VERSION ""

NS_ :

BS_:

BU_: Skylark_EV

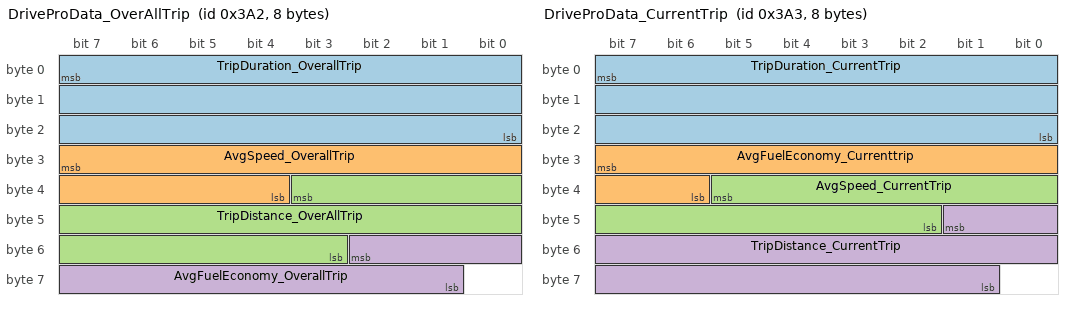
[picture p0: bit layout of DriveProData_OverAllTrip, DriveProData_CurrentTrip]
BO_ 930 DriveProData_OverAllTrip: 8 Vector__XXX
 SG_ TripDuration_OverallTrip : 7|24@0+ (1,0) [0|3600000] "sec"  Skylark_EV
 SG_ AvgSpeed_OverallTrip : 31|12@0+ (0.03125,0) [0|127.96875] "m/s"  Skylark_EV
 SG_ TripDistance_OverAllTrip : 35|17@0+ (0.1,0) [0|9999.9] "Km"  Skylark_EV
 SG_ AvgFuelEconomy_OverallTrip : 50|10@0+ (0.1,0) [0|99.9] "Km/L"  Skylark_EV

BO_ 931 DriveProData_CurrentTrip: 8 Vector__XXX
 SG_ TripDuration_CurrentTrip : 7|24@0+ (1,0) [0|3600000] "sec"  Skylark_EV
 SG_ AvgFuelEconomy_Currenttrip : 31|10@0+ (0.1,0) [0|99.9] "Km/L"  Skylark_EV
 SG_ AvgSpeed_CurrentTrip : 37|12@0+ (0.03125,0) [0|127.96875] "m/s"  Skylark_EV
 SG_ TripDistance_CurrentTrip : 41|17@0+ (0.1,0) [0|9999.9] "Km"  Skylark_EV

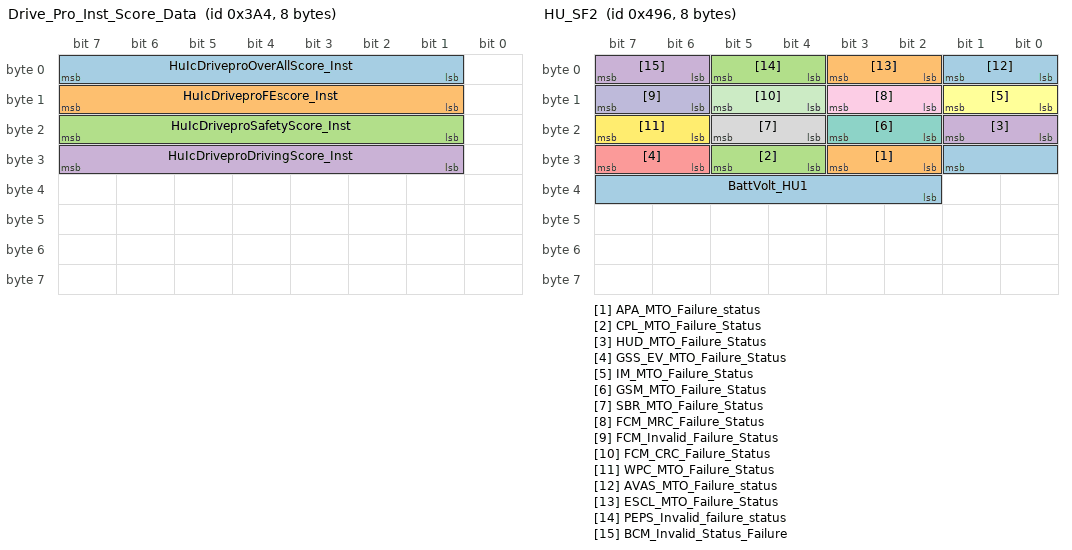
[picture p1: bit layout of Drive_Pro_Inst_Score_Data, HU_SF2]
BO_ 932 Drive_Pro_Inst_Score_Data: 8 Skylark_EV
 SG_ HuIcDriveproOverAllScore_Inst : 7|7@0+ (0.1,0) [0|10] "" Vector__XXX
 SG_ HuIcDriveproFEscore_Inst : 15|7@0+ (0.1,0) [0|10] "" Vector__XXX
 SG_ HuIcDriveproSafetyScore_Inst : 23|7@0+ (0.1,0) [0|10] "" Vector__XXX
 SG_ HuIcDriveproDrivingScore_Inst : 31|7@0+ (0.1,0) [0|10] "" Vector__XXX

BO_ 938 PEPS2_RC: 8 Vector__XXX
 SG_ LowBatUIdMsg : 2|1@0+ (1,0) [0|1] ""  Skylark_EV

BO_ 946 BCM_IC_RC4: 8 Vector__XXX
 SG_ HighBeamTelltaleStatus : 35|2@0+ (1,0) [0|3] ""  Skylark_EV
 SG_ HighBeamTelltale : 33|1@0+ (1,0) [0|1] ""  Skylark_EV
 SG_ DoorStateRearLHStatus : 1|2@0+ (1,0) [0|3] ""  Skylark_EV
 SG_ DoorStatePassStatus : 3|2@0+ (1,0) [0|3] ""  Skylark_EV
 SG_ DoorStatePass : 4|1@0+ (1,0) [0|1] ""  Skylark_EV
 SG_ DoorStateDrvrStatus : 6|2@0+ (1,0) [0|3] ""  Skylark_EV
 SG_ DoorStateDrvr : 7|1@0+ (1,0) [0|1] ""  Skylark_EV
 SG_ DoorStateRearRH : 8|1@0+ (1,0) [0|1] ""  Skylark_EV
 SG_ DoorStateRearRHStatus : 10|2@0+ (1,0) [0|3] ""  Skylark_EV
 SG_ DoorStateRearLH : 11|1@0+ (1,0) [0|1] ""  Skylark_EV
 SG_ WiperState : 14|3@0+ (1,0) [0|7] ""  Skylark_EV
 SG_ TailgateState : 15|1@0+ (1,0) [0|1] ""  Skylark_EV
 SG_ WiperStateStatus : 17|2@0+ (1,0) [0|3] ""  Skylark_EV
 SG_ TailgateStateStatus : 19|2@0+ (1,0) [0|3] ""  Skylark_EV
 SG_ PositionLmpMalFn : 20|1@0+ (1,0) [0|1] ""  Skylark_EV
 SG_ PositionLmpMalFnStatus : 23|2@0+ (1,0) [0|3] ""  Skylark_EV
 SG_ BrakeLmpMalFn : 24|1@0+ (1,0) [0|1] ""  Skylark_EV
 SG_ BrakeLmpMalFnStatus : 26|2@0+ (1,0) [0|3] ""  Skylark_EV
 SG_ RevLampMalFn : 27|1@0+ (1,0) [0|1] ""  Skylark_EV
 SG_ RevLampMalFnStatus : 29|2@0+ (1,0) [0|3] ""  Skylark_EV
 SG_ LowBeamMalFn : 32|1@0+ (1,0) [0|1] ""  Skylark_EV
 SG_ DRLTelltale : 36|1@0+ (1,0) [0|1] ""  Skylark_EV
 SG_ FrontFogTelltale : 37|1@0+ (1,0) [0|1] ""  Skylark_EV
 SG_ RearFogTelltaleStatus : 39|2@0+ (1,0) [0|3] ""  Skylark_EV
 SG_ FrontFogTelltaleStatus : 41|2@0+ (1,0) [0|3] ""  Skylark_EV
 SG_ DRLTelltaleStatus : 43|2@0+ (1,0) [0|3] ""  Skylark_EV
 SG_ LowBeamMalFnStatus : 52|2@0+ (1,0) [0|3] ""  Skylark_EV
 SG_ BonnetState : 54|1@0+ (1,0) [0|1] ""  Skylark_EV
 SG_ RearFogTelltale : 55|1@0+ (1,0) [0|1] ""  Skylark_EV
 SG_ BonnetStateStatus : 57|2@0+ (1,0) [0|3] ""  Skylark_EV

BO_ 948 IPC12: 8 Vector__XXX
 SG_ OdoICFullSigPeriodic : 7|32@0+ (1,0) [0|999999000] "m"  Skylark_EV
 SG_ OdoICFullSigPeriodicStatus : 33|2@0+ (1,0) [0|3] ""  Skylark_EV

BO_ 1068 IPC7: 8 Vector__XXX
 SG_ ICDrvModeFunVariant : 47|16@0+ (1,0) [0|65535] ""  Skylark_EV

BO_ 1069 IPC9: 8 Vector__XXX
 SG_ IcHuVcInfonew : 7|64@0+ (1,0) [0|1.8446744074E+019] ""  Skylark_EV

BO_ 1120 HU6: 8 Skylark_EV
 SG_ HuIcTpSig : 7|64@0+ (1,0) [0|1.844674407371E+019] "" Vector__XXX

BO_ 1121 IPC13: 8 Vector__XXX
 SG_ IcHuTpSig : 7|64@0+ (1,0) [0|1.844674407371E+019] ""  Skylark_EV

BO_ 1173 HU_SF: 8 Skylark_EV
 SG_ SRR_MTO_Failure_Status : 63|2@0+ (1,0) [0|3] "" Vector__XXX
 SG_ FCmMToFailureStatus : 35|2@0+ (1,0) [0|3] "" Vector__XXX
 SG_ Telematics_Invalid_FailureStatus : 29|2@0+ (1,0) [0|3] "" Vector__XXX
 SG_ VCUMToFailureStatus : 19|2@0+ (1,0) [0|3] "" Vector__XXX
 SG_ VCUInvalidFailureStatus : 23|2@0+ (1,0) [0|3] "" Vector__XXX
 SG_ Telematics_MTO_Failure_status : 13|2@0+ (1,0) [0|3] "" Vector__XXX
 SG_ HU_SW_Version : 7|8@0+ (1,0) [0|255] "" Vector__XXX
 SG_ EMsInvalidFailureStatus : 9|2@0+ (1,0) [0|3] "" Vector__XXX
 SG_ AMT_AT_DCT_MTO_Failure_Status : 11|2@0+ (1,0) [0|3] "" Vector__XXX
 SG_ AMT_AT_DCT_Invalid_Failure_Statu : 15|2@0+ (1,0) [0|3] "" Vector__XXX
 SG_ ESpMToFailureStatus : 17|2@0+ (1,0) [0|3] "" Vector__XXX
 SG_ ESpInvalidFailureStatus : 21|2@0+ (1,0) [0|3] "" Vector__XXX
 SG_ CCM_Invalid_Failure_Status : 25|2@0+ (1,0) [0|3] "" Vector__XXX
 SG_ SRS_MTO_Failure_Status : 27|2@0+ (1,0) [0|3] "" Vector__XXX
 SG_ EMsMToFailureStatus : 31|2@0+ (1,0) [0|3] "" Vector__XXX
 SG_ PDC_MTO_Failure_Status : 33|2@0+ (1,0) [0|3] "" Vector__XXX
 SG_ IPcMToFailureStatus : 37|2@0+ (1,0) [0|3] "" Vector__XXX
 SG_ IPcInvalidFailureStatus : 39|2@0+ (1,0) [0|3] "" Vector__XXX
 SG_ PDC_Invalid_Failure_Status : 41|2@0+ (1,0) [0|3] "" Vector__XXX
 SG_ SAS_Invalid_Failure_Status : 43|2@0+ (1,0) [0|3] "" Vector__XXX
 SG_ SAS_MTO_Failure_Status : 45|2@0+ (1,0) [0|3] "" Vector__XXX
 SG_ EPAS_MTO_Failure_Status : 47|2@0+ (1,0) [0|3] "" Vector__XXX
 SG_ EPAS_Invalid_Failure_Status : 49|2@0+ (1,0) [0|3] "" Vector__XXX
 SG_ TPMS_MTO_Failure_status : 51|2@0+ (1,0) [0|3] "" Vector__XXX
 SG_ CCM_MTO_Failure_Status : 53|2@0+ (1,0) [0|3] "" Vector__XXX
 SG_ HU_EP_Failure_Status : 55|2@0+ (1,0) [0|3] "" Vector__XXX
 SG_ PEPS_MTO_Failure_Status : 57|2@0+ (1,0) [0|3] "" Vector__XXX
 SG_ BCmMToFailureStatus : 59|2@0+ (1,0) [0|3] "" Vector__XXX
 SG_ HU_BO_Failure_Status : 61|2@0+ (1,0) [0|3] "" Vector__XXX

BO_ 1174 HU_SF2: 8 Skylark_EV
 SG_ BattVolt_HU1 : 25|8@0+ (0.1,0) [0|25] "Volts" Vector__XXX
 SG_ APA_MTO_Failure_status : 27|2@0+ (1,0) [0|3] "" Vector__XXX
 SG_ CPL_MTO_Failure_Status : 29|2@0+ (1,0) [0|3] "" Vector__XXX
 SG_ HUD_MTO_Failure_Status : 17|2@0+ (1,0) [0|3] "" Vector__XXX
 SG_ GSS_EV_MTO_Failure_Status : 31|2@0+ (1,0) [0|3] "" Vector__XXX
 SG_ IM_MTO_Failure_Status : 9|2@0+ (1,0) [0|3] "" Vector__XXX
 SG_ GSM_MTO_Failure_Status : 19|2@0+ (1,0) [0|3] "" Vector__XXX
 SG_ SBR_MTO_Failure_Status : 21|2@0+ (1,0) [0|3] "" Vector__XXX
 SG_ FCM_MRC_Failure_Status : 11|2@0+ (1,0) [0|3] "" Vector__XXX
 SG_ FCM_Invalid_Failure_Status : 15|2@0+ (1,0) [0|3] "" Vector__XXX
 SG_ FCM_CRC_Failure_Status : 13|2@0+ (1,0) [0|3] "" Vector__XXX
 SG_ WPC_MTO_Failure_Status : 23|2@0+ (1,0) [0|3] "" Vector__XXX
 SG_ AVAS_MTO_Failure_status : 1|2@0+ (1,0) [0|3] "" Vector__XXX
 SG_ ESCL_MTO_Failure_Status : 3|2@0+ (1,0) [0|3] "" Vector__XXX
 SG_ PEPS_Invalid_failure_status : 5|2@0+ (1,0) [0|3] "" Vector__XXX
 SG_ BCM_Invalid_Status_Failure : 7|2@0+ (1,0) [0|3] "" Vector__XXX

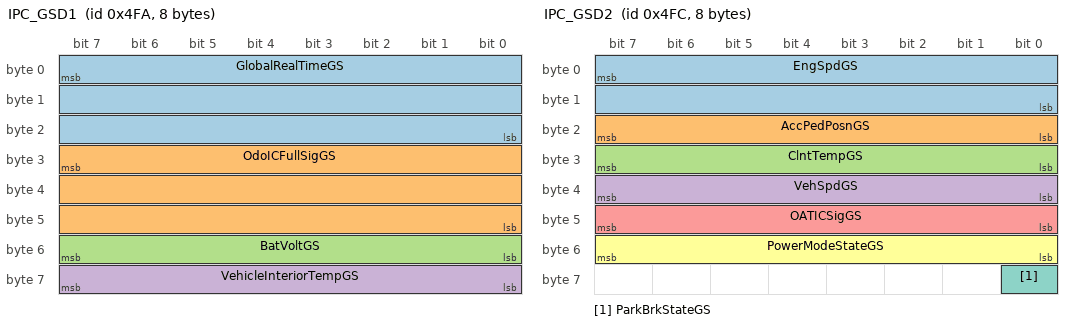
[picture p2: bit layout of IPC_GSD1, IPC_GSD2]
BO_ 1274 IPC_GSD1: 8 Vector__XXX
 SG_ GlobalRealTimeGS : 7|24@0+ (1,0) [0|16777214] "min"  Skylark_EV
 SG_ OdoICFullSigGS : 31|24@0+ (1,0) [0|16777214] "km"  Skylark_EV
 SG_ BatVoltGS : 55|8@0+ (0.1,0) [0|25.4] "V"  Skylark_EV
 SG_ VehicleInteriorTempGS : 63|8@0+ (1,-40) [-40|214] "Deg"  Skylark_EV

BO_ 1276 IPC_GSD2: 8 Vector__XXX
 SG_ EngSpdGS : 7|16@0+ (1,0) [0|65534] "rpm"  Skylark_EV
 SG_ AccPedPosnGS : 23|8@0+ (0.5,0) [0|127] "%"  Skylark_EV
 SG_ ClntTempGS : 31|8@0+ (1,-40) [-40|214] "Deg"  Skylark_EV
 SG_ VehSpdGS : 39|8@0+ (1,0) [0|254] "km/h"  Skylark_EV
 SG_ OATICSigGS : 47|8@0+ (1,-40) [-40|214] "Deg"  Skylark_EV
 SG_ PowerModeStateGS : 55|8@0+ (1,0) [0|255] ""  Skylark_EV
 SG_ ParkBrkStateGS : 56|1@0+ (1,0) [0|1] ""  Skylark_EV

BO_ 1278 IPC_GSD3: 8 Vector__XXX
 SG_ VehIdetNumGS : 7|40@0+ (1,0) [0|0] ""  Skylark_EV

BO_ 1280 BCM_NMPDU: 8 Vector__XXX
 SG_ BCM_NMPDU_SRC_ECU_ID : 7|8@0+ (1,0) [0|255] ""  Skylark_EV
 SG_ RepeatMessageReq_BCM : 8|1@0+ (1,0) [0|1] ""  Skylark_EV
 SG_ Reserved0 : 9|1@0+ (1,0) [0|1] ""  Skylark_EV
 SG_ Reserved1 : 10|1@0+ (1,0) [0|1] ""  Skylark_EV
 SG_ NMCoOrdSlpReady_BCM : 11|1@0+ (1,0) [0|1] ""  Skylark_EV
 SG_ ActiveWakeUp_BCM : 12|1@0+ (1,0) [0|1] ""  Skylark_EV
 SG_ Reserved2 : 13|1@0+ (1,0) [0|1] ""  Skylark_EV
 SG_ PartialNetworkInformation_BCM : 14|1@0+ (1,0) [0|1] ""  Skylark_EV
 SG_ Reserved3 : 15|1@0+ (1,0) [0|1] ""  Skylark_EV
 SG_ CurrentState_BCM : 16|1@0+ (1,0) [0|1] ""  Skylark_EV
 SG_ PreviousState_BCM : 19|3@0+ (1,0) [0|7] ""  Skylark_EV
 SG_ Reserved4 : 20|1@0+ (1,0) [0|1] ""  Skylark_EV
 SG_ Reserved5 : 21|1@0+ (1,0) [0|1] ""  Skylark_EV
 SG_ Reserved6 : 22|1@0+ (1,0) [0|1] ""  Skylark_EV
 SG_ Reserved7 : 23|1@0+ (1,0) [0|1] ""  Skylark_EV
 SG_ BCM_NMPDU_USER_DATA_D1 : 31|8@0+ (1,0) [0|255] ""  Skylark_EV
 SG_ BCM_NMPDU_USER_DATA_D2 : 39|8@0+ (1,0) [0|255] ""  Skylark_EV
 SG_ BCM_NMPDU_USER_DATA_D3 : 47|8@0+ (1,0) [0|255] ""  Skylark_EV
 SG_ BCM_NMPDU_USER_DATA_D4 : 55|8@0+ (1,0) [0|255] ""  Skylark_EV
 SG_ BCM_NMPDU_USER_DATA_D5 : 63|8@0+ (1,0) [0|255] ""  Skylark_EV

BO_ 1282 HU_NMPDU: 8 Skylark_EV
 SG_ HU_NMPDU_SRC_ECU_ID : 7|8@0+ (1,0) [0|255] "" Vector__XXX
 SG_ RepeatMessageReq_HU : 8|1@0+ (1,0) [0|1] "" Vector__XXX
 SG_ Reserved8 : 9|1@0+ (1,0) [0|1] "" Vector__XXX
 SG_ Reserved9 : 10|1@0+ (1,0) [0|1] "" Vector__XXX
 SG_ NMCoOrdSlpReady_HU : 11|1@0+ (1,0) [0|1] "" Vector__XXX
 SG_ ActiveWakeUp_HU : 12|1@0+ (1,0) [0|1] "" Vector__XXX
 SG_ Reserved10 : 13|1@0+ (1,0) [0|1] "" Vector__XXX
 SG_ PartialNetworkInformation_HU : 14|1@0+ (1,0) [0|1] "" Vector__XXX
 SG_ Reserved11 : 15|1@0+ (1,0) [0|1] "" Vector__XXX
 SG_ CurrentState_HU : 16|1@0+ (1,0) [0|1] "" Vector__XXX
 SG_ PreviousState_HU : 19|3@0+ (1,0) [0|7] "" Vector__XXX
 SG_ Reserved12 : 20|1@0+ (1,0) [0|1] "" Vector__XXX
 SG_ Reserved13 : 21|1@0+ (1,0) [0|1] "" Vector__XXX
 SG_ Reserved14 : 22|1@0+ (1,0) [0|1] "" Vector__XXX
 SG_ Reserved15 : 23|1@0+ (1,0) [0|1] "" Vector__XXX
 SG_ HU_NMPDU_USER_DATA_1 : 31|8@0+ (1,0) [0|255] "" Vector__XXX
 SG_ HU_NMPDU_USER_DATA_2 : 39|8@0+ (1,0) [0|255] "" Vector__XXX
 SG_ HU_NMPDU_USER_DATA_3 : 47|8@0+ (1,0) [0|255] "" Vector__XXX
 SG_ HU_NMPDU_USER_DATA_4 : 55|8@0+ (1,0) [0|255] "" Vector__XXX
 SG_ HU_NMPDU_USER_DATA_5 : 63|8@0+ (1,0) [0|255] "" Vector__XXX

BO_ 1547 HU_DiagResponse_UUDT: 8 Skylark_EV
 SG_ HU_DiagResponse_UUDT : 7|64@0+ (1,0) [0|0] "" Vector__XXX

BO_ 1795 HU_DiagRequest: 8 Vector__XXX
 SG_ DiagMsg : 7|64@0+ (1,0) [0|0] ""  Skylark_EV

BO_ 1803 HU_DiagResponse_USDT: 8 Skylark_EV
 SG_ HU_DiagResponse_USDT : 7|64@0+ (1,0) [0|0] "" Vector__XXX

BO_ 2000 DiagState1: 8 Vector__XXX
 SG_ DiagMsg : 7|64@0+ (1,0) [0|0] ""  Skylark_EV

BO_ 2001 DiagState2: 8 Vector__XXX
 SG_ DiagMsg : 7|64@0+ (1,0) [0|0] ""  Skylark_EV

BO_ 2015 DiagState3: 8 Vector__XXX
 SG_ DiagMsg : 7|64@0+ (1,0) [0|0] ""  Skylark_EV

CM_ SG_ 930 TripDuration_OverallTrip "IC shall send overall Trip Duration to HU";
CM_ SG_ 930 AvgSpeed_OverallTrip "IC shall send Overall Trip  Average speed to HU";
CM_ SG_ 930 TripDistance_OverAllTrip "IC shall send Over allTrip  Distance to HU";
CM_ SG_ 930 AvgFuelEconomy_OverallTrip "IC shall send Over all trip Average  Fuel Economy to HU";
CM_ SG_ 931 TripDuration_CurrentTrip "IC shall send Current Trip Duration to HU";
CM_ SG_ 931 AvgFuelEconomy_Currenttrip "IC shall send Current Trip Fuel Economy to HU";
CM_ SG_ 931 AvgSpeed_CurrentTrip "IC shall send Current Trip Average speed to HU";
CM_ SG_ 931 TripDistance_CurrentTrip "IC shall send Current Trip Distance to HU";
CM_ SG_ 932 HuIcDriveproOverAllScore_Inst "HU shall send Overall trip Reset to IC";
CM_ SG_ 932 HuIcDriveproFEscore_Inst "Drive Pro Instantaneous Trip Data fron HU to IC";
CM_ SG_ 932 HuIcDriveproSafetyScore_Inst "Drive Pro Instantaneous Trip Data fron HU to IC";
CM_ SG_ 932 HuIcDriveproDrivingScore_Inst "Drive Pro Instantaneous score from HU to IC";
CM_ SG_ 938 LowBatUIdMsg "Display message request from PEPS to IC & HU - UID battery is low";
CM_ SG_ 946 HighBeamTelltaleStatus "Status of the High Beam Telltale";
CM_ SG_ 946 HighBeamTelltale "IC to display the high beam tell-tale when the high beam lamp is active";
CM_ SG_ 946 DoorStateRearLHStatus "Rear left side door valid Status





";
CM_ SG_ 946 DoorStatePassStatus "Driver Door Passenger valid Status";
CM_ SG_ 946 DoorStatePass "Co-Driver door switch state from BCM ";
CM_ SG_ 946 DoorStateDrvrStatus "DoorStateDrvr valid Status";
CM_ SG_ 946 DoorStateDrvr "Driver door switch state from BCM ";
CM_ SG_ 946 DoorStateRearRH "Rear right side door switch state from BCM to FATC and IC";
CM_ SG_ 946 DoorStateRearRHStatus "Rear right side door valid status



";
CM_ SG_ 946 DoorStateRearLH "Rear left side door switch state from BCM";
CM_ SG_ 946 WiperState "Status of the Wiper to various ECUs";
CM_ SG_ 946 TailgateState "Tailgate switch state (open or close) from BCM to various ECUs";
CM_ SG_ 946 WiperStateStatus "Status of the Wiper whether Valid or not";
CM_ SG_ 946 TailgateStateStatus "Tailgate switch state vaild status";
CM_ SG_ 946 PositionLmpMalFn "IC to display the message when failure in Position lamp";
CM_ SG_ 946 PositionLmpMalFnStatus "Status of the Malfunction Position Lamp";
CM_ SG_ 946 BrakeLmpMalFn "IC to display the message when failure in brake lamp";
CM_ SG_ 946 BrakeLmpMalFnStatus "Status of the Malfunction Break Lamp





";
CM_ SG_ 946 RevLampMalFn "IC to display the message when failure in reverse lamp";
CM_ SG_ 946 RevLampMalFnStatus "Status of the Malfunction Reverse Lamp";
CM_ SG_ 946 LowBeamMalFn "IC to display the message when failure in low beam lamp";
CM_ SG_ 946 DRLTelltale "IC to display the Daytime Running Light (DRL) telltale";
CM_ SG_ 946 FrontFogTelltale "IC to display the front fog tell-tale when the front fog lamp is active";
CM_ SG_ 946 RearFogTelltaleStatus "Status of the Rear Fog Telltale";
CM_ SG_ 946 FrontFogTelltaleStatus "Status of the Front Fog Telltale";
CM_ SG_ 946 DRLTelltaleStatus "Status of the Daytime Running Light (DRL) telltale";
CM_ SG_ 946 LowBeamMalFnStatus "Status of the Low Beam Malfunction";
CM_ SG_ 946 BonnetState "Bonnet switch state (open or close) from BCM";
CM_ SG_ 946 RearFogTelltale "IC to display the rear fog tell-tale when the rear fog lamp is active";
CM_ SG_ 946 BonnetStateStatus "BonnetState vaild status";
CM_ SG_ 948 OdoICFullSigPeriodic "Signal represents Odometer information in full range.";
CM_ SG_ 948 OdoICFullSigPeriodicStatus "Status of Signal representing Odometer information in full range.";
CM_ SG_ 1068 ICDrvModeFunVariant "Indicates the type of drive mode available in vehicle.";
CM_ SG_ 1069 IcHuVcInfonew "VC number of vehicle.";
CM_ BO_ 1120 "CAN TP Message";
CM_ BO_ 1121 "CAN TP Message";
CM_ BO_ 1173 "Supervision frame transmitted by HU";
CM_ SG_ 1173 SRR_MTO_Failure_Status "Status of the SRR  Message timeout  failure detected as per Tata-IVN_Specification_Network_Management.";
CM_ SG_ 1173 FCmMToFailureStatus "Status of the FCM Message timeout  failure detected as per Tata-IVN_Specification_Network_Management.";
CM_ SG_ 1173 Telematics_Invalid_FailureStatus "Status of the Telematics Invalid failure detected as per Tata-IVN_Specification_Network_Management.";
CM_ SG_ 1173 VCUMToFailureStatus "VCUMTO failure status";
CM_ SG_ 1173 VCUInvalidFailureStatus "VCU invalid failure status";
CM_ SG_ 1173 Telematics_MTO_Failure_status "Status of the Telematics Message timeout failure detected as per Tata-IVN_Specification_Network_Management.";
CM_ SG_ 1173 HU_SW_Version "SW Version of the HU ECU";
CM_ SG_ 1173 EMsInvalidFailureStatus "status of the EMS Invalid  signal  failure detected as per Tata-IVN_Specification_Network_Management.";
CM_ SG_ 1173 AMT_AT_DCT_MTO_Failure_Status "Status of the TCM Message Timeout  failure detected as per Tata-IVN_Specification_Network_Management.";
CM_ SG_ 1173 AMT_AT_DCT_Invalid_Failure_Statu "Status of the TCM invalid failure detected as per Tata-IVN_Specification_Network_Management.";
CM_ SG_ 1173 ESpMToFailureStatus "Status of the ESP  Message timeout failure detected as per Tata-IVN_Specification_Network_Management.";
CM_ SG_ 1173 ESpInvalidFailureStatus "Status of the ESP signal implausible  failure detected  by EPAS  as per  communication layer spec";
CM_ SG_ 1173 CCM_Invalid_Failure_Status "Status of the  FATC Invalid  signal  failure detected as per Tata-IVN_Specification_Network_Management.";
CM_ SG_ 1173 SRS_MTO_Failure_Status "Status of the SRS  Message timeout  failure detected as per Tata-IVN_Specification_Network_Management.";
CM_ SG_ 1173 EMsMToFailureStatus "Status of the EMS message timeout failure detected as per Tata-IVN_Specification_Network_Management.";
CM_ SG_ 1173 PDC_MTO_Failure_Status "Status of the PDC Message timeout failure detected as per Tata-IVN_Specification_Network_Management.";
CM_ SG_ 1173 IPcMToFailureStatus "Status of the IPC Message Timeout  failure detected as per Tata-IVN_Specification_Network_Management.";
CM_ SG_ 1173 IPcInvalidFailureStatus "Status of the IC Invalid  signal  failure detected as per Tata-IVN_Specification_Network_Management.";
CM_ SG_ 1173 PDC_Invalid_Failure_Status "status of the PDC Invalid  signal  failure detected as per communication layer specification.";
CM_ SG_ 1173 SAS_Invalid_Failure_Status "status of the SAS Invalid  signal  failure detected as per Tata-IVN_Specification_Network_Management.";
CM_ SG_ 1173 SAS_MTO_Failure_Status "Status of the SAS  Message timeout  failure detected as per Tata-IVN_Specification_Network_Management.";
CM_ SG_ 1173 EPAS_MTO_Failure_Status "Status of the EPAS  Message timeout failure detected as per Tata-IVN_Specification_Network_Management.";
CM_ SG_ 1173 EPAS_Invalid_Failure_Status "Status of the EPAS signal implausible  failure detected    as per  communication layer spec";
CM_ SG_ 1173 TPMS_MTO_Failure_status "Message timeout failure flag against TPMS ECU";
CM_ SG_ 1173 CCM_MTO_Failure_Status "Status of the FATC Message timeout failure detected as per Tata-IVN_Specification_Network_Management.";
CM_ SG_ 1173 HU_EP_Failure_Status "Status of the error passive detected by HU ECU as per Tata-IVN_Specification_Network_Management.";
CM_ SG_ 1173 PEPS_MTO_Failure_Status "Status of the PEPS  Message timeout  failure detected as per Tata-IVN_Specification_Network_Management.";
CM_ SG_ 1173 BCmMToFailureStatus "Status of the BCM Message timeout  failure detected as per Tata-IVN_Specification_Network_Management.";
CM_ SG_ 1173 HU_BO_Failure_Status "Status of the bus-off failure detected by HU ECU as per Tata-IVN_Specification_Network_Management";
CM_ SG_ 1174 BattVolt_HU1 "Battery voltage evaluated by HU";
CM_ SG_ 1174 APA_MTO_Failure_status "Message timeout failure flag against APA ECU";
CM_ SG_ 1174 CPL_MTO_Failure_Status "Status of the CPL Message timeout  failure detected as per Tata-IVN_Specification_Network_Management.";
CM_ SG_ 1174 HUD_MTO_Failure_Status "Status of the HUD Message timeout  failure detected as per Tata-IVN_Specification_Network_Management.";
CM_ SG_ 1174 GSS_EV_MTO_Failure_Status "Status of the GSS Message timeout  failure detected as per Tata-IVN_Specification_Network_Management.";
CM_ SG_ 1174 IM_MTO_Failure_Status "Status of the IM Message timeout  failure detected as per Tata-IVN_Specification_Network_Management.";
CM_ SG_ 1174 GSM_MTO_Failure_Status "Status of the GSM Message timeout  failure detected as per Tata-IVN_Specification_Network_Management.";
CM_ SG_ 1174 SBR_MTO_Failure_Status "Status of the SBR Message timeout  failure detected as per Tata-IVN_Specification_Network_Management.";
CM_ SG_ 1174 FCM_Invalid_Failure_Status "Status of the FCM signal implausible  failure detected  by CDC as per  communication layer spec";
CM_ SG_ 1174 WPC_MTO_Failure_Status "Status of the WPC Message timeout  failure detected as per Tata-IVN_Specification_Network_Management.";
CM_ SG_ 1174 AVAS_MTO_Failure_status "Message timeout failure flag against AVAS ECU";
CM_ SG_ 1174 PEPS_Invalid_failure_status "Status of the PEPS invalid failure detected as per Tata-IVN_Specification_Network_Management.";
CM_ SG_ 1174 BCM_Invalid_Status_Failure "Invalid data reception from BCM ECU failure flag";
CM_ SG_ 1274 GlobalRealTimeGS "Global Real Time
";
CM_ SG_ 1274 OdoICFullSigGS "Total Distance Travelled";
CM_ SG_ 1274 BatVoltGS "Supply Voltage of Instrument Cluster";
CM_ SG_ 1274 VehicleInteriorTempGS "Vehicle Interior Temperature
";
CM_ SG_ 1276 EngSpdGS "Engine RPM signal will be transmitted by EMS
";
CM_ SG_ 1276 AccPedPosnGS "Throttle Position";
CM_ SG_ 1276 ClntTempGS "Engine Coolant Temperature";
CM_ SG_ 1276 VehSpdGS "Vehicle Speed";
CM_ SG_ 1276 OATICSigGS "Ambient Air Temperature";
CM_ SG_ 1276 PowerModeStateGS "Vehicle power mode signal shall be used by all ECUs of the vehicle for their respective functional implementation";
CM_ SG_ 1276 ParkBrkStateGS "Signal represents Status of ParkBrake";
CM_ SG_ 1278 VehIdetNumGS "Vehicle Identification Number - Last 5 digits of VIN";
BA_DEF_ SG_  "Remarks" STRING ;
BA_DEF_ SG_  "NWM_WakeupAllowed" ENUM  "No","Yes";
BA_DEF_ SG_  "GenSigTimeoutTime_HU_Mid_X451" INT 0 65535;
BA_DEF_ SG_  "GenSigTimeoutTime_HU_High_X451" INT 0 65535;
BA_DEF_ SG_  "GenSigTimeoutTime_HU_B" INT 0 65535;
BA_DEF_ SG_  "GenSigTimeoutTime_HU_A" INT 0 65535;
BA_DEF_ SG_  "GenSigTimeoutTime_BCM_Mid" INT 0 65535;
BA_DEF_ SG_  "GenSigTimeoutMsg_HU_Mid_X451" INT 0 65535;
BA_DEF_ SG_  "GenSigTimeoutMsg_HU_High_X451" INT 0 65535;
BA_DEF_ SG_  "GenSigTimeoutMsg_HU_B" INT 0 65535;
BA_DEF_ SG_  "GenSigTimeoutMsg_HU_A" INT 0 65535;
BA_DEF_ SG_  "GenSigStartValue" INT 0 0;
BA_DEF_ SG_  "GenSigSendType" ENUM  "Cyclic","OnWrite","OnWriteWithRepetition","OnChange","OnChangeWithRepetition","IfActive","IfActiveWithRepetition","NoSigSendType","NotUsed","NotUsed","NotUsed","NotUsed","NotUsed";
BA_DEF_ SG_  "GenSigInactiveValue" INT 0 0;
BA_DEF_ SG_  "GenSigEnvVarType" ENUM  "int","float","undef";
BA_DEF_ SG_  "GenSigCycleTimeActive" INT 0 0;
BA_DEF_ SG_  "GenSigCycleTime" INT 0 0;
BA_DEF_ SG_  "GenSigTimeoutMsg_HU_High_X445" INT 0 65535;
BA_DEF_ SG_  "GenSigTimeoutMsg_HU_Mid_X445" INT 0 65535;
BA_DEF_ SG_  "GenSigTimeoutTime_HU_High_X445" INT 0 65535;
BA_DEF_ SG_  "GenSigTimeoutTime_HU_Mid_X445" INT 0 65535;
BA_DEF_ SG_  "GenSigTimeoutMsg_IVI" INT 0 65535;
BA_DEF_ SG_  "GenSigTimeoutTime_IVI" INT 0 65535;
BA_DEF_ BO_  "NmMessage" ENUM  "no","yes";
BA_DEF_ BO_  "NmAsrMessage" ENUM  "<n.a.>","No","Yes";
BA_DEF_ BO_  "MessageTimeout" INT 0 65535;
BA_DEF_ BO_  "GenMsgStartDelayTime" INT 0 0;
BA_DEF_ BO_  "GenMsgSendType" ENUM  "Cyclic","NotUsed","NotUsed","NotUsed","NotUsed","NotUsed","NotUsed","IfActive","NoMsgSendType","NotUsed";
BA_DEF_ BO_  "GenMsgNrOfRepetition" INT 0 0;
BA_DEF_ BO_  "GenMsgILSupport" ENUM  "No","Yes";
BA_DEF_ BO_  "GenMsgDelayTime" INT 0 0;
BA_DEF_ BO_  "GenMsgCycleTimeFast" INT 0 0;
BA_DEF_ BO_  "GenMsgCycleTime" INT 0 0;
BA_DEF_ BO_  "DiagUudtResponse" ENUM  "false","true";
BA_DEF_ BO_  "DiagUsdtResponse" ENUM  "false","true";
BA_DEF_ BO_  "DiagState" ENUM  "No","Yes";
BA_DEF_ BO_  "DiagResponse" ENUM  "No","Yes";
BA_DEF_ BO_  "DiagRequest" ENUM  "No","Yes";
BA_DEF_ BO_  "MsgType" ENUM  "Application","NM","NMH";
BA_DEF_ SG_  "SystemSignalLongSymbol" STRING ;
BA_DEF_DEF_  "Remarks" "null";
BA_DEF_DEF_  "NWM_WakeupAllowed" "No";
BA_DEF_DEF_  "GenSigTimeoutTime_HU_Mid_X451" 500;
BA_DEF_DEF_  "GenSigTimeoutTime_HU_High_X451" 500;
BA_DEF_DEF_  "GenSigTimeoutTime_HU_B" 500;
BA_DEF_DEF_  "GenSigTimeoutTime_HU_A" 500;
BA_DEF_DEF_  "GenSigTimeoutTime_BCM_Mid" 0;
BA_DEF_DEF_  "GenSigTimeoutMsg_HU_Mid_X451" 500;
BA_DEF_DEF_  "GenSigTimeoutMsg_HU_High_X451" 500;
BA_DEF_DEF_  "GenSigTimeoutMsg_HU_B" 500;
BA_DEF_DEF_  "GenSigTimeoutMsg_HU_A" 500;
BA_DEF_DEF_  "GenSigStartValue" 0;
BA_DEF_DEF_  "GenSigSendType" "Cyclic";
BA_DEF_DEF_  "GenSigInactiveValue" 0;
BA_DEF_DEF_  "GenSigEnvVarType" "undef";
BA_DEF_DEF_  "GenSigCycleTimeActive" 0;
BA_DEF_DEF_  "GenSigCycleTime" 0;
BA_DEF_DEF_  "GenSigTimeoutMsg_HU_High_X445" 500;
BA_DEF_DEF_  "GenSigTimeoutMsg_HU_Mid_X445" 500;
BA_DEF_DEF_  "GenSigTimeoutTime_HU_High_X445" 500;
BA_DEF_DEF_  "GenSigTimeoutTime_HU_Mid_X445" 500;
BA_DEF_DEF_  "GenSigTimeoutMsg_IVI" 500;
BA_DEF_DEF_  "GenSigTimeoutTime_IVI" 500;
BA_DEF_DEF_  "NmMessage" "no";
BA_DEF_DEF_  "NmAsrMessage" "<n.a.>";
BA_DEF_DEF_  "MessageTimeout" 500;
BA_DEF_DEF_  "GenMsgStartDelayTime" 0;
BA_DEF_DEF_  "GenMsgSendType" "Cyclic";
BA_DEF_DEF_  "GenMsgNrOfRepetition" 0;
BA_DEF_DEF_  "GenMsgILSupport" "Yes";
BA_DEF_DEF_  "GenMsgDelayTime" 0;
BA_DEF_DEF_  "GenMsgCycleTimeFast" 0;
BA_DEF_DEF_  "GenMsgCycleTime" 0;
BA_DEF_DEF_  "DiagUudtResponse" "false";
BA_DEF_DEF_  "DiagUsdtResponse" "false";
BA_DEF_DEF_  "DiagState" "No";
BA_DEF_DEF_  "DiagResponse" "No";
BA_DEF_DEF_  "DiagRequest" "No";
BA_DEF_DEF_  "MsgType" "Application";
BA_DEF_DEF_  "SystemSignalLongSymbol" "";
BA_ "MessageTimeout" BO_ 930 2500;
BA_ "GenMsgCycleTime" BO_ 930 500;
BA_ "MessageTimeout" BO_ 931 2500;
BA_ "GenMsgCycleTime" BO_ 931 500;
BA_ "MessageTimeout" BO_ 932 2500;
BA_ "GenMsgCycleTime" BO_ 932 500;
BA_ "MessageTimeout" BO_ 938 2500;
BA_ "GenMsgStartDelayTime" BO_ 938 5;
BA_ "GenMsgCycleTime" BO_ 938 500;
BA_ "MessageTimeout" BO_ 946 2500;
BA_ "GenMsgCycleTime" BO_ 946 500;
BA_ "MessageTimeout" BO_ 948 2500;
BA_ "GenMsgCycleTime" BO_ 948 500;
BA_ "MessageTimeout" BO_ 1068 5000;
BA_ "GenMsgCycleTime" BO_ 1068 1000;
BA_ "MessageTimeout" BO_ 1069 5000;
BA_ "GenMsgCycleTime" BO_ 1069 1000;
BA_ "MessageTimeout" BO_ 1120 0;
BA_ "GenMsgSendType" BO_ 1120 8;
BA_ "GenMsgILSupport" BO_ 1120 0;
BA_ "DiagRequest" BO_ 1120 1;
BA_ "MessageTimeout" BO_ 1121 0;
BA_ "GenMsgSendType" BO_ 1121 8;
BA_ "GenMsgILSupport" BO_ 1121 0;
BA_ "DiagResponse" BO_ 1121 1;
BA_ "MessageTimeout" BO_ 1173 0;
BA_ "GenMsgCycleTime" BO_ 1173 100;
BA_ "MessageTimeout" BO_ 1174 0;
BA_ "GenMsgCycleTime" BO_ 1174 100;
BA_ "MessageTimeout" BO_ 1274 5000;
BA_ "GenMsgCycleTime" BO_ 1274 1000;
BA_ "MessageTimeout" BO_ 1276 5000;
BA_ "GenMsgStartDelayTime" BO_ 1276 45;
BA_ "GenMsgCycleTime" BO_ 1276 1000;
BA_ "MessageTimeout" BO_ 1278 5000;
BA_ "GenMsgCycleTime" BO_ 1278 1000;
BA_ "NmMessage" BO_ 1280 1;
BA_ "NmAsrMessage" BO_ 1280 2;
BA_ "MessageTimeout" BO_ 1280 1000;
BA_ "GenMsgCycleTime" BO_ 1280 200;
BA_ "NmMessage" BO_ 1282 1;
BA_ "NmAsrMessage" BO_ 1282 2;
BA_ "MessageTimeout" BO_ 1282 1000;
BA_ "GenMsgCycleTime" BO_ 1282 200;
BA_ "MessageTimeout" BO_ 1547 0;
BA_ "GenMsgSendType" BO_ 1547 8;
BA_ "GenMsgILSupport" BO_ 1547 0;
BA_ "DiagUudtResponse" BO_ 1547 1;
BA_ "DiagResponse" BO_ 1547 1;
BA_ "MessageTimeout" BO_ 1795 0;
BA_ "GenMsgSendType" BO_ 1795 8;
BA_ "GenMsgILSupport" BO_ 1795 0;
BA_ "DiagRequest" BO_ 1795 1;
BA_ "MessageTimeout" BO_ 1803 0;
BA_ "GenMsgSendType" BO_ 1803 8;
BA_ "GenMsgILSupport" BO_ 1803 0;
BA_ "DiagResponse" BO_ 1803 1;
BA_ "MessageTimeout" BO_ 2000 0;
BA_ "GenMsgSendType" BO_ 2000 8;
BA_ "GenMsgILSupport" BO_ 2000 0;
BA_ "DiagState" BO_ 2000 1;
BA_ "MessageTimeout" BO_ 2001 0;
BA_ "GenMsgSendType" BO_ 2001 8;
BA_ "GenMsgILSupport" BO_ 2001 0;
BA_ "DiagState" BO_ 2001 1;
BA_ "MessageTimeout" BO_ 2015 0;
BA_ "GenMsgSendType" BO_ 2015 8;
BA_ "GenMsgILSupport" BO_ 2015 0;
BA_ "DiagState" BO_ 2015 1;
BA_ "GenSigTimeoutTime_HU_Mid_X451" SG_ 930 TripDuration_OverallTrip 2500;
BA_ "GenSigTimeoutTime_HU_High_X451" SG_ 930 TripDuration_OverallTrip 2500;
BA_ "GenSigTimeoutTime_HU_B" SG_ 930 TripDuration_OverallTrip 2500;
BA_ "GenSigTimeoutTime_HU_A" SG_ 930 TripDuration_OverallTrip 2500;
BA_ "GenSigTimeoutMsg_HU_Mid_X451" SG_ 930 TripDuration_OverallTrip 2500;
BA_ "GenSigTimeoutMsg_HU_High_X451" SG_ 930 TripDuration_OverallTrip 2500;
BA_ "GenSigTimeoutMsg_HU_B" SG_ 930 TripDuration_OverallTrip 2500;
BA_ "GenSigTimeoutMsg_HU_A" SG_ 930 TripDuration_OverallTrip 2500;
BA_ "GenSigSendType" SG_ 930 TripDuration_OverallTrip 7;
BA_ "GenSigCycleTimeActive" SG_ 930 TripDuration_OverallTrip 500;
BA_ "GenSigCycleTime" SG_ 930 TripDuration_OverallTrip 500;
BA_ "GenSigTimeoutMsg_HU_High_X445" SG_ 930 TripDuration_OverallTrip 2500;
BA_ "GenSigTimeoutMsg_HU_Mid_X445" SG_ 930 TripDuration_OverallTrip 2500;
BA_ "GenSigTimeoutTime_HU_High_X445" SG_ 930 TripDuration_OverallTrip 2500;
BA_ "GenSigTimeoutTime_HU_Mid_X445" SG_ 930 TripDuration_OverallTrip 2500;
BA_ "GenSigTimeoutMsg_IVI" SG_ 930 TripDuration_OverallTrip 2500;
BA_ "GenSigTimeoutTime_IVI" SG_ 930 TripDuration_OverallTrip 2500;
BA_ "GenSigTimeoutTime_HU_Mid_X451" SG_ 930 AvgSpeed_OverallTrip 2500;
BA_ "GenSigTimeoutTime_HU_High_X451" SG_ 930 AvgSpeed_OverallTrip 2500;
BA_ "GenSigTimeoutTime_HU_B" SG_ 930 AvgSpeed_OverallTrip 2500;
BA_ "GenSigTimeoutTime_HU_A" SG_ 930 AvgSpeed_OverallTrip 2500;
BA_ "GenSigTimeoutMsg_HU_Mid_X451" SG_ 930 AvgSpeed_OverallTrip 2500;
BA_ "GenSigTimeoutMsg_HU_High_X451" SG_ 930 AvgSpeed_OverallTrip 2500;
BA_ "GenSigTimeoutMsg_HU_B" SG_ 930 AvgSpeed_OverallTrip 2500;
BA_ "GenSigTimeoutMsg_HU_A" SG_ 930 AvgSpeed_OverallTrip 2500;
BA_ "GenSigSendType" SG_ 930 AvgSpeed_OverallTrip 7;
BA_ "GenSigCycleTimeActive" SG_ 930 AvgSpeed_OverallTrip 500;
BA_ "GenSigCycleTime" SG_ 930 AvgSpeed_OverallTrip 500;
BA_ "GenSigTimeoutMsg_HU_High_X445" SG_ 930 AvgSpeed_OverallTrip 2500;
BA_ "GenSigTimeoutMsg_HU_Mid_X445" SG_ 930 AvgSpeed_OverallTrip 2500;
BA_ "GenSigTimeoutTime_HU_High_X445" SG_ 930 AvgSpeed_OverallTrip 2500;
BA_ "GenSigTimeoutTime_HU_Mid_X445" SG_ 930 AvgSpeed_OverallTrip 2500;
BA_ "GenSigTimeoutMsg_IVI" SG_ 930 AvgSpeed_OverallTrip 2500;
BA_ "GenSigTimeoutTime_IVI" SG_ 930 AvgSpeed_OverallTrip 2500;
BA_ "GenSigTimeoutTime_HU_Mid_X451" SG_ 930 TripDistance_OverAllTrip 2500;
BA_ "GenSigTimeoutTime_HU_High_X451" SG_ 930 TripDistance_OverAllTrip 2500;
BA_ "GenSigTimeoutTime_HU_B" SG_ 930 TripDistance_OverAllTrip 2500;
BA_ "GenSigTimeoutTime_HU_A" SG_ 930 TripDistance_OverAllTrip 2500;
BA_ "GenSigTimeoutMsg_HU_Mid_X451" SG_ 930 TripDistance_OverAllTrip 2500;
BA_ "GenSigTimeoutMsg_HU_High_X451" SG_ 930 TripDistance_OverAllTrip 2500;
BA_ "GenSigTimeoutMsg_HU_B" SG_ 930 TripDistance_OverAllTrip 2500;
BA_ "GenSigTimeoutMsg_HU_A" SG_ 930 TripDistance_OverAllTrip 2500;
BA_ "GenSigSendType" SG_ 930 TripDistance_OverAllTrip 7;
BA_ "GenSigCycleTimeActive" SG_ 930 TripDistance_OverAllTrip 500;
BA_ "GenSigCycleTime" SG_ 930 TripDistance_OverAllTrip 500;
BA_ "GenSigTimeoutMsg_HU_High_X445" SG_ 930 TripDistance_OverAllTrip 2500;
BA_ "GenSigTimeoutMsg_HU_Mid_X445" SG_ 930 TripDistance_OverAllTrip 2500;
BA_ "GenSigTimeoutTime_HU_High_X445" SG_ 930 TripDistance_OverAllTrip 2500;
BA_ "GenSigTimeoutTime_HU_Mid_X445" SG_ 930 TripDistance_OverAllTrip 2500;
BA_ "GenSigTimeoutMsg_IVI" SG_ 930 TripDistance_OverAllTrip 2500;
BA_ "GenSigTimeoutTime_IVI" SG_ 930 TripDistance_OverAllTrip 2500;
BA_ "GenSigTimeoutTime_HU_Mid_X451" SG_ 930 AvgFuelEconomy_OverallTrip 2500;
BA_ "GenSigTimeoutTime_HU_High_X451" SG_ 930 AvgFuelEconomy_OverallTrip 2500;
BA_ "GenSigTimeoutTime_HU_B" SG_ 930 AvgFuelEconomy_OverallTrip 2500;
BA_ "GenSigTimeoutTime_HU_A" SG_ 930 AvgFuelEconomy_OverallTrip 2500;
BA_ "GenSigTimeoutMsg_HU_Mid_X451" SG_ 930 AvgFuelEconomy_OverallTrip 2500;
BA_ "GenSigTimeoutMsg_HU_High_X451" SG_ 930 AvgFuelEconomy_OverallTrip 2500;
BA_ "GenSigTimeoutMsg_HU_B" SG_ 930 AvgFuelEconomy_OverallTrip 2500;
BA_ "GenSigTimeoutMsg_HU_A" SG_ 930 AvgFuelEconomy_OverallTrip 2500;
BA_ "GenSigSendType" SG_ 930 AvgFuelEconomy_OverallTrip 7;
BA_ "GenSigCycleTimeActive" SG_ 930 AvgFuelEconomy_OverallTrip 500;
BA_ "GenSigCycleTime" SG_ 930 AvgFuelEconomy_OverallTrip 500;
BA_ "GenSigTimeoutMsg_HU_High_X445" SG_ 930 AvgFuelEconomy_OverallTrip 2500;
BA_ "GenSigTimeoutMsg_HU_Mid_X445" SG_ 930 AvgFuelEconomy_OverallTrip 2500;
BA_ "GenSigTimeoutTime_HU_High_X445" SG_ 930 AvgFuelEconomy_OverallTrip 2500;
BA_ "GenSigTimeoutTime_HU_Mid_X445" SG_ 930 AvgFuelEconomy_OverallTrip 2500;
BA_ "GenSigTimeoutMsg_IVI" SG_ 930 AvgFuelEconomy_OverallTrip 2500;
BA_ "GenSigTimeoutTime_IVI" SG_ 930 AvgFuelEconomy_OverallTrip 2500;
BA_ "GenSigTimeoutTime_HU_Mid_X451" SG_ 931 TripDuration_CurrentTrip 2500;
BA_ "GenSigTimeoutTime_HU_High_X451" SG_ 931 TripDuration_CurrentTrip 2500;
BA_ "GenSigTimeoutTime_HU_B" SG_ 931 TripDuration_CurrentTrip 2500;
BA_ "GenSigTimeoutTime_HU_A" SG_ 931 TripDuration_CurrentTrip 2500;
BA_ "GenSigTimeoutMsg_HU_Mid_X451" SG_ 931 TripDuration_CurrentTrip 2500;
BA_ "GenSigTimeoutMsg_HU_High_X451" SG_ 931 TripDuration_CurrentTrip 2500;
BA_ "GenSigTimeoutMsg_HU_B" SG_ 931 TripDuration_CurrentTrip 2500;
BA_ "GenSigTimeoutMsg_HU_A" SG_ 931 TripDuration_CurrentTrip 2500;
BA_ "GenSigSendType" SG_ 931 TripDuration_CurrentTrip 7;
BA_ "GenSigCycleTimeActive" SG_ 931 TripDuration_CurrentTrip 500;
BA_ "GenSigCycleTime" SG_ 931 TripDuration_CurrentTrip 500;
BA_ "GenSigTimeoutMsg_HU_High_X445" SG_ 931 TripDuration_CurrentTrip 2500;
BA_ "GenSigTimeoutMsg_HU_Mid_X445" SG_ 931 TripDuration_CurrentTrip 2500;
BA_ "GenSigTimeoutTime_HU_High_X445" SG_ 931 TripDuration_CurrentTrip 2500;
BA_ "GenSigTimeoutTime_HU_Mid_X445" SG_ 931 TripDuration_CurrentTrip 2500;
BA_ "GenSigTimeoutMsg_IVI" SG_ 931 TripDuration_CurrentTrip 2500;
BA_ "GenSigTimeoutTime_IVI" SG_ 931 TripDuration_CurrentTrip 2500;
BA_ "GenSigTimeoutTime_HU_Mid_X451" SG_ 931 AvgFuelEconomy_Currenttrip 2500;
BA_ "GenSigTimeoutTime_HU_High_X451" SG_ 931 AvgFuelEconomy_Currenttrip 2500;
BA_ "GenSigTimeoutTime_HU_B" SG_ 931 AvgFuelEconomy_Currenttrip 2500;
BA_ "GenSigTimeoutTime_HU_A" SG_ 931 AvgFuelEconomy_Currenttrip 2500;
BA_ "GenSigTimeoutMsg_HU_Mid_X451" SG_ 931 AvgFuelEconomy_Currenttrip 2500;
BA_ "GenSigTimeoutMsg_HU_High_X451" SG_ 931 AvgFuelEconomy_Currenttrip 2500;
BA_ "GenSigTimeoutMsg_HU_B" SG_ 931 AvgFuelEconomy_Currenttrip 2500;
BA_ "GenSigTimeoutMsg_HU_A" SG_ 931 AvgFuelEconomy_Currenttrip 2500;
BA_ "GenSigSendType" SG_ 931 AvgFuelEconomy_Currenttrip 7;
BA_ "GenSigCycleTimeActive" SG_ 931 AvgFuelEconomy_Currenttrip 500;
BA_ "GenSigCycleTime" SG_ 931 AvgFuelEconomy_Currenttrip 500;
BA_ "GenSigTimeoutMsg_HU_High_X445" SG_ 931 AvgFuelEconomy_Currenttrip 2500;
BA_ "GenSigTimeoutMsg_HU_Mid_X445" SG_ 931 AvgFuelEconomy_Currenttrip 2500;
BA_ "GenSigTimeoutTime_HU_High_X445" SG_ 931 AvgFuelEconomy_Currenttrip 2500;
BA_ "GenSigTimeoutTime_HU_Mid_X445" SG_ 931 AvgFuelEconomy_Currenttrip 2500;
BA_ "GenSigTimeoutMsg_IVI" SG_ 931 AvgFuelEconomy_Currenttrip 2500;
BA_ "GenSigTimeoutTime_IVI" SG_ 931 AvgFuelEconomy_Currenttrip 2500;
BA_ "GenSigTimeoutTime_HU_Mid_X451" SG_ 931 AvgSpeed_CurrentTrip 2500;
BA_ "GenSigTimeoutTime_HU_High_X451" SG_ 931 AvgSpeed_CurrentTrip 2500;
BA_ "GenSigTimeoutTime_HU_B" SG_ 931 AvgSpeed_CurrentTrip 2500;
BA_ "GenSigTimeoutTime_HU_A" SG_ 931 AvgSpeed_CurrentTrip 2500;
BA_ "GenSigTimeoutMsg_HU_Mid_X451" SG_ 931 AvgSpeed_CurrentTrip 2500;
BA_ "GenSigTimeoutMsg_HU_High_X451" SG_ 931 AvgSpeed_CurrentTrip 2500;
BA_ "GenSigTimeoutMsg_HU_B" SG_ 931 AvgSpeed_CurrentTrip 2500;
BA_ "GenSigTimeoutMsg_HU_A" SG_ 931 AvgSpeed_CurrentTrip 2500;
BA_ "GenSigSendType" SG_ 931 AvgSpeed_CurrentTrip 7;
BA_ "GenSigCycleTimeActive" SG_ 931 AvgSpeed_CurrentTrip 500;
BA_ "GenSigCycleTime" SG_ 931 AvgSpeed_CurrentTrip 500;
BA_ "GenSigTimeoutMsg_HU_High_X445" SG_ 931 AvgSpeed_CurrentTrip 2500;
BA_ "GenSigTimeoutMsg_HU_Mid_X445" SG_ 931 AvgSpeed_CurrentTrip 2500;
BA_ "GenSigTimeoutTime_HU_High_X445" SG_ 931 AvgSpeed_CurrentTrip 2500;
BA_ "GenSigTimeoutTime_HU_Mid_X445" SG_ 931 AvgSpeed_CurrentTrip 2500;
BA_ "GenSigTimeoutMsg_IVI" SG_ 931 AvgSpeed_CurrentTrip 2500;
BA_ "GenSigTimeoutTime_IVI" SG_ 931 AvgSpeed_CurrentTrip 2500;
BA_ "GenSigTimeoutTime_HU_Mid_X451" SG_ 931 TripDistance_CurrentTrip 2500;
BA_ "GenSigTimeoutTime_HU_High_X451" SG_ 931 TripDistance_CurrentTrip 2500;
BA_ "GenSigTimeoutTime_HU_B" SG_ 931 TripDistance_CurrentTrip 2500;
BA_ "GenSigTimeoutTime_HU_A" SG_ 931 TripDistance_CurrentTrip 2500;
BA_ "GenSigTimeoutMsg_HU_Mid_X451" SG_ 931 TripDistance_CurrentTrip 2500;
BA_ "GenSigTimeoutMsg_HU_High_X451" SG_ 931 TripDistance_CurrentTrip 2500;
BA_ "GenSigTimeoutMsg_HU_B" SG_ 931 TripDistance_CurrentTrip 2500;
BA_ "GenSigTimeoutMsg_HU_A" SG_ 931 TripDistance_CurrentTrip 2500;
BA_ "GenSigSendType" SG_ 931 TripDistance_CurrentTrip 7;
BA_ "GenSigCycleTimeActive" SG_ 931 TripDistance_CurrentTrip 500;
BA_ "GenSigCycleTime" SG_ 931 TripDistance_CurrentTrip 500;
BA_ "GenSigTimeoutMsg_HU_High_X445" SG_ 931 TripDistance_CurrentTrip 2500;
BA_ "GenSigTimeoutMsg_HU_Mid_X445" SG_ 931 TripDistance_CurrentTrip 2500;
BA_ "GenSigTimeoutTime_HU_High_X445" SG_ 931 TripDistance_CurrentTrip 2500;
BA_ "GenSigTimeoutTime_HU_Mid_X445" SG_ 931 TripDistance_CurrentTrip 2500;
BA_ "GenSigTimeoutMsg_IVI" SG_ 931 TripDistance_CurrentTrip 2500;
BA_ "GenSigTimeoutTime_IVI" SG_ 931 TripDistance_CurrentTrip 2500;
BA_ "GenSigTimeoutTime_HU_Mid_X451" SG_ 932 HuIcDriveproOverAllScore_Inst 2500;
BA_ "GenSigTimeoutTime_HU_High_X451" SG_ 932 HuIcDriveproOverAllScore_Inst 2500;
BA_ "GenSigTimeoutTime_HU_B" SG_ 932 HuIcDriveproOverAllScore_Inst 2500;
BA_ "GenSigTimeoutTime_HU_A" SG_ 932 HuIcDriveproOverAllScore_Inst 2500;
BA_ "GenSigTimeoutMsg_HU_Mid_X451" SG_ 932 HuIcDriveproOverAllScore_Inst 2500;
BA_ "GenSigTimeoutMsg_HU_High_X451" SG_ 932 HuIcDriveproOverAllScore_Inst 2500;
BA_ "GenSigTimeoutMsg_HU_B" SG_ 932 HuIcDriveproOverAllScore_Inst 2500;
BA_ "GenSigTimeoutMsg_HU_A" SG_ 932 HuIcDriveproOverAllScore_Inst 2500;
BA_ "GenSigSendType" SG_ 932 HuIcDriveproOverAllScore_Inst 7;
BA_ "GenSigCycleTimeActive" SG_ 932 HuIcDriveproOverAllScore_Inst 500;
BA_ "GenSigCycleTime" SG_ 932 HuIcDriveproOverAllScore_Inst 500;
BA_ "GenSigTimeoutMsg_HU_High_X445" SG_ 932 HuIcDriveproOverAllScore_Inst 2500;
BA_ "GenSigTimeoutMsg_HU_Mid_X445" SG_ 932 HuIcDriveproOverAllScore_Inst 2500;
BA_ "GenSigTimeoutTime_HU_High_X445" SG_ 932 HuIcDriveproOverAllScore_Inst 2500;
BA_ "GenSigTimeoutTime_HU_Mid_X445" SG_ 932 HuIcDriveproOverAllScore_Inst 2500;
BA_ "GenSigTimeoutMsg_IVI" SG_ 932 HuIcDriveproOverAllScore_Inst 2500;
BA_ "GenSigTimeoutTime_IVI" SG_ 932 HuIcDriveproOverAllScore_Inst 2500;
BA_ "GenSigTimeoutTime_HU_Mid_X451" SG_ 932 HuIcDriveproFEscore_Inst 2500;
BA_ "GenSigTimeoutTime_HU_High_X451" SG_ 932 HuIcDriveproFEscore_Inst 2500;
BA_ "GenSigTimeoutTime_HU_B" SG_ 932 HuIcDriveproFEscore_Inst 2500;
BA_ "GenSigTimeoutTime_HU_A" SG_ 932 HuIcDriveproFEscore_Inst 2500;
BA_ "GenSigTimeoutMsg_HU_Mid_X451" SG_ 932 HuIcDriveproFEscore_Inst 2500;
BA_ "GenSigTimeoutMsg_HU_High_X451" SG_ 932 HuIcDriveproFEscore_Inst 2500;
BA_ "GenSigTimeoutMsg_HU_B" SG_ 932 HuIcDriveproFEscore_Inst 2500;
BA_ "GenSigTimeoutMsg_HU_A" SG_ 932 HuIcDriveproFEscore_Inst 2500;
BA_ "GenSigSendType" SG_ 932 HuIcDriveproFEscore_Inst 7;
BA_ "GenSigCycleTimeActive" SG_ 932 HuIcDriveproFEscore_Inst 500;
BA_ "GenSigCycleTime" SG_ 932 HuIcDriveproFEscore_Inst 500;
BA_ "GenSigTimeoutMsg_HU_High_X445" SG_ 932 HuIcDriveproFEscore_Inst 2500;
BA_ "GenSigTimeoutMsg_HU_Mid_X445" SG_ 932 HuIcDriveproFEscore_Inst 2500;
BA_ "GenSigTimeoutTime_HU_High_X445" SG_ 932 HuIcDriveproFEscore_Inst 2500;
BA_ "GenSigTimeoutTime_HU_Mid_X445" SG_ 932 HuIcDriveproFEscore_Inst 2500;
BA_ "GenSigTimeoutMsg_IVI" SG_ 932 HuIcDriveproFEscore_Inst 2500;
BA_ "GenSigTimeoutTime_IVI" SG_ 932 HuIcDriveproFEscore_Inst 2500;
BA_ "GenSigTimeoutTime_HU_Mid_X451" SG_ 932 HuIcDriveproSafetyScore_Inst 2500;
BA_ "GenSigTimeoutTime_HU_High_X451" SG_ 932 HuIcDriveproSafetyScore_Inst 2500;
BA_ "GenSigTimeoutTime_HU_B" SG_ 932 HuIcDriveproSafetyScore_Inst 2500;
BA_ "GenSigTimeoutTime_HU_A" SG_ 932 HuIcDriveproSafetyScore_Inst 2500;
BA_ "GenSigTimeoutMsg_HU_Mid_X451" SG_ 932 HuIcDriveproSafetyScore_Inst 2500;
BA_ "GenSigTimeoutMsg_HU_High_X451" SG_ 932 HuIcDriveproSafetyScore_Inst 2500;
BA_ "GenSigTimeoutMsg_HU_B" SG_ 932 HuIcDriveproSafetyScore_Inst 2500;
BA_ "GenSigTimeoutMsg_HU_A" SG_ 932 HuIcDriveproSafetyScore_Inst 2500;
BA_ "GenSigSendType" SG_ 932 HuIcDriveproSafetyScore_Inst 7;
BA_ "GenSigCycleTimeActive" SG_ 932 HuIcDriveproSafetyScore_Inst 500;
BA_ "GenSigCycleTime" SG_ 932 HuIcDriveproSafetyScore_Inst 500;
BA_ "GenSigTimeoutMsg_HU_High_X445" SG_ 932 HuIcDriveproSafetyScore_Inst 2500;
BA_ "GenSigTimeoutMsg_HU_Mid_X445" SG_ 932 HuIcDriveproSafetyScore_Inst 2500;
BA_ "GenSigTimeoutTime_HU_High_X445" SG_ 932 HuIcDriveproSafetyScore_Inst 2500;
BA_ "GenSigTimeoutTime_HU_Mid_X445" SG_ 932 HuIcDriveproSafetyScore_Inst 2500;
BA_ "GenSigTimeoutMsg_IVI" SG_ 932 HuIcDriveproSafetyScore_Inst 2500;
BA_ "GenSigTimeoutTime_IVI" SG_ 932 HuIcDriveproSafetyScore_Inst 2500;
BA_ "GenSigTimeoutTime_HU_Mid_X451" SG_ 932 HuIcDriveproDrivingScore_Inst 2500;
BA_ "GenSigTimeoutTime_HU_High_X451" SG_ 932 HuIcDriveproDrivingScore_Inst 2500;
BA_ "GenSigTimeoutTime_HU_B" SG_ 932 HuIcDriveproDrivingScore_Inst 2500;
BA_ "GenSigTimeoutTime_HU_A" SG_ 932 HuIcDriveproDrivingScore_Inst 2500;
BA_ "GenSigTimeoutMsg_HU_Mid_X451" SG_ 932 HuIcDriveproDrivingScore_Inst 2500;
BA_ "GenSigTimeoutMsg_HU_High_X451" SG_ 932 HuIcDriveproDrivingScore_Inst 2500;
BA_ "GenSigTimeoutMsg_HU_B" SG_ 932 HuIcDriveproDrivingScore_Inst 2500;
BA_ "GenSigTimeoutMsg_HU_A" SG_ 932 HuIcDriveproDrivingScore_Inst 2500;
BA_ "GenSigSendType" SG_ 932 HuIcDriveproDrivingScore_Inst 7;
BA_ "GenSigCycleTimeActive" SG_ 932 HuIcDriveproDrivingScore_Inst 500;
BA_ "GenSigCycleTime" SG_ 932 HuIcDriveproDrivingScore_Inst 500;
BA_ "GenSigTimeoutMsg_HU_High_X445" SG_ 932 HuIcDriveproDrivingScore_Inst 2500;
BA_ "GenSigTimeoutMsg_HU_Mid_X445" SG_ 932 HuIcDriveproDrivingScore_Inst 2500;
BA_ "GenSigTimeoutTime_HU_High_X445" SG_ 932 HuIcDriveproDrivingScore_Inst 2500;
BA_ "GenSigTimeoutTime_HU_Mid_X445" SG_ 932 HuIcDriveproDrivingScore_Inst 2500;
BA_ "GenSigTimeoutMsg_IVI" SG_ 932 HuIcDriveproDrivingScore_Inst 2500;
BA_ "GenSigTimeoutTime_IVI" SG_ 932 HuIcDriveproDrivingScore_Inst 2500;
BA_ "GenSigTimeoutTime_HU_Mid_X451" SG_ 938 LowBatUIdMsg 2500;
BA_ "GenSigTimeoutTime_HU_High_X451" SG_ 938 LowBatUIdMsg 2500;
BA_ "GenSigTimeoutTime_HU_B" SG_ 938 LowBatUIdMsg 2500;
BA_ "GenSigTimeoutTime_HU_A" SG_ 938 LowBatUIdMsg 2500;
BA_ "GenSigTimeoutMsg_HU_Mid_X451" SG_ 938 LowBatUIdMsg 2500;
BA_ "GenSigTimeoutMsg_HU_High_X451" SG_ 938 LowBatUIdMsg 2500;
BA_ "GenSigTimeoutMsg_HU_B" SG_ 938 LowBatUIdMsg 2500;
BA_ "GenSigTimeoutMsg_HU_A" SG_ 938 LowBatUIdMsg 2500;
BA_ "GenSigSendType" SG_ 938 LowBatUIdMsg 7;
BA_ "GenSigCycleTimeActive" SG_ 938 LowBatUIdMsg 500;
BA_ "GenSigCycleTime" SG_ 938 LowBatUIdMsg 500;
BA_ "GenSigTimeoutMsg_HU_High_X445" SG_ 938 LowBatUIdMsg 2500;
BA_ "GenSigTimeoutMsg_HU_Mid_X445" SG_ 938 LowBatUIdMsg 2500;
BA_ "GenSigTimeoutTime_HU_High_X445" SG_ 938 LowBatUIdMsg 2500;
BA_ "GenSigTimeoutTime_HU_Mid_X445" SG_ 938 LowBatUIdMsg 2500;
BA_ "GenSigTimeoutMsg_IVI" SG_ 938 LowBatUIdMsg 2500;
BA_ "GenSigTimeoutTime_IVI" SG_ 938 LowBatUIdMsg 2500;
BA_ "GenSigTimeoutTime_HU_Mid_X451" SG_ 946 HighBeamTelltaleStatus 2500;
BA_ "GenSigTimeoutTime_HU_High_X451" SG_ 946 HighBeamTelltaleStatus 2500;
BA_ "GenSigTimeoutTime_HU_B" SG_ 946 HighBeamTelltaleStatus 2500;
BA_ "GenSigTimeoutTime_HU_A" SG_ 946 HighBeamTelltaleStatus 2500;
BA_ "GenSigTimeoutMsg_HU_Mid_X451" SG_ 946 HighBeamTelltaleStatus 2500;
BA_ "GenSigTimeoutMsg_HU_High_X451" SG_ 946 HighBeamTelltaleStatus 2500;
BA_ "GenSigTimeoutMsg_HU_B" SG_ 946 HighBeamTelltaleStatus 2500;
BA_ "GenSigTimeoutMsg_HU_A" SG_ 946 HighBeamTelltaleStatus 2500;
BA_ "GenSigSendType" SG_ 946 HighBeamTelltaleStatus 7;
BA_ "GenSigCycleTimeActive" SG_ 946 HighBeamTelltaleStatus 500;
BA_ "GenSigCycleTime" SG_ 946 HighBeamTelltaleStatus 500;
BA_ "GenSigTimeoutMsg_HU_High_X445" SG_ 946 HighBeamTelltaleStatus 2500;
BA_ "GenSigTimeoutMsg_HU_Mid_X445" SG_ 946 HighBeamTelltaleStatus 2500;
BA_ "GenSigTimeoutTime_HU_High_X445" SG_ 946 HighBeamTelltaleStatus 2500;
BA_ "GenSigTimeoutTime_HU_Mid_X445" SG_ 946 HighBeamTelltaleStatus 2500;
BA_ "GenSigTimeoutMsg_IVI" SG_ 946 HighBeamTelltaleStatus 2500;
BA_ "GenSigTimeoutTime_IVI" SG_ 946 HighBeamTelltaleStatus 2500;
BA_ "GenSigTimeoutTime_HU_Mid_X451" SG_ 946 HighBeamTelltale 2500;
BA_ "GenSigTimeoutTime_HU_High_X451" SG_ 946 HighBeamTelltale 2500;
BA_ "GenSigTimeoutTime_HU_B" SG_ 946 HighBeamTelltale 2500;
BA_ "GenSigTimeoutTime_HU_A" SG_ 946 HighBeamTelltale 2500;
BA_ "GenSigTimeoutMsg_HU_Mid_X451" SG_ 946 HighBeamTelltale 2500;
BA_ "GenSigTimeoutMsg_HU_High_X451" SG_ 946 HighBeamTelltale 2500;
BA_ "GenSigTimeoutMsg_HU_B" SG_ 946 HighBeamTelltale 2500;
BA_ "GenSigTimeoutMsg_HU_A" SG_ 946 HighBeamTelltale 2500;
BA_ "GenSigSendType" SG_ 946 HighBeamTelltale 7;
BA_ "GenSigCycleTimeActive" SG_ 946 HighBeamTelltale 500;
BA_ "GenSigCycleTime" SG_ 946 HighBeamTelltale 500;
BA_ "GenSigTimeoutMsg_HU_High_X445" SG_ 946 HighBeamTelltale 2500;
BA_ "GenSigTimeoutMsg_HU_Mid_X445" SG_ 946 HighBeamTelltale 2500;
BA_ "GenSigTimeoutTime_HU_High_X445" SG_ 946 HighBeamTelltale 2500;
BA_ "GenSigTimeoutTime_HU_Mid_X445" SG_ 946 HighBeamTelltale 2500;
BA_ "GenSigTimeoutMsg_IVI" SG_ 946 HighBeamTelltale 2500;
BA_ "GenSigTimeoutTime_IVI" SG_ 946 HighBeamTelltale 2500;
BA_ "GenSigTimeoutTime_HU_Mid_X451" SG_ 946 DoorStateRearLHStatus 2500;
BA_ "GenSigTimeoutTime_HU_High_X451" SG_ 946 DoorStateRearLHStatus 2500;
BA_ "GenSigTimeoutTime_HU_B" SG_ 946 DoorStateRearLHStatus 2500;
BA_ "GenSigTimeoutTime_HU_A" SG_ 946 DoorStateRearLHStatus 2500;
BA_ "GenSigTimeoutMsg_HU_Mid_X451" SG_ 946 DoorStateRearLHStatus 2500;
BA_ "GenSigTimeoutMsg_HU_High_X451" SG_ 946 DoorStateRearLHStatus 2500;
BA_ "GenSigTimeoutMsg_HU_B" SG_ 946 DoorStateRearLHStatus 2500;
BA_ "GenSigTimeoutMsg_HU_A" SG_ 946 DoorStateRearLHStatus 2500;
BA_ "GenSigSendType" SG_ 946 DoorStateRearLHStatus 7;
BA_ "GenSigCycleTimeActive" SG_ 946 DoorStateRearLHStatus 500;
BA_ "GenSigCycleTime" SG_ 946 DoorStateRearLHStatus 500;
BA_ "GenSigTimeoutMsg_HU_High_X445" SG_ 946 DoorStateRearLHStatus 2500;
BA_ "GenSigTimeoutMsg_HU_Mid_X445" SG_ 946 DoorStateRearLHStatus 2500;
BA_ "GenSigTimeoutTime_HU_High_X445" SG_ 946 DoorStateRearLHStatus 2500;
BA_ "GenSigTimeoutTime_HU_Mid_X445" SG_ 946 DoorStateRearLHStatus 2500;
BA_ "GenSigTimeoutMsg_IVI" SG_ 946 DoorStateRearLHStatus 2500;
BA_ "GenSigTimeoutTime_IVI" SG_ 946 DoorStateRearLHStatus 2500;
BA_ "GenSigTimeoutTime_HU_Mid_X451" SG_ 946 DoorStatePassStatus 2500;
BA_ "GenSigTimeoutTime_HU_High_X451" SG_ 946 DoorStatePassStatus 2500;
BA_ "GenSigTimeoutTime_HU_B" SG_ 946 DoorStatePassStatus 2500;
BA_ "GenSigTimeoutTime_HU_A" SG_ 946 DoorStatePassStatus 2500;
BA_ "GenSigTimeoutMsg_HU_Mid_X451" SG_ 946 DoorStatePassStatus 2500;
BA_ "GenSigTimeoutMsg_HU_High_X451" SG_ 946 DoorStatePassStatus 2500;
BA_ "GenSigTimeoutMsg_HU_B" SG_ 946 DoorStatePassStatus 2500;
BA_ "GenSigTimeoutMsg_HU_A" SG_ 946 DoorStatePassStatus 2500;
BA_ "GenSigSendType" SG_ 946 DoorStatePassStatus 7;
BA_ "GenSigCycleTimeActive" SG_ 946 DoorStatePassStatus 500;
BA_ "GenSigCycleTime" SG_ 946 DoorStatePassStatus 500;
BA_ "GenSigTimeoutMsg_HU_High_X445" SG_ 946 DoorStatePassStatus 2500;
BA_ "GenSigTimeoutMsg_HU_Mid_X445" SG_ 946 DoorStatePassStatus 2500;
BA_ "GenSigTimeoutTime_HU_High_X445" SG_ 946 DoorStatePassStatus 2500;
BA_ "GenSigTimeoutTime_HU_Mid_X445" SG_ 946 DoorStatePassStatus 2500;
BA_ "GenSigTimeoutMsg_IVI" SG_ 946 DoorStatePassStatus 2500;
BA_ "GenSigTimeoutTime_IVI" SG_ 946 DoorStatePassStatus 2500;
BA_ "GenSigTimeoutTime_HU_Mid_X451" SG_ 946 DoorStatePass 2500;
BA_ "GenSigTimeoutTime_HU_High_X451" SG_ 946 DoorStatePass 2500;
BA_ "GenSigTimeoutTime_HU_B" SG_ 946 DoorStatePass 2500;
BA_ "GenSigTimeoutTime_HU_A" SG_ 946 DoorStatePass 2500;
BA_ "GenSigTimeoutMsg_HU_Mid_X451" SG_ 946 DoorStatePass 2500;
BA_ "GenSigTimeoutMsg_HU_High_X451" SG_ 946 DoorStatePass 2500;
BA_ "GenSigTimeoutMsg_HU_B" SG_ 946 DoorStatePass 2500;
BA_ "GenSigTimeoutMsg_HU_A" SG_ 946 DoorStatePass 2500;
BA_ "GenSigSendType" SG_ 946 DoorStatePass 7;
BA_ "GenSigCycleTimeActive" SG_ 946 DoorStatePass 500;
BA_ "GenSigCycleTime" SG_ 946 DoorStatePass 500;
BA_ "GenSigTimeoutMsg_HU_High_X445" SG_ 946 DoorStatePass 2500;
BA_ "GenSigTimeoutMsg_HU_Mid_X445" SG_ 946 DoorStatePass 2500;
BA_ "GenSigTimeoutTime_HU_High_X445" SG_ 946 DoorStatePass 2500;
BA_ "GenSigTimeoutTime_HU_Mid_X445" SG_ 946 DoorStatePass 2500;
BA_ "GenSigTimeoutMsg_IVI" SG_ 946 DoorStatePass 2500;
BA_ "GenSigTimeoutTime_IVI" SG_ 946 DoorStatePass 2500;
BA_ "GenSigTimeoutTime_HU_Mid_X451" SG_ 946 DoorStateDrvrStatus 2500;
BA_ "GenSigTimeoutTime_HU_High_X451" SG_ 946 DoorStateDrvrStatus 2500;
BA_ "GenSigTimeoutTime_HU_B" SG_ 946 DoorStateDrvrStatus 2500;
BA_ "GenSigTimeoutTime_HU_A" SG_ 946 DoorStateDrvrStatus 2500;
BA_ "GenSigTimeoutMsg_HU_Mid_X451" SG_ 946 DoorStateDrvrStatus 2500;
BA_ "GenSigTimeoutMsg_HU_High_X451" SG_ 946 DoorStateDrvrStatus 2500;
BA_ "GenSigTimeoutMsg_HU_B" SG_ 946 DoorStateDrvrStatus 2500;
BA_ "GenSigTimeoutMsg_HU_A" SG_ 946 DoorStateDrvrStatus 2500;
BA_ "GenSigSendType" SG_ 946 DoorStateDrvrStatus 7;
BA_ "GenSigCycleTimeActive" SG_ 946 DoorStateDrvrStatus 500;
BA_ "GenSigCycleTime" SG_ 946 DoorStateDrvrStatus 500;
BA_ "GenSigTimeoutMsg_HU_High_X445" SG_ 946 DoorStateDrvrStatus 2500;
BA_ "GenSigTimeoutMsg_HU_Mid_X445" SG_ 946 DoorStateDrvrStatus 2500;
BA_ "GenSigTimeoutTime_HU_High_X445" SG_ 946 DoorStateDrvrStatus 2500;
BA_ "GenSigTimeoutTime_HU_Mid_X445" SG_ 946 DoorStateDrvrStatus 2500;
BA_ "GenSigTimeoutMsg_IVI" SG_ 946 DoorStateDrvrStatus 2500;
BA_ "GenSigTimeoutTime_IVI" SG_ 946 DoorStateDrvrStatus 2500;
BA_ "GenSigTimeoutTime_HU_Mid_X451" SG_ 946 DoorStateDrvr 2500;
BA_ "GenSigTimeoutTime_HU_High_X451" SG_ 946 DoorStateDrvr 2500;
BA_ "GenSigTimeoutTime_HU_B" SG_ 946 DoorStateDrvr 2500;
BA_ "GenSigTimeoutTime_HU_A" SG_ 946 DoorStateDrvr 2500;
BA_ "GenSigTimeoutMsg_HU_Mid_X451" SG_ 946 DoorStateDrvr 2500;
BA_ "GenSigTimeoutMsg_HU_High_X451" SG_ 946 DoorStateDrvr 2500;
BA_ "GenSigTimeoutMsg_HU_B" SG_ 946 DoorStateDrvr 2500;
BA_ "GenSigTimeoutMsg_HU_A" SG_ 946 DoorStateDrvr 2500;
BA_ "GenSigSendType" SG_ 946 DoorStateDrvr 7;
BA_ "GenSigCycleTimeActive" SG_ 946 DoorStateDrvr 500;
BA_ "GenSigCycleTime" SG_ 946 DoorStateDrvr 500;
BA_ "GenSigTimeoutMsg_HU_High_X445" SG_ 946 DoorStateDrvr 2500;
BA_ "GenSigTimeoutMsg_HU_Mid_X445" SG_ 946 DoorStateDrvr 2500;
BA_ "GenSigTimeoutTime_HU_High_X445" SG_ 946 DoorStateDrvr 2500;
BA_ "GenSigTimeoutTime_HU_Mid_X445" SG_ 946 DoorStateDrvr 2500;
BA_ "GenSigTimeoutMsg_IVI" SG_ 946 DoorStateDrvr 2500;
BA_ "GenSigTimeoutTime_IVI" SG_ 946 DoorStateDrvr 2500;
BA_ "GenSigTimeoutTime_HU_Mid_X451" SG_ 946 DoorStateRearRH 2500;
BA_ "GenSigTimeoutTime_HU_High_X451" SG_ 946 DoorStateRearRH 2500;
BA_ "GenSigTimeoutTime_HU_B" SG_ 946 DoorStateRearRH 2500;
BA_ "GenSigTimeoutTime_HU_A" SG_ 946 DoorStateRearRH 2500;
BA_ "GenSigTimeoutMsg_HU_Mid_X451" SG_ 946 DoorStateRearRH 2500;
BA_ "GenSigTimeoutMsg_HU_High_X451" SG_ 946 DoorStateRearRH 2500;
BA_ "GenSigTimeoutMsg_HU_B" SG_ 946 DoorStateRearRH 2500;
BA_ "GenSigTimeoutMsg_HU_A" SG_ 946 DoorStateRearRH 2500;
BA_ "GenSigSendType" SG_ 946 DoorStateRearRH 7;
BA_ "GenSigCycleTimeActive" SG_ 946 DoorStateRearRH 500;
BA_ "GenSigCycleTime" SG_ 946 DoorStateRearRH 500;
BA_ "GenSigTimeoutMsg_HU_High_X445" SG_ 946 DoorStateRearRH 2500;
BA_ "GenSigTimeoutMsg_HU_Mid_X445" SG_ 946 DoorStateRearRH 2500;
BA_ "GenSigTimeoutTime_HU_High_X445" SG_ 946 DoorStateRearRH 2500;
BA_ "GenSigTimeoutTime_HU_Mid_X445" SG_ 946 DoorStateRearRH 2500;
BA_ "GenSigTimeoutMsg_IVI" SG_ 946 DoorStateRearRH 2500;
BA_ "GenSigTimeoutTime_IVI" SG_ 946 DoorStateRearRH 2500;
BA_ "GenSigTimeoutTime_HU_Mid_X451" SG_ 946 DoorStateRearRHStatus 2500;
BA_ "GenSigTimeoutTime_HU_High_X451" SG_ 946 DoorStateRearRHStatus 2500;
BA_ "GenSigTimeoutTime_HU_B" SG_ 946 DoorStateRearRHStatus 2500;
BA_ "GenSigTimeoutTime_HU_A" SG_ 946 DoorStateRearRHStatus 2500;
BA_ "GenSigTimeoutMsg_HU_Mid_X451" SG_ 946 DoorStateRearRHStatus 2500;
BA_ "GenSigTimeoutMsg_HU_High_X451" SG_ 946 DoorStateRearRHStatus 2500;
BA_ "GenSigTimeoutMsg_HU_B" SG_ 946 DoorStateRearRHStatus 2500;
BA_ "GenSigTimeoutMsg_HU_A" SG_ 946 DoorStateRearRHStatus 2500;
BA_ "GenSigSendType" SG_ 946 DoorStateRearRHStatus 7;
BA_ "GenSigCycleTimeActive" SG_ 946 DoorStateRearRHStatus 500;
BA_ "GenSigCycleTime" SG_ 946 DoorStateRearRHStatus 500;
BA_ "GenSigTimeoutMsg_HU_High_X445" SG_ 946 DoorStateRearRHStatus 2500;
BA_ "GenSigTimeoutMsg_HU_Mid_X445" SG_ 946 DoorStateRearRHStatus 2500;
BA_ "GenSigTimeoutTime_HU_High_X445" SG_ 946 DoorStateRearRHStatus 2500;
BA_ "GenSigTimeoutTime_HU_Mid_X445" SG_ 946 DoorStateRearRHStatus 2500;
BA_ "GenSigTimeoutMsg_IVI" SG_ 946 DoorStateRearRHStatus 2500;
BA_ "GenSigTimeoutTime_IVI" SG_ 946 DoorStateRearRHStatus 2500;
BA_ "GenSigTimeoutTime_HU_Mid_X451" SG_ 946 DoorStateRearLH 2500;
BA_ "GenSigTimeoutTime_HU_High_X451" SG_ 946 DoorStateRearLH 2500;
BA_ "GenSigTimeoutTime_HU_B" SG_ 946 DoorStateRearLH 2500;
BA_ "GenSigTimeoutTime_HU_A" SG_ 946 DoorStateRearLH 2500;
BA_ "GenSigTimeoutMsg_HU_Mid_X451" SG_ 946 DoorStateRearLH 2500;
BA_ "GenSigTimeoutMsg_HU_High_X451" SG_ 946 DoorStateRearLH 2500;
BA_ "GenSigTimeoutMsg_HU_B" SG_ 946 DoorStateRearLH 2500;
BA_ "GenSigTimeoutMsg_HU_A" SG_ 946 DoorStateRearLH 2500;
BA_ "GenSigSendType" SG_ 946 DoorStateRearLH 7;
BA_ "GenSigCycleTimeActive" SG_ 946 DoorStateRearLH 500;
BA_ "GenSigCycleTime" SG_ 946 DoorStateRearLH 500;
BA_ "GenSigTimeoutMsg_HU_High_X445" SG_ 946 DoorStateRearLH 2500;
BA_ "GenSigTimeoutMsg_HU_Mid_X445" SG_ 946 DoorStateRearLH 2500;
BA_ "GenSigTimeoutTime_HU_High_X445" SG_ 946 DoorStateRearLH 2500;
BA_ "GenSigTimeoutTime_HU_Mid_X445" SG_ 946 DoorStateRearLH 2500;
BA_ "GenSigTimeoutMsg_IVI" SG_ 946 DoorStateRearLH 2500;
BA_ "GenSigTimeoutTime_IVI" SG_ 946 DoorStateRearLH 2500;
BA_ "GenSigTimeoutTime_HU_Mid_X451" SG_ 946 WiperState 2500;
BA_ "GenSigTimeoutTime_HU_High_X451" SG_ 946 WiperState 2500;
BA_ "GenSigTimeoutTime_HU_B" SG_ 946 WiperState 2500;
BA_ "GenSigTimeoutTime_HU_A" SG_ 946 WiperState 2500;
BA_ "GenSigTimeoutMsg_HU_Mid_X451" SG_ 946 WiperState 2500;
BA_ "GenSigTimeoutMsg_HU_High_X451" SG_ 946 WiperState 2500;
BA_ "GenSigTimeoutMsg_HU_B" SG_ 946 WiperState 2500;
BA_ "GenSigTimeoutMsg_HU_A" SG_ 946 WiperState 2500;
BA_ "GenSigSendType" SG_ 946 WiperState 7;
BA_ "GenSigCycleTimeActive" SG_ 946 WiperState 500;
BA_ "GenSigCycleTime" SG_ 946 WiperState 500;
BA_ "GenSigTimeoutMsg_HU_High_X445" SG_ 946 WiperState 2500;
BA_ "GenSigTimeoutMsg_HU_Mid_X445" SG_ 946 WiperState 2500;
BA_ "GenSigTimeoutTime_HU_High_X445" SG_ 946 WiperState 2500;
BA_ "GenSigTimeoutTime_HU_Mid_X445" SG_ 946 WiperState 2500;
BA_ "GenSigTimeoutMsg_IVI" SG_ 946 WiperState 2500;
BA_ "GenSigTimeoutTime_IVI" SG_ 946 WiperState 2500;
BA_ "GenSigTimeoutTime_HU_Mid_X451" SG_ 946 TailgateState 2500;
BA_ "GenSigTimeoutTime_HU_High_X451" SG_ 946 TailgateState 2500;
BA_ "GenSigTimeoutTime_HU_B" SG_ 946 TailgateState 2500;
BA_ "GenSigTimeoutTime_HU_A" SG_ 946 TailgateState 2500;
BA_ "GenSigTimeoutMsg_HU_Mid_X451" SG_ 946 TailgateState 2500;
BA_ "GenSigTimeoutMsg_HU_High_X451" SG_ 946 TailgateState 2500;
BA_ "GenSigTimeoutMsg_HU_B" SG_ 946 TailgateState 2500;
BA_ "GenSigTimeoutMsg_HU_A" SG_ 946 TailgateState 2500;
BA_ "GenSigSendType" SG_ 946 TailgateState 7;
BA_ "GenSigCycleTimeActive" SG_ 946 TailgateState 500;
BA_ "GenSigCycleTime" SG_ 946 TailgateState 500;
BA_ "GenSigTimeoutMsg_HU_High_X445" SG_ 946 TailgateState 2500;
BA_ "GenSigTimeoutMsg_HU_Mid_X445" SG_ 946 TailgateState 2500;
BA_ "GenSigTimeoutTime_HU_High_X445" SG_ 946 TailgateState 2500;
BA_ "GenSigTimeoutTime_HU_Mid_X445" SG_ 946 TailgateState 2500;
BA_ "GenSigTimeoutMsg_IVI" SG_ 946 TailgateState 2500;
BA_ "GenSigTimeoutTime_IVI" SG_ 946 TailgateState 2500;
BA_ "GenSigTimeoutTime_HU_Mid_X451" SG_ 946 WiperStateStatus 2500;
BA_ "GenSigTimeoutTime_HU_High_X451" SG_ 946 WiperStateStatus 2500;
BA_ "GenSigTimeoutTime_HU_B" SG_ 946 WiperStateStatus 2500;
BA_ "GenSigTimeoutTime_HU_A" SG_ 946 WiperStateStatus 2500;
BA_ "GenSigTimeoutMsg_HU_Mid_X451" SG_ 946 WiperStateStatus 2500;
BA_ "GenSigTimeoutMsg_HU_High_X451" SG_ 946 WiperStateStatus 2500;
BA_ "GenSigTimeoutMsg_HU_B" SG_ 946 WiperStateStatus 2500;
BA_ "GenSigTimeoutMsg_HU_A" SG_ 946 WiperStateStatus 2500;
BA_ "GenSigSendType" SG_ 946 WiperStateStatus 7;
BA_ "GenSigCycleTimeActive" SG_ 946 WiperStateStatus 500;
BA_ "GenSigCycleTime" SG_ 946 WiperStateStatus 500;
BA_ "GenSigTimeoutMsg_HU_High_X445" SG_ 946 WiperStateStatus 2500;
BA_ "GenSigTimeoutMsg_HU_Mid_X445" SG_ 946 WiperStateStatus 2500;
BA_ "GenSigTimeoutTime_HU_High_X445" SG_ 946 WiperStateStatus 2500;
BA_ "GenSigTimeoutTime_HU_Mid_X445" SG_ 946 WiperStateStatus 2500;
BA_ "GenSigTimeoutMsg_IVI" SG_ 946 WiperStateStatus 2500;
BA_ "GenSigTimeoutTime_IVI" SG_ 946 WiperStateStatus 2500;
BA_ "GenSigTimeoutTime_HU_Mid_X451" SG_ 946 TailgateStateStatus 2500;
BA_ "GenSigTimeoutTime_HU_High_X451" SG_ 946 TailgateStateStatus 2500;
BA_ "GenSigTimeoutTime_HU_B" SG_ 946 TailgateStateStatus 2500;
BA_ "GenSigTimeoutTime_HU_A" SG_ 946 TailgateStateStatus 2500;
BA_ "GenSigTimeoutMsg_HU_Mid_X451" SG_ 946 TailgateStateStatus 2500;
BA_ "GenSigTimeoutMsg_HU_High_X451" SG_ 946 TailgateStateStatus 2500;
BA_ "GenSigTimeoutMsg_HU_B" SG_ 946 TailgateStateStatus 2500;
BA_ "GenSigTimeoutMsg_HU_A" SG_ 946 TailgateStateStatus 2500;
BA_ "GenSigSendType" SG_ 946 TailgateStateStatus 7;
BA_ "GenSigCycleTimeActive" SG_ 946 TailgateStateStatus 500;
BA_ "GenSigCycleTime" SG_ 946 TailgateStateStatus 500;
BA_ "GenSigTimeoutMsg_HU_High_X445" SG_ 946 TailgateStateStatus 2500;
BA_ "GenSigTimeoutMsg_HU_Mid_X445" SG_ 946 TailgateStateStatus 2500;
BA_ "GenSigTimeoutTime_HU_High_X445" SG_ 946 TailgateStateStatus 2500;
BA_ "GenSigTimeoutTime_HU_Mid_X445" SG_ 946 TailgateStateStatus 2500;
BA_ "GenSigTimeoutMsg_IVI" SG_ 946 TailgateStateStatus 2500;
BA_ "GenSigTimeoutTime_IVI" SG_ 946 TailgateStateStatus 2500;
BA_ "GenSigTimeoutTime_HU_Mid_X451" SG_ 946 PositionLmpMalFn 2500;
BA_ "GenSigTimeoutTime_HU_High_X451" SG_ 946 PositionLmpMalFn 2500;
BA_ "GenSigTimeoutTime_HU_B" SG_ 946 PositionLmpMalFn 2500;
BA_ "GenSigTimeoutTime_HU_A" SG_ 946 PositionLmpMalFn 2500;
BA_ "GenSigTimeoutMsg_HU_Mid_X451" SG_ 946 PositionLmpMalFn 2500;
BA_ "GenSigTimeoutMsg_HU_High_X451" SG_ 946 PositionLmpMalFn 2500;
BA_ "GenSigTimeoutMsg_HU_B" SG_ 946 PositionLmpMalFn 2500;
BA_ "GenSigTimeoutMsg_HU_A" SG_ 946 PositionLmpMalFn 2500;
BA_ "GenSigSendType" SG_ 946 PositionLmpMalFn 7;
BA_ "GenSigCycleTimeActive" SG_ 946 PositionLmpMalFn 500;
BA_ "GenSigCycleTime" SG_ 946 PositionLmpMalFn 500;
BA_ "GenSigTimeoutMsg_HU_High_X445" SG_ 946 PositionLmpMalFn 2500;
BA_ "GenSigTimeoutMsg_HU_Mid_X445" SG_ 946 PositionLmpMalFn 2500;
BA_ "GenSigTimeoutTime_HU_High_X445" SG_ 946 PositionLmpMalFn 2500;
BA_ "GenSigTimeoutTime_HU_Mid_X445" SG_ 946 PositionLmpMalFn 2500;
BA_ "GenSigTimeoutMsg_IVI" SG_ 946 PositionLmpMalFn 2500;
BA_ "GenSigTimeoutTime_IVI" SG_ 946 PositionLmpMalFn 2500;
BA_ "GenSigTimeoutTime_HU_Mid_X451" SG_ 946 PositionLmpMalFnStatus 2500;
BA_ "GenSigTimeoutTime_HU_High_X451" SG_ 946 PositionLmpMalFnStatus 2500;
BA_ "GenSigTimeoutTime_HU_B" SG_ 946 PositionLmpMalFnStatus 2500;
BA_ "GenSigTimeoutTime_HU_A" SG_ 946 PositionLmpMalFnStatus 2500;
BA_ "GenSigTimeoutMsg_HU_Mid_X451" SG_ 946 PositionLmpMalFnStatus 2500;
BA_ "GenSigTimeoutMsg_HU_High_X451" SG_ 946 PositionLmpMalFnStatus 2500;
BA_ "GenSigTimeoutMsg_HU_B" SG_ 946 PositionLmpMalFnStatus 2500;
BA_ "GenSigTimeoutMsg_HU_A" SG_ 946 PositionLmpMalFnStatus 2500;
BA_ "GenSigSendType" SG_ 946 PositionLmpMalFnStatus 7;
BA_ "GenSigCycleTimeActive" SG_ 946 PositionLmpMalFnStatus 500;
BA_ "GenSigCycleTime" SG_ 946 PositionLmpMalFnStatus 500;
BA_ "GenSigTimeoutMsg_HU_High_X445" SG_ 946 PositionLmpMalFnStatus 2500;
BA_ "GenSigTimeoutMsg_HU_Mid_X445" SG_ 946 PositionLmpMalFnStatus 2500;
BA_ "GenSigTimeoutTime_HU_High_X445" SG_ 946 PositionLmpMalFnStatus 2500;
BA_ "GenSigTimeoutTime_HU_Mid_X445" SG_ 946 PositionLmpMalFnStatus 2500;
BA_ "GenSigTimeoutMsg_IVI" SG_ 946 PositionLmpMalFnStatus 2500;
BA_ "GenSigTimeoutTime_IVI" SG_ 946 PositionLmpMalFnStatus 2500;
BA_ "GenSigTimeoutTime_HU_Mid_X451" SG_ 946 BrakeLmpMalFn 2500;
BA_ "GenSigTimeoutTime_HU_High_X451" SG_ 946 BrakeLmpMalFn 2500;
BA_ "GenSigTimeoutTime_HU_B" SG_ 946 BrakeLmpMalFn 2500;
BA_ "GenSigTimeoutTime_HU_A" SG_ 946 BrakeLmpMalFn 2500;
BA_ "GenSigTimeoutMsg_HU_Mid_X451" SG_ 946 BrakeLmpMalFn 2500;
BA_ "GenSigTimeoutMsg_HU_High_X451" SG_ 946 BrakeLmpMalFn 2500;
BA_ "GenSigTimeoutMsg_HU_B" SG_ 946 BrakeLmpMalFn 2500;
BA_ "GenSigTimeoutMsg_HU_A" SG_ 946 BrakeLmpMalFn 2500;
BA_ "GenSigSendType" SG_ 946 BrakeLmpMalFn 7;
BA_ "GenSigCycleTimeActive" SG_ 946 BrakeLmpMalFn 500;
BA_ "GenSigCycleTime" SG_ 946 BrakeLmpMalFn 500;
BA_ "GenSigTimeoutMsg_HU_High_X445" SG_ 946 BrakeLmpMalFn 2500;
BA_ "GenSigTimeoutMsg_HU_Mid_X445" SG_ 946 BrakeLmpMalFn 2500;
BA_ "GenSigTimeoutTime_HU_High_X445" SG_ 946 BrakeLmpMalFn 2500;
BA_ "GenSigTimeoutTime_HU_Mid_X445" SG_ 946 BrakeLmpMalFn 2500;
BA_ "GenSigTimeoutMsg_IVI" SG_ 946 BrakeLmpMalFn 2500;
BA_ "GenSigTimeoutTime_IVI" SG_ 946 BrakeLmpMalFn 2500;
BA_ "GenSigTimeoutTime_HU_Mid_X451" SG_ 946 BrakeLmpMalFnStatus 2500;
BA_ "GenSigTimeoutTime_HU_High_X451" SG_ 946 BrakeLmpMalFnStatus 2500;
BA_ "GenSigTimeoutTime_HU_B" SG_ 946 BrakeLmpMalFnStatus 2500;
BA_ "GenSigTimeoutTime_HU_A" SG_ 946 BrakeLmpMalFnStatus 2500;
BA_ "GenSigTimeoutMsg_HU_Mid_X451" SG_ 946 BrakeLmpMalFnStatus 2500;
BA_ "GenSigTimeoutMsg_HU_High_X451" SG_ 946 BrakeLmpMalFnStatus 2500;
BA_ "GenSigTimeoutMsg_HU_B" SG_ 946 BrakeLmpMalFnStatus 2500;
BA_ "GenSigTimeoutMsg_HU_A" SG_ 946 BrakeLmpMalFnStatus 2500;
BA_ "GenSigSendType" SG_ 946 BrakeLmpMalFnStatus 7;
BA_ "GenSigCycleTimeActive" SG_ 946 BrakeLmpMalFnStatus 500;
BA_ "GenSigCycleTime" SG_ 946 BrakeLmpMalFnStatus 500;
BA_ "GenSigTimeoutMsg_HU_High_X445" SG_ 946 BrakeLmpMalFnStatus 2500;
BA_ "GenSigTimeoutMsg_HU_Mid_X445" SG_ 946 BrakeLmpMalFnStatus 2500;
BA_ "GenSigTimeoutTime_HU_High_X445" SG_ 946 BrakeLmpMalFnStatus 2500;
BA_ "GenSigTimeoutTime_HU_Mid_X445" SG_ 946 BrakeLmpMalFnStatus 2500;
BA_ "GenSigTimeoutMsg_IVI" SG_ 946 BrakeLmpMalFnStatus 2500;
BA_ "GenSigTimeoutTime_IVI" SG_ 946 BrakeLmpMalFnStatus 2500;
BA_ "GenSigTimeoutTime_HU_Mid_X451" SG_ 946 RevLampMalFn 2500;
BA_ "GenSigTimeoutTime_HU_High_X451" SG_ 946 RevLampMalFn 2500;
BA_ "GenSigTimeoutTime_HU_B" SG_ 946 RevLampMalFn 2500;
BA_ "GenSigTimeoutTime_HU_A" SG_ 946 RevLampMalFn 2500;
BA_ "GenSigTimeoutMsg_HU_Mid_X451" SG_ 946 RevLampMalFn 2500;
BA_ "GenSigTimeoutMsg_HU_High_X451" SG_ 946 RevLampMalFn 2500;
BA_ "GenSigTimeoutMsg_HU_B" SG_ 946 RevLampMalFn 2500;
BA_ "GenSigTimeoutMsg_HU_A" SG_ 946 RevLampMalFn 2500;
BA_ "GenSigSendType" SG_ 946 RevLampMalFn 7;
BA_ "GenSigCycleTimeActive" SG_ 946 RevLampMalFn 500;
BA_ "GenSigCycleTime" SG_ 946 RevLampMalFn 500;
BA_ "GenSigTimeoutMsg_HU_High_X445" SG_ 946 RevLampMalFn 2500;
BA_ "GenSigTimeoutMsg_HU_Mid_X445" SG_ 946 RevLampMalFn 2500;
BA_ "GenSigTimeoutTime_HU_High_X445" SG_ 946 RevLampMalFn 2500;
BA_ "GenSigTimeoutTime_HU_Mid_X445" SG_ 946 RevLampMalFn 2500;
BA_ "GenSigTimeoutMsg_IVI" SG_ 946 RevLampMalFn 2500;
BA_ "GenSigTimeoutTime_IVI" SG_ 946 RevLampMalFn 2500;
BA_ "GenSigTimeoutTime_HU_Mid_X451" SG_ 946 RevLampMalFnStatus 2500;
BA_ "GenSigTimeoutTime_HU_High_X451" SG_ 946 RevLampMalFnStatus 2500;
BA_ "GenSigTimeoutTime_HU_B" SG_ 946 RevLampMalFnStatus 2500;
BA_ "GenSigTimeoutTime_HU_A" SG_ 946 RevLampMalFnStatus 2500;
BA_ "GenSigTimeoutMsg_HU_Mid_X451" SG_ 946 RevLampMalFnStatus 2500;
BA_ "GenSigTimeoutMsg_HU_High_X451" SG_ 946 RevLampMalFnStatus 2500;
BA_ "GenSigTimeoutMsg_HU_B" SG_ 946 RevLampMalFnStatus 2500;
BA_ "GenSigTimeoutMsg_HU_A" SG_ 946 RevLampMalFnStatus 2500;
BA_ "GenSigSendType" SG_ 946 RevLampMalFnStatus 7;
BA_ "GenSigCycleTimeActive" SG_ 946 RevLampMalFnStatus 500;
BA_ "GenSigCycleTime" SG_ 946 RevLampMalFnStatus 500;
BA_ "GenSigTimeoutMsg_HU_High_X445" SG_ 946 RevLampMalFnStatus 2500;
BA_ "GenSigTimeoutMsg_HU_Mid_X445" SG_ 946 RevLampMalFnStatus 2500;
BA_ "GenSigTimeoutTime_HU_High_X445" SG_ 946 RevLampMalFnStatus 2500;
BA_ "GenSigTimeoutTime_HU_Mid_X445" SG_ 946 RevLampMalFnStatus 2500;
BA_ "GenSigTimeoutMsg_IVI" SG_ 946 RevLampMalFnStatus 2500;
BA_ "GenSigTimeoutTime_IVI" SG_ 946 RevLampMalFnStatus 2500;
BA_ "GenSigTimeoutTime_HU_Mid_X451" SG_ 946 LowBeamMalFn 2500;
BA_ "GenSigTimeoutTime_HU_High_X451" SG_ 946 LowBeamMalFn 2500;
BA_ "GenSigTimeoutTime_HU_B" SG_ 946 LowBeamMalFn 2500;
BA_ "GenSigTimeoutTime_HU_A" SG_ 946 LowBeamMalFn 2500;
BA_ "GenSigTimeoutMsg_HU_Mid_X451" SG_ 946 LowBeamMalFn 2500;
BA_ "GenSigTimeoutMsg_HU_High_X451" SG_ 946 LowBeamMalFn 2500;
BA_ "GenSigTimeoutMsg_HU_B" SG_ 946 LowBeamMalFn 2500;
BA_ "GenSigTimeoutMsg_HU_A" SG_ 946 LowBeamMalFn 2500;
BA_ "GenSigSendType" SG_ 946 LowBeamMalFn 7;
BA_ "GenSigCycleTimeActive" SG_ 946 LowBeamMalFn 500;
BA_ "GenSigCycleTime" SG_ 946 LowBeamMalFn 500;
BA_ "GenSigTimeoutMsg_HU_High_X445" SG_ 946 LowBeamMalFn 2500;
BA_ "GenSigTimeoutMsg_HU_Mid_X445" SG_ 946 LowBeamMalFn 2500;
BA_ "GenSigTimeoutTime_HU_High_X445" SG_ 946 LowBeamMalFn 2500;
BA_ "GenSigTimeoutTime_HU_Mid_X445" SG_ 946 LowBeamMalFn 2500;
BA_ "GenSigTimeoutMsg_IVI" SG_ 946 LowBeamMalFn 2500;
BA_ "GenSigTimeoutTime_IVI" SG_ 946 LowBeamMalFn 2500;
BA_ "GenSigTimeoutTime_HU_Mid_X451" SG_ 946 DRLTelltale 2500;
BA_ "GenSigTimeoutTime_HU_High_X451" SG_ 946 DRLTelltale 2500;
BA_ "GenSigTimeoutTime_HU_B" SG_ 946 DRLTelltale 2500;
BA_ "GenSigTimeoutTime_HU_A" SG_ 946 DRLTelltale 2500;
BA_ "GenSigTimeoutMsg_HU_Mid_X451" SG_ 946 DRLTelltale 2500;
BA_ "GenSigTimeoutMsg_HU_High_X451" SG_ 946 DRLTelltale 2500;
BA_ "GenSigTimeoutMsg_HU_B" SG_ 946 DRLTelltale 2500;
BA_ "GenSigTimeoutMsg_HU_A" SG_ 946 DRLTelltale 2500;
BA_ "GenSigSendType" SG_ 946 DRLTelltale 7;
BA_ "GenSigCycleTimeActive" SG_ 946 DRLTelltale 500;
BA_ "GenSigCycleTime" SG_ 946 DRLTelltale 500;
BA_ "GenSigTimeoutMsg_HU_High_X445" SG_ 946 DRLTelltale 2500;
BA_ "GenSigTimeoutMsg_HU_Mid_X445" SG_ 946 DRLTelltale 2500;
BA_ "GenSigTimeoutTime_HU_High_X445" SG_ 946 DRLTelltale 2500;
BA_ "GenSigTimeoutTime_HU_Mid_X445" SG_ 946 DRLTelltale 2500;
BA_ "GenSigTimeoutMsg_IVI" SG_ 946 DRLTelltale 2500;
BA_ "GenSigTimeoutTime_IVI" SG_ 946 DRLTelltale 2500;
BA_ "GenSigTimeoutTime_HU_Mid_X451" SG_ 946 FrontFogTelltale 2500;
BA_ "GenSigTimeoutTime_HU_High_X451" SG_ 946 FrontFogTelltale 2500;
BA_ "GenSigTimeoutTime_HU_B" SG_ 946 FrontFogTelltale 2500;
BA_ "GenSigTimeoutTime_HU_A" SG_ 946 FrontFogTelltale 2500;
BA_ "GenSigTimeoutMsg_HU_Mid_X451" SG_ 946 FrontFogTelltale 2500;
BA_ "GenSigTimeoutMsg_HU_High_X451" SG_ 946 FrontFogTelltale 2500;
BA_ "GenSigTimeoutMsg_HU_B" SG_ 946 FrontFogTelltale 2500;
BA_ "GenSigTimeoutMsg_HU_A" SG_ 946 FrontFogTelltale 2500;
BA_ "GenSigSendType" SG_ 946 FrontFogTelltale 7;
BA_ "GenSigCycleTimeActive" SG_ 946 FrontFogTelltale 500;
BA_ "GenSigCycleTime" SG_ 946 FrontFogTelltale 500;
BA_ "GenSigTimeoutMsg_HU_High_X445" SG_ 946 FrontFogTelltale 2500;
BA_ "GenSigTimeoutMsg_HU_Mid_X445" SG_ 946 FrontFogTelltale 2500;
BA_ "GenSigTimeoutTime_HU_High_X445" SG_ 946 FrontFogTelltale 2500;
BA_ "GenSigTimeoutTime_HU_Mid_X445" SG_ 946 FrontFogTelltale 2500;
BA_ "GenSigTimeoutMsg_IVI" SG_ 946 FrontFogTelltale 2500;
BA_ "GenSigTimeoutTime_IVI" SG_ 946 FrontFogTelltale 2500;
BA_ "GenSigTimeoutTime_HU_Mid_X451" SG_ 946 RearFogTelltaleStatus 2500;
BA_ "GenSigTimeoutTime_HU_High_X451" SG_ 946 RearFogTelltaleStatus 2500;
BA_ "GenSigTimeoutTime_HU_B" SG_ 946 RearFogTelltaleStatus 2500;
BA_ "GenSigTimeoutTime_HU_A" SG_ 946 RearFogTelltaleStatus 2500;
BA_ "GenSigTimeoutMsg_HU_Mid_X451" SG_ 946 RearFogTelltaleStatus 2500;
BA_ "GenSigTimeoutMsg_HU_High_X451" SG_ 946 RearFogTelltaleStatus 2500;
BA_ "GenSigTimeoutMsg_HU_B" SG_ 946 RearFogTelltaleStatus 2500;
BA_ "GenSigTimeoutMsg_HU_A" SG_ 946 RearFogTelltaleStatus 2500;
BA_ "GenSigSendType" SG_ 946 RearFogTelltaleStatus 7;
BA_ "GenSigCycleTimeActive" SG_ 946 RearFogTelltaleStatus 500;
BA_ "GenSigCycleTime" SG_ 946 RearFogTelltaleStatus 500;
BA_ "GenSigTimeoutMsg_HU_High_X445" SG_ 946 RearFogTelltaleStatus 2500;
BA_ "GenSigTimeoutMsg_HU_Mid_X445" SG_ 946 RearFogTelltaleStatus 2500;
BA_ "GenSigTimeoutTime_HU_High_X445" SG_ 946 RearFogTelltaleStatus 2500;
BA_ "GenSigTimeoutTime_HU_Mid_X445" SG_ 946 RearFogTelltaleStatus 2500;
BA_ "GenSigTimeoutMsg_IVI" SG_ 946 RearFogTelltaleStatus 2500;
BA_ "GenSigTimeoutTime_IVI" SG_ 946 RearFogTelltaleStatus 2500;
BA_ "GenSigTimeoutTime_HU_Mid_X451" SG_ 946 FrontFogTelltaleStatus 2500;
BA_ "GenSigTimeoutTime_HU_High_X451" SG_ 946 FrontFogTelltaleStatus 2500;
BA_ "GenSigTimeoutTime_HU_B" SG_ 946 FrontFogTelltaleStatus 2500;
BA_ "GenSigTimeoutTime_HU_A" SG_ 946 FrontFogTelltaleStatus 2500;
BA_ "GenSigTimeoutMsg_HU_Mid_X451" SG_ 946 FrontFogTelltaleStatus 2500;
BA_ "GenSigTimeoutMsg_HU_High_X451" SG_ 946 FrontFogTelltaleStatus 2500;
BA_ "GenSigTimeoutMsg_HU_B" SG_ 946 FrontFogTelltaleStatus 2500;
BA_ "GenSigTimeoutMsg_HU_A" SG_ 946 FrontFogTelltaleStatus 2500;
BA_ "GenSigSendType" SG_ 946 FrontFogTelltaleStatus 7;
BA_ "GenSigCycleTimeActive" SG_ 946 FrontFogTelltaleStatus 500;
BA_ "GenSigCycleTime" SG_ 946 FrontFogTelltaleStatus 500;
BA_ "GenSigTimeoutMsg_HU_High_X445" SG_ 946 FrontFogTelltaleStatus 2500;
BA_ "GenSigTimeoutMsg_HU_Mid_X445" SG_ 946 FrontFogTelltaleStatus 2500;
BA_ "GenSigTimeoutTime_HU_High_X445" SG_ 946 FrontFogTelltaleStatus 2500;
BA_ "GenSigTimeoutTime_HU_Mid_X445" SG_ 946 FrontFogTelltaleStatus 2500;
BA_ "GenSigTimeoutMsg_IVI" SG_ 946 FrontFogTelltaleStatus 2500;
BA_ "GenSigTimeoutTime_IVI" SG_ 946 FrontFogTelltaleStatus 2500;
BA_ "GenSigTimeoutTime_HU_Mid_X451" SG_ 946 DRLTelltaleStatus 2500;
BA_ "GenSigTimeoutTime_HU_High_X451" SG_ 946 DRLTelltaleStatus 2500;
BA_ "GenSigTimeoutTime_HU_B" SG_ 946 DRLTelltaleStatus 2500;
BA_ "GenSigTimeoutTime_HU_A" SG_ 946 DRLTelltaleStatus 2500;
BA_ "GenSigTimeoutMsg_HU_Mid_X451" SG_ 946 DRLTelltaleStatus 2500;
BA_ "GenSigTimeoutMsg_HU_High_X451" SG_ 946 DRLTelltaleStatus 2500;
BA_ "GenSigTimeoutMsg_HU_B" SG_ 946 DRLTelltaleStatus 2500;
BA_ "GenSigTimeoutMsg_HU_A" SG_ 946 DRLTelltaleStatus 2500;
BA_ "GenSigSendType" SG_ 946 DRLTelltaleStatus 7;
BA_ "GenSigCycleTimeActive" SG_ 946 DRLTelltaleStatus 500;
BA_ "GenSigCycleTime" SG_ 946 DRLTelltaleStatus 500;
BA_ "GenSigTimeoutMsg_HU_High_X445" SG_ 946 DRLTelltaleStatus 2500;
BA_ "GenSigTimeoutMsg_HU_Mid_X445" SG_ 946 DRLTelltaleStatus 2500;
BA_ "GenSigTimeoutTime_HU_High_X445" SG_ 946 DRLTelltaleStatus 2500;
BA_ "GenSigTimeoutTime_HU_Mid_X445" SG_ 946 DRLTelltaleStatus 2500;
BA_ "GenSigTimeoutMsg_IVI" SG_ 946 DRLTelltaleStatus 2500;
BA_ "GenSigTimeoutTime_IVI" SG_ 946 DRLTelltaleStatus 2500;
BA_ "GenSigTimeoutTime_HU_Mid_X451" SG_ 946 LowBeamMalFnStatus 2500;
BA_ "GenSigTimeoutTime_HU_High_X451" SG_ 946 LowBeamMalFnStatus 2500;
BA_ "GenSigTimeoutTime_HU_B" SG_ 946 LowBeamMalFnStatus 2500;
BA_ "GenSigTimeoutTime_HU_A" SG_ 946 LowBeamMalFnStatus 2500;
BA_ "GenSigTimeoutMsg_HU_Mid_X451" SG_ 946 LowBeamMalFnStatus 2500;
BA_ "GenSigTimeoutMsg_HU_High_X451" SG_ 946 LowBeamMalFnStatus 2500;
BA_ "GenSigTimeoutMsg_HU_B" SG_ 946 LowBeamMalFnStatus 2500;
BA_ "GenSigTimeoutMsg_HU_A" SG_ 946 LowBeamMalFnStatus 2500;
BA_ "GenSigSendType" SG_ 946 LowBeamMalFnStatus 7;
BA_ "GenSigCycleTimeActive" SG_ 946 LowBeamMalFnStatus 500;
BA_ "GenSigCycleTime" SG_ 946 LowBeamMalFnStatus 500;
BA_ "GenSigTimeoutMsg_HU_High_X445" SG_ 946 LowBeamMalFnStatus 2500;
BA_ "GenSigTimeoutMsg_HU_Mid_X445" SG_ 946 LowBeamMalFnStatus 2500;
BA_ "GenSigTimeoutTime_HU_High_X445" SG_ 946 LowBeamMalFnStatus 2500;
BA_ "GenSigTimeoutTime_HU_Mid_X445" SG_ 946 LowBeamMalFnStatus 2500;
BA_ "GenSigTimeoutMsg_IVI" SG_ 946 LowBeamMalFnStatus 2500;
BA_ "GenSigTimeoutTime_IVI" SG_ 946 LowBeamMalFnStatus 2500;
BA_ "GenSigTimeoutTime_HU_Mid_X451" SG_ 946 BonnetState 2500;
BA_ "GenSigTimeoutTime_HU_High_X451" SG_ 946 BonnetState 2500;
BA_ "GenSigTimeoutTime_HU_B" SG_ 946 BonnetState 2500;
BA_ "GenSigTimeoutTime_HU_A" SG_ 946 BonnetState 2500;
BA_ "GenSigTimeoutMsg_HU_Mid_X451" SG_ 946 BonnetState 2500;
BA_ "GenSigTimeoutMsg_HU_High_X451" SG_ 946 BonnetState 2500;
BA_ "GenSigTimeoutMsg_HU_B" SG_ 946 BonnetState 2500;
BA_ "GenSigTimeoutMsg_HU_A" SG_ 946 BonnetState 2500;
BA_ "GenSigSendType" SG_ 946 BonnetState 7;
BA_ "GenSigCycleTimeActive" SG_ 946 BonnetState 500;
BA_ "GenSigCycleTime" SG_ 946 BonnetState 500;
BA_ "GenSigTimeoutMsg_HU_High_X445" SG_ 946 BonnetState 2500;
BA_ "GenSigTimeoutMsg_HU_Mid_X445" SG_ 946 BonnetState 2500;
BA_ "GenSigTimeoutTime_HU_High_X445" SG_ 946 BonnetState 2500;
BA_ "GenSigTimeoutTime_HU_Mid_X445" SG_ 946 BonnetState 2500;
BA_ "GenSigTimeoutMsg_IVI" SG_ 946 BonnetState 2500;
BA_ "GenSigTimeoutTime_IVI" SG_ 946 BonnetState 2500;
BA_ "GenSigTimeoutTime_HU_Mid_X451" SG_ 946 RearFogTelltale 2500;
BA_ "GenSigTimeoutTime_HU_High_X451" SG_ 946 RearFogTelltale 2500;
BA_ "GenSigTimeoutTime_HU_B" SG_ 946 RearFogTelltale 2500;
BA_ "GenSigTimeoutTime_HU_A" SG_ 946 RearFogTelltale 2500;
BA_ "GenSigTimeoutMsg_HU_Mid_X451" SG_ 946 RearFogTelltale 2500;
BA_ "GenSigTimeoutMsg_HU_High_X451" SG_ 946 RearFogTelltale 2500;
BA_ "GenSigTimeoutMsg_HU_B" SG_ 946 RearFogTelltale 2500;
BA_ "GenSigTimeoutMsg_HU_A" SG_ 946 RearFogTelltale 2500;
BA_ "GenSigSendType" SG_ 946 RearFogTelltale 7;
BA_ "GenSigCycleTimeActive" SG_ 946 RearFogTelltale 500;
BA_ "GenSigCycleTime" SG_ 946 RearFogTelltale 500;
BA_ "GenSigTimeoutMsg_HU_High_X445" SG_ 946 RearFogTelltale 2500;
BA_ "GenSigTimeoutMsg_HU_Mid_X445" SG_ 946 RearFogTelltale 2500;
BA_ "GenSigTimeoutTime_HU_High_X445" SG_ 946 RearFogTelltale 2500;
BA_ "GenSigTimeoutTime_HU_Mid_X445" SG_ 946 RearFogTelltale 2500;
BA_ "GenSigTimeoutMsg_IVI" SG_ 946 RearFogTelltale 2500;
BA_ "GenSigTimeoutTime_IVI" SG_ 946 RearFogTelltale 2500;
BA_ "GenSigTimeoutTime_HU_Mid_X451" SG_ 946 BonnetStateStatus 2500;
BA_ "GenSigTimeoutTime_HU_High_X451" SG_ 946 BonnetStateStatus 2500;
BA_ "GenSigTimeoutTime_HU_B" SG_ 946 BonnetStateStatus 2500;
BA_ "GenSigTimeoutTime_HU_A" SG_ 946 BonnetStateStatus 2500;
BA_ "GenSigTimeoutMsg_HU_Mid_X451" SG_ 946 BonnetStateStatus 2500;
BA_ "GenSigTimeoutMsg_HU_High_X451" SG_ 946 BonnetStateStatus 2500;
BA_ "GenSigTimeoutMsg_HU_B" SG_ 946 BonnetStateStatus 2500;
BA_ "GenSigTimeoutMsg_HU_A" SG_ 946 BonnetStateStatus 2500;
BA_ "GenSigSendType" SG_ 946 BonnetStateStatus 7;
BA_ "GenSigCycleTimeActive" SG_ 946 BonnetStateStatus 500;
BA_ "GenSigCycleTime" SG_ 946 BonnetStateStatus 500;
BA_ "GenSigTimeoutMsg_HU_High_X445" SG_ 946 BonnetStateStatus 2500;
BA_ "GenSigTimeoutMsg_HU_Mid_X445" SG_ 946 BonnetStateStatus 2500;
BA_ "GenSigTimeoutTime_HU_High_X445" SG_ 946 BonnetStateStatus 2500;
BA_ "GenSigTimeoutTime_HU_Mid_X445" SG_ 946 BonnetStateStatus 2500;
BA_ "GenSigTimeoutMsg_IVI" SG_ 946 BonnetStateStatus 2500;
BA_ "GenSigTimeoutTime_IVI" SG_ 946 BonnetStateStatus 2500;
BA_ "GenSigTimeoutTime_HU_Mid_X451" SG_ 948 OdoICFullSigPeriodic 2500;
BA_ "GenSigTimeoutTime_HU_High_X451" SG_ 948 OdoICFullSigPeriodic 2500;
BA_ "GenSigTimeoutTime_HU_B" SG_ 948 OdoICFullSigPeriodic 2500;
BA_ "GenSigTimeoutTime_HU_A" SG_ 948 OdoICFullSigPeriodic 2500;
BA_ "GenSigTimeoutMsg_HU_Mid_X451" SG_ 948 OdoICFullSigPeriodic 2500;
BA_ "GenSigTimeoutMsg_HU_High_X451" SG_ 948 OdoICFullSigPeriodic 2500;
BA_ "GenSigTimeoutMsg_HU_B" SG_ 948 OdoICFullSigPeriodic 2500;
BA_ "GenSigTimeoutMsg_HU_A" SG_ 948 OdoICFullSigPeriodic 2500;
BA_ "GenSigSendType" SG_ 948 OdoICFullSigPeriodic 7;
BA_ "GenSigCycleTimeActive" SG_ 948 OdoICFullSigPeriodic 500;
BA_ "GenSigCycleTime" SG_ 948 OdoICFullSigPeriodic 500;
BA_ "GenSigTimeoutMsg_HU_High_X445" SG_ 948 OdoICFullSigPeriodic 2500;
BA_ "GenSigTimeoutMsg_HU_Mid_X445" SG_ 948 OdoICFullSigPeriodic 2500;
BA_ "GenSigTimeoutTime_HU_High_X445" SG_ 948 OdoICFullSigPeriodic 2500;
BA_ "GenSigTimeoutTime_HU_Mid_X445" SG_ 948 OdoICFullSigPeriodic 2500;
BA_ "GenSigTimeoutMsg_IVI" SG_ 948 OdoICFullSigPeriodic 2500;
BA_ "GenSigTimeoutTime_IVI" SG_ 948 OdoICFullSigPeriodic 2500;
BA_ "GenSigTimeoutTime_HU_Mid_X451" SG_ 948 OdoICFullSigPeriodicStatus 2500;
BA_ "GenSigTimeoutTime_HU_High_X451" SG_ 948 OdoICFullSigPeriodicStatus 2500;
BA_ "GenSigTimeoutTime_HU_B" SG_ 948 OdoICFullSigPeriodicStatus 2500;
BA_ "GenSigTimeoutTime_HU_A" SG_ 948 OdoICFullSigPeriodicStatus 2500;
BA_ "GenSigTimeoutMsg_HU_Mid_X451" SG_ 948 OdoICFullSigPeriodicStatus 2500;
BA_ "GenSigTimeoutMsg_HU_High_X451" SG_ 948 OdoICFullSigPeriodicStatus 2500;
BA_ "GenSigTimeoutMsg_HU_B" SG_ 948 OdoICFullSigPeriodicStatus 2500;
BA_ "GenSigTimeoutMsg_HU_A" SG_ 948 OdoICFullSigPeriodicStatus 2500;
BA_ "GenSigSendType" SG_ 948 OdoICFullSigPeriodicStatus 7;
BA_ "GenSigCycleTimeActive" SG_ 948 OdoICFullSigPeriodicStatus 500;
BA_ "GenSigCycleTime" SG_ 948 OdoICFullSigPeriodicStatus 500;
BA_ "GenSigTimeoutMsg_HU_High_X445" SG_ 948 OdoICFullSigPeriodicStatus 2500;
BA_ "GenSigTimeoutMsg_HU_Mid_X445" SG_ 948 OdoICFullSigPeriodicStatus 2500;
BA_ "GenSigTimeoutTime_HU_High_X445" SG_ 948 OdoICFullSigPeriodicStatus 2500;
BA_ "GenSigTimeoutTime_HU_Mid_X445" SG_ 948 OdoICFullSigPeriodicStatus 2500;
BA_ "GenSigTimeoutMsg_IVI" SG_ 948 OdoICFullSigPeriodicStatus 2500;
BA_ "GenSigTimeoutTime_IVI" SG_ 948 OdoICFullSigPeriodicStatus 2500;
BA_ "GenSigTimeoutTime_HU_Mid_X451" SG_ 1068 ICDrvModeFunVariant 5000;
BA_ "GenSigTimeoutTime_HU_High_X451" SG_ 1068 ICDrvModeFunVariant 5000;
BA_ "GenSigTimeoutTime_HU_B" SG_ 1068 ICDrvModeFunVariant 5000;
BA_ "GenSigTimeoutTime_HU_A" SG_ 1068 ICDrvModeFunVariant 5000;
BA_ "GenSigTimeoutMsg_HU_Mid_X451" SG_ 1068 ICDrvModeFunVariant 5000;
BA_ "GenSigTimeoutMsg_HU_High_X451" SG_ 1068 ICDrvModeFunVariant 5000;
BA_ "GenSigTimeoutMsg_HU_B" SG_ 1068 ICDrvModeFunVariant 5000;
BA_ "GenSigTimeoutMsg_HU_A" SG_ 1068 ICDrvModeFunVariant 5000;
BA_ "GenSigSendType" SG_ 1068 ICDrvModeFunVariant 7;
BA_ "GenSigCycleTimeActive" SG_ 1068 ICDrvModeFunVariant 1000;
BA_ "GenSigCycleTime" SG_ 1068 ICDrvModeFunVariant 1000;
BA_ "GenSigTimeoutMsg_HU_High_X445" SG_ 1068 ICDrvModeFunVariant 5000;
BA_ "GenSigTimeoutMsg_HU_Mid_X445" SG_ 1068 ICDrvModeFunVariant 5000;
BA_ "GenSigTimeoutTime_HU_High_X445" SG_ 1068 ICDrvModeFunVariant 5000;
BA_ "GenSigTimeoutTime_HU_Mid_X445" SG_ 1068 ICDrvModeFunVariant 5000;
BA_ "GenSigTimeoutMsg_IVI" SG_ 1068 ICDrvModeFunVariant 5000;
BA_ "GenSigTimeoutTime_IVI" SG_ 1068 ICDrvModeFunVariant 5000;
BA_ "GenSigTimeoutTime_HU_Mid_X451" SG_ 1069 IcHuVcInfonew 5000;
BA_ "GenSigTimeoutTime_HU_High_X451" SG_ 1069 IcHuVcInfonew 5000;
BA_ "GenSigTimeoutTime_HU_B" SG_ 1069 IcHuVcInfonew 5000;
BA_ "GenSigTimeoutTime_HU_A" SG_ 1069 IcHuVcInfonew 5000;
BA_ "GenSigTimeoutMsg_HU_Mid_X451" SG_ 1069 IcHuVcInfonew 5000;
BA_ "GenSigTimeoutMsg_HU_High_X451" SG_ 1069 IcHuVcInfonew 5000;
BA_ "GenSigTimeoutMsg_HU_B" SG_ 1069 IcHuVcInfonew 5000;
BA_ "GenSigTimeoutMsg_HU_A" SG_ 1069 IcHuVcInfonew 5000;
BA_ "GenSigSendType" SG_ 1069 IcHuVcInfonew 7;
BA_ "GenSigCycleTimeActive" SG_ 1069 IcHuVcInfonew 1000;
BA_ "GenSigCycleTime" SG_ 1069 IcHuVcInfonew 1000;
BA_ "GenSigTimeoutMsg_HU_High_X445" SG_ 1069 IcHuVcInfonew 5000;
BA_ "GenSigTimeoutMsg_HU_Mid_X445" SG_ 1069 IcHuVcInfonew 5000;
BA_ "GenSigTimeoutTime_HU_High_X445" SG_ 1069 IcHuVcInfonew 5000;
BA_ "GenSigTimeoutTime_HU_Mid_X445" SG_ 1069 IcHuVcInfonew 5000;
BA_ "GenSigTimeoutMsg_IVI" SG_ 1069 IcHuVcInfonew 5000;
BA_ "GenSigTimeoutTime_IVI" SG_ 1069 IcHuVcInfonew 5000;
BA_ "GenSigTimeoutTime_HU_Mid_X451" SG_ 1120 HuIcTpSig 0;
BA_ "GenSigTimeoutTime_HU_High_X451" SG_ 1120 HuIcTpSig 0;
BA_ "GenSigTimeoutTime_HU_B" SG_ 1120 HuIcTpSig 0;
BA_ "GenSigTimeoutTime_HU_A" SG_ 1120 HuIcTpSig 0;
BA_ "GenSigTimeoutMsg_HU_Mid_X451" SG_ 1120 HuIcTpSig 0;
BA_ "GenSigTimeoutMsg_HU_High_X451" SG_ 1120 HuIcTpSig 0;
BA_ "GenSigTimeoutMsg_HU_B" SG_ 1120 HuIcTpSig 0;
BA_ "GenSigTimeoutMsg_HU_A" SG_ 1120 HuIcTpSig 0;
BA_ "GenSigSendType" SG_ 1120 HuIcTpSig 1;
BA_ "GenSigTimeoutMsg_HU_High_X445" SG_ 1120 HuIcTpSig 0;
BA_ "GenSigTimeoutMsg_HU_Mid_X445" SG_ 1120 HuIcTpSig 0;
BA_ "GenSigTimeoutTime_HU_High_X445" SG_ 1120 HuIcTpSig 0;
BA_ "GenSigTimeoutTime_HU_Mid_X445" SG_ 1120 HuIcTpSig 0;
BA_ "GenSigTimeoutMsg_IVI" SG_ 1120 HuIcTpSig 0;
BA_ "GenSigTimeoutTime_IVI" SG_ 1120 HuIcTpSig 0;
BA_ "GenSigTimeoutTime_HU_Mid_X451" SG_ 1121 IcHuTpSig 0;
BA_ "GenSigTimeoutTime_HU_High_X451" SG_ 1121 IcHuTpSig 0;
BA_ "GenSigTimeoutTime_HU_B" SG_ 1121 IcHuTpSig 0;
BA_ "GenSigTimeoutTime_HU_A" SG_ 1121 IcHuTpSig 0;
BA_ "GenSigTimeoutMsg_HU_Mid_X451" SG_ 1121 IcHuTpSig 0;
BA_ "GenSigTimeoutMsg_HU_High_X451" SG_ 1121 IcHuTpSig 0;
BA_ "GenSigTimeoutMsg_HU_B" SG_ 1121 IcHuTpSig 0;
BA_ "GenSigTimeoutMsg_HU_A" SG_ 1121 IcHuTpSig 0;
BA_ "GenSigSendType" SG_ 1121 IcHuTpSig 1;
BA_ "GenSigTimeoutMsg_HU_High_X445" SG_ 1121 IcHuTpSig 0;
BA_ "GenSigTimeoutMsg_HU_Mid_X445" SG_ 1121 IcHuTpSig 0;
BA_ "GenSigTimeoutTime_HU_High_X445" SG_ 1121 IcHuTpSig 0;
BA_ "GenSigTimeoutTime_HU_Mid_X445" SG_ 1121 IcHuTpSig 0;
BA_ "GenSigTimeoutMsg_IVI" SG_ 1121 IcHuTpSig 0;
BA_ "GenSigTimeoutTime_IVI" SG_ 1121 IcHuTpSig 0;
BA_ "GenSigSendType" SG_ 1173 SRR_MTO_Failure_Status 7;
BA_ "GenSigCycleTimeActive" SG_ 1173 SRR_MTO_Failure_Status 100;
BA_ "GenSigCycleTime" SG_ 1173 SRR_MTO_Failure_Status 100;
BA_ "GenSigSendType" SG_ 1173 FCmMToFailureStatus 7;
BA_ "GenSigCycleTimeActive" SG_ 1173 FCmMToFailureStatus 100;
BA_ "GenSigCycleTime" SG_ 1173 FCmMToFailureStatus 100;
BA_ "GenSigSendType" SG_ 1173 Telematics_Invalid_FailureStatus 7;
BA_ "GenSigCycleTimeActive" SG_ 1173 Telematics_Invalid_FailureStatus 100;
BA_ "GenSigCycleTime" SG_ 1173 Telematics_Invalid_FailureStatus 100;
BA_ "GenSigSendType" SG_ 1173 VCUMToFailureStatus 7;
BA_ "GenSigCycleTimeActive" SG_ 1173 VCUMToFailureStatus 100;
BA_ "GenSigCycleTime" SG_ 1173 VCUMToFailureStatus 100;
BA_ "GenSigSendType" SG_ 1173 VCUInvalidFailureStatus 7;
BA_ "GenSigCycleTimeActive" SG_ 1173 VCUInvalidFailureStatus 100;
BA_ "GenSigCycleTime" SG_ 1173 VCUInvalidFailureStatus 100;
BA_ "GenSigSendType" SG_ 1173 Telematics_MTO_Failure_status 7;
BA_ "GenSigCycleTimeActive" SG_ 1173 Telematics_MTO_Failure_status 100;
BA_ "GenSigCycleTime" SG_ 1173 Telematics_MTO_Failure_status 100;
BA_ "GenSigSendType" SG_ 1173 HU_SW_Version 7;
BA_ "GenSigCycleTimeActive" SG_ 1173 HU_SW_Version 100;
BA_ "GenSigCycleTime" SG_ 1173 HU_SW_Version 100;
BA_ "GenSigSendType" SG_ 1173 EMsInvalidFailureStatus 7;
BA_ "GenSigCycleTimeActive" SG_ 1173 EMsInvalidFailureStatus 100;
BA_ "GenSigCycleTime" SG_ 1173 EMsInvalidFailureStatus 100;
BA_ "GenSigSendType" SG_ 1173 AMT_AT_DCT_MTO_Failure_Status 7;
BA_ "GenSigCycleTimeActive" SG_ 1173 AMT_AT_DCT_MTO_Failure_Status 100;
BA_ "GenSigCycleTime" SG_ 1173 AMT_AT_DCT_MTO_Failure_Status 100;
BA_ "GenSigSendType" SG_ 1173 AMT_AT_DCT_Invalid_Failure_Statu 7;
BA_ "GenSigCycleTimeActive" SG_ 1173 AMT_AT_DCT_Invalid_Failure_Statu 100;
BA_ "GenSigCycleTime" SG_ 1173 AMT_AT_DCT_Invalid_Failure_Statu 100;
BA_ "SystemSignalLongSymbol" SG_ 1173 AMT_AT_DCT_Invalid_Failure_Statu "AMT_AT_DCT_Invalid_Failure_Status";
BA_ "GenSigSendType" SG_ 1173 ESpMToFailureStatus 7;
BA_ "GenSigCycleTimeActive" SG_ 1173 ESpMToFailureStatus 100;
BA_ "GenSigCycleTime" SG_ 1173 ESpMToFailureStatus 100;
BA_ "GenSigSendType" SG_ 1173 ESpInvalidFailureStatus 7;
BA_ "GenSigCycleTimeActive" SG_ 1173 ESpInvalidFailureStatus 100;
BA_ "GenSigCycleTime" SG_ 1173 ESpInvalidFailureStatus 100;
BA_ "GenSigSendType" SG_ 1173 CCM_Invalid_Failure_Status 7;
BA_ "GenSigCycleTimeActive" SG_ 1173 CCM_Invalid_Failure_Status 100;
BA_ "GenSigCycleTime" SG_ 1173 CCM_Invalid_Failure_Status 100;
BA_ "GenSigSendType" SG_ 1173 SRS_MTO_Failure_Status 7;
BA_ "GenSigCycleTimeActive" SG_ 1173 SRS_MTO_Failure_Status 100;
BA_ "GenSigCycleTime" SG_ 1173 SRS_MTO_Failure_Status 100;
BA_ "GenSigSendType" SG_ 1173 EMsMToFailureStatus 7;
BA_ "GenSigCycleTimeActive" SG_ 1173 EMsMToFailureStatus 100;
BA_ "GenSigCycleTime" SG_ 1173 EMsMToFailureStatus 100;
BA_ "GenSigSendType" SG_ 1173 PDC_MTO_Failure_Status 7;
BA_ "GenSigCycleTimeActive" SG_ 1173 PDC_MTO_Failure_Status 100;
BA_ "GenSigCycleTime" SG_ 1173 PDC_MTO_Failure_Status 100;
BA_ "GenSigSendType" SG_ 1173 IPcMToFailureStatus 7;
BA_ "GenSigCycleTimeActive" SG_ 1173 IPcMToFailureStatus 100;
BA_ "GenSigCycleTime" SG_ 1173 IPcMToFailureStatus 100;
BA_ "GenSigSendType" SG_ 1173 IPcInvalidFailureStatus 7;
BA_ "GenSigCycleTimeActive" SG_ 1173 IPcInvalidFailureStatus 100;
BA_ "GenSigCycleTime" SG_ 1173 IPcInvalidFailureStatus 100;
BA_ "GenSigSendType" SG_ 1173 PDC_Invalid_Failure_Status 7;
BA_ "GenSigCycleTimeActive" SG_ 1173 PDC_Invalid_Failure_Status 100;
BA_ "GenSigCycleTime" SG_ 1173 PDC_Invalid_Failure_Status 100;
BA_ "GenSigSendType" SG_ 1173 SAS_Invalid_Failure_Status 7;
BA_ "GenSigCycleTimeActive" SG_ 1173 SAS_Invalid_Failure_Status 100;
BA_ "GenSigCycleTime" SG_ 1173 SAS_Invalid_Failure_Status 100;
BA_ "GenSigSendType" SG_ 1173 SAS_MTO_Failure_Status 7;
BA_ "GenSigCycleTimeActive" SG_ 1173 SAS_MTO_Failure_Status 100;
BA_ "GenSigCycleTime" SG_ 1173 SAS_MTO_Failure_Status 100;
BA_ "GenSigSendType" SG_ 1173 EPAS_MTO_Failure_Status 7;
BA_ "GenSigCycleTimeActive" SG_ 1173 EPAS_MTO_Failure_Status 100;
BA_ "GenSigCycleTime" SG_ 1173 EPAS_MTO_Failure_Status 100;
BA_ "GenSigSendType" SG_ 1173 EPAS_Invalid_Failure_Status 7;
BA_ "GenSigCycleTimeActive" SG_ 1173 EPAS_Invalid_Failure_Status 100;
BA_ "GenSigCycleTime" SG_ 1173 EPAS_Invalid_Failure_Status 100;
BA_ "GenSigSendType" SG_ 1173 TPMS_MTO_Failure_status 7;
BA_ "GenSigCycleTimeActive" SG_ 1173 TPMS_MTO_Failure_status 100;
BA_ "GenSigCycleTime" SG_ 1173 TPMS_MTO_Failure_status 100;
BA_ "GenSigSendType" SG_ 1173 CCM_MTO_Failure_Status 7;
BA_ "GenSigCycleTimeActive" SG_ 1173 CCM_MTO_Failure_Status 100;
BA_ "GenSigCycleTime" SG_ 1173 CCM_MTO_Failure_Status 100;
BA_ "GenSigSendType" SG_ 1173 HU_EP_Failure_Status 7;
BA_ "GenSigCycleTimeActive" SG_ 1173 HU_EP_Failure_Status 100;
BA_ "GenSigCycleTime" SG_ 1173 HU_EP_Failure_Status 100;
BA_ "GenSigSendType" SG_ 1173 PEPS_MTO_Failure_Status 7;
BA_ "GenSigCycleTimeActive" SG_ 1173 PEPS_MTO_Failure_Status 100;
BA_ "GenSigCycleTime" SG_ 1173 PEPS_MTO_Failure_Status 100;
BA_ "GenSigSendType" SG_ 1173 BCmMToFailureStatus 7;
BA_ "GenSigCycleTimeActive" SG_ 1173 BCmMToFailureStatus 100;
BA_ "GenSigCycleTime" SG_ 1173 BCmMToFailureStatus 100;
BA_ "GenSigSendType" SG_ 1173 HU_BO_Failure_Status 7;
BA_ "GenSigCycleTimeActive" SG_ 1173 HU_BO_Failure_Status 100;
BA_ "GenSigCycleTime" SG_ 1173 HU_BO_Failure_Status 100;
BA_ "GenSigSendType" SG_ 1174 BattVolt_HU1 7;
BA_ "GenSigCycleTimeActive" SG_ 1174 BattVolt_HU1 100;
BA_ "GenSigCycleTime" SG_ 1174 BattVolt_HU1 100;
BA_ "GenSigSendType" SG_ 1174 APA_MTO_Failure_status 7;
BA_ "GenSigCycleTimeActive" SG_ 1174 APA_MTO_Failure_status 100;
BA_ "GenSigCycleTime" SG_ 1174 APA_MTO_Failure_status 100;
BA_ "GenSigSendType" SG_ 1174 CPL_MTO_Failure_Status 7;
BA_ "GenSigCycleTimeActive" SG_ 1174 CPL_MTO_Failure_Status 100;
BA_ "GenSigCycleTime" SG_ 1174 CPL_MTO_Failure_Status 100;
BA_ "GenSigSendType" SG_ 1174 HUD_MTO_Failure_Status 7;
BA_ "GenSigCycleTimeActive" SG_ 1174 HUD_MTO_Failure_Status 100;
BA_ "GenSigCycleTime" SG_ 1174 HUD_MTO_Failure_Status 100;
BA_ "GenSigSendType" SG_ 1174 GSS_EV_MTO_Failure_Status 7;
BA_ "GenSigCycleTimeActive" SG_ 1174 GSS_EV_MTO_Failure_Status 100;
BA_ "GenSigCycleTime" SG_ 1174 GSS_EV_MTO_Failure_Status 100;
BA_ "GenSigSendType" SG_ 1174 IM_MTO_Failure_Status 7;
BA_ "GenSigCycleTimeActive" SG_ 1174 IM_MTO_Failure_Status 100;
BA_ "GenSigCycleTime" SG_ 1174 IM_MTO_Failure_Status 100;
BA_ "GenSigSendType" SG_ 1174 GSM_MTO_Failure_Status 7;
BA_ "GenSigCycleTimeActive" SG_ 1174 GSM_MTO_Failure_Status 100;
BA_ "GenSigCycleTime" SG_ 1174 GSM_MTO_Failure_Status 100;
BA_ "GenSigSendType" SG_ 1174 SBR_MTO_Failure_Status 7;
BA_ "GenSigCycleTimeActive" SG_ 1174 SBR_MTO_Failure_Status 100;
BA_ "GenSigCycleTime" SG_ 1174 SBR_MTO_Failure_Status 100;
BA_ "GenSigSendType" SG_ 1174 FCM_MRC_Failure_Status 7;
BA_ "GenSigCycleTimeActive" SG_ 1174 FCM_MRC_Failure_Status 100;
BA_ "GenSigCycleTime" SG_ 1174 FCM_MRC_Failure_Status 100;
BA_ "GenSigSendType" SG_ 1174 FCM_Invalid_Failure_Status 7;
BA_ "GenSigCycleTimeActive" SG_ 1174 FCM_Invalid_Failure_Status 100;
BA_ "GenSigCycleTime" SG_ 1174 FCM_Invalid_Failure_Status 100;
BA_ "GenSigSendType" SG_ 1174 FCM_CRC_Failure_Status 7;
BA_ "GenSigCycleTimeActive" SG_ 1174 FCM_CRC_Failure_Status 100;
BA_ "GenSigCycleTime" SG_ 1174 FCM_CRC_Failure_Status 100;
BA_ "GenSigSendType" SG_ 1174 WPC_MTO_Failure_Status 7;
BA_ "GenSigCycleTimeActive" SG_ 1174 WPC_MTO_Failure_Status 100;
BA_ "GenSigCycleTime" SG_ 1174 WPC_MTO_Failure_Status 100;
BA_ "GenSigSendType" SG_ 1174 AVAS_MTO_Failure_status 7;
BA_ "GenSigCycleTimeActive" SG_ 1174 AVAS_MTO_Failure_status 100;
BA_ "GenSigCycleTime" SG_ 1174 AVAS_MTO_Failure_status 100;
BA_ "GenSigSendType" SG_ 1174 ESCL_MTO_Failure_Status 7;
BA_ "GenSigCycleTimeActive" SG_ 1174 ESCL_MTO_Failure_Status 100;
BA_ "GenSigCycleTime" SG_ 1174 ESCL_MTO_Failure_Status 100;
BA_ "GenSigSendType" SG_ 1174 PEPS_Invalid_failure_status 7;
BA_ "GenSigCycleTimeActive" SG_ 1174 PEPS_Invalid_failure_status 100;
BA_ "GenSigCycleTime" SG_ 1174 PEPS_Invalid_failure_status 100;
BA_ "GenSigSendType" SG_ 1174 BCM_Invalid_Status_Failure 7;
BA_ "GenSigCycleTimeActive" SG_ 1174 BCM_Invalid_Status_Failure 100;
BA_ "GenSigCycleTime" SG_ 1174 BCM_Invalid_Status_Failure 100;
BA_ "GenSigTimeoutTime_HU_Mid_X451" SG_ 1274 GlobalRealTimeGS 5000;
BA_ "GenSigTimeoutTime_HU_High_X451" SG_ 1274 GlobalRealTimeGS 5000;
BA_ "GenSigTimeoutTime_HU_B" SG_ 1274 GlobalRealTimeGS 5000;
BA_ "GenSigTimeoutTime_HU_A" SG_ 1274 GlobalRealTimeGS 5000;
BA_ "GenSigTimeoutMsg_HU_Mid_X451" SG_ 1274 GlobalRealTimeGS 5000;
BA_ "GenSigTimeoutMsg_HU_High_X451" SG_ 1274 GlobalRealTimeGS 5000;
BA_ "GenSigTimeoutMsg_HU_B" SG_ 1274 GlobalRealTimeGS 5000;
BA_ "GenSigTimeoutMsg_HU_A" SG_ 1274 GlobalRealTimeGS 5000;
BA_ "GenSigSendType" SG_ 1274 GlobalRealTimeGS 7;
BA_ "GenSigCycleTimeActive" SG_ 1274 GlobalRealTimeGS 1000;
BA_ "GenSigCycleTime" SG_ 1274 GlobalRealTimeGS 1000;
BA_ "GenSigTimeoutMsg_HU_High_X445" SG_ 1274 GlobalRealTimeGS 5000;
BA_ "GenSigTimeoutMsg_HU_Mid_X445" SG_ 1274 GlobalRealTimeGS 5000;
BA_ "GenSigTimeoutTime_HU_High_X445" SG_ 1274 GlobalRealTimeGS 5000;
BA_ "GenSigTimeoutTime_HU_Mid_X445" SG_ 1274 GlobalRealTimeGS 5000;
BA_ "GenSigTimeoutMsg_IVI" SG_ 1274 GlobalRealTimeGS 5000;
BA_ "GenSigTimeoutTime_IVI" SG_ 1274 GlobalRealTimeGS 5000;
BA_ "GenSigTimeoutTime_HU_Mid_X451" SG_ 1274 OdoICFullSigGS 5000;
BA_ "GenSigTimeoutTime_HU_High_X451" SG_ 1274 OdoICFullSigGS 5000;
BA_ "GenSigTimeoutTime_HU_B" SG_ 1274 OdoICFullSigGS 5000;
BA_ "GenSigTimeoutTime_HU_A" SG_ 1274 OdoICFullSigGS 5000;
BA_ "GenSigTimeoutMsg_HU_Mid_X451" SG_ 1274 OdoICFullSigGS 5000;
BA_ "GenSigTimeoutMsg_HU_High_X451" SG_ 1274 OdoICFullSigGS 5000;
BA_ "GenSigTimeoutMsg_HU_B" SG_ 1274 OdoICFullSigGS 5000;
BA_ "GenSigTimeoutMsg_HU_A" SG_ 1274 OdoICFullSigGS 5000;
BA_ "GenSigSendType" SG_ 1274 OdoICFullSigGS 7;
BA_ "GenSigCycleTimeActive" SG_ 1274 OdoICFullSigGS 1000;
BA_ "GenSigCycleTime" SG_ 1274 OdoICFullSigGS 1000;
BA_ "GenSigTimeoutMsg_HU_High_X445" SG_ 1274 OdoICFullSigGS 5000;
BA_ "GenSigTimeoutMsg_HU_Mid_X445" SG_ 1274 OdoICFullSigGS 5000;
BA_ "GenSigTimeoutTime_HU_High_X445" SG_ 1274 OdoICFullSigGS 5000;
BA_ "GenSigTimeoutTime_HU_Mid_X445" SG_ 1274 OdoICFullSigGS 5000;
BA_ "GenSigTimeoutMsg_IVI" SG_ 1274 OdoICFullSigGS 5000;
BA_ "GenSigTimeoutTime_IVI" SG_ 1274 OdoICFullSigGS 5000;
BA_ "GenSigTimeoutTime_HU_Mid_X451" SG_ 1274 BatVoltGS 5000;
BA_ "GenSigTimeoutTime_HU_High_X451" SG_ 1274 BatVoltGS 5000;
BA_ "GenSigTimeoutTime_HU_B" SG_ 1274 BatVoltGS 5000;
BA_ "GenSigTimeoutTime_HU_A" SG_ 1274 BatVoltGS 5000;
BA_ "GenSigTimeoutMsg_HU_Mid_X451" SG_ 1274 BatVoltGS 5000;
BA_ "GenSigTimeoutMsg_HU_High_X451" SG_ 1274 BatVoltGS 5000;
BA_ "GenSigTimeoutMsg_HU_B" SG_ 1274 BatVoltGS 5000;
BA_ "GenSigTimeoutMsg_HU_A" SG_ 1274 BatVoltGS 5000;
BA_ "GenSigSendType" SG_ 1274 BatVoltGS 7;
BA_ "GenSigCycleTimeActive" SG_ 1274 BatVoltGS 1000;
BA_ "GenSigCycleTime" SG_ 1274 BatVoltGS 1000;
BA_ "GenSigTimeoutMsg_HU_High_X445" SG_ 1274 BatVoltGS 5000;
BA_ "GenSigTimeoutMsg_HU_Mid_X445" SG_ 1274 BatVoltGS 5000;
BA_ "GenSigTimeoutTime_HU_High_X445" SG_ 1274 BatVoltGS 5000;
BA_ "GenSigTimeoutTime_HU_Mid_X445" SG_ 1274 BatVoltGS 5000;
BA_ "GenSigTimeoutMsg_IVI" SG_ 1274 BatVoltGS 5000;
BA_ "GenSigTimeoutTime_IVI" SG_ 1274 BatVoltGS 5000;
BA_ "GenSigTimeoutTime_HU_Mid_X451" SG_ 1274 VehicleInteriorTempGS 5000;
BA_ "GenSigTimeoutTime_HU_High_X451" SG_ 1274 VehicleInteriorTempGS 5000;
BA_ "GenSigTimeoutTime_HU_B" SG_ 1274 VehicleInteriorTempGS 5000;
BA_ "GenSigTimeoutTime_HU_A" SG_ 1274 VehicleInteriorTempGS 5000;
BA_ "GenSigTimeoutMsg_HU_Mid_X451" SG_ 1274 VehicleInteriorTempGS 5000;
BA_ "GenSigTimeoutMsg_HU_High_X451" SG_ 1274 VehicleInteriorTempGS 5000;
BA_ "GenSigTimeoutMsg_HU_B" SG_ 1274 VehicleInteriorTempGS 5000;
BA_ "GenSigTimeoutMsg_HU_A" SG_ 1274 VehicleInteriorTempGS 5000;
BA_ "GenSigStartValue" SG_ 1274 VehicleInteriorTempGS 40;
BA_ "GenSigSendType" SG_ 1274 VehicleInteriorTempGS 7;
BA_ "GenSigCycleTimeActive" SG_ 1274 VehicleInteriorTempGS 1000;
BA_ "GenSigCycleTime" SG_ 1274 VehicleInteriorTempGS 1000;
BA_ "GenSigTimeoutMsg_HU_High_X445" SG_ 1274 VehicleInteriorTempGS 5000;
BA_ "GenSigTimeoutMsg_HU_Mid_X445" SG_ 1274 VehicleInteriorTempGS 5000;
BA_ "GenSigTimeoutTime_HU_High_X445" SG_ 1274 VehicleInteriorTempGS 5000;
BA_ "GenSigTimeoutTime_HU_Mid_X445" SG_ 1274 VehicleInteriorTempGS 5000;
BA_ "GenSigTimeoutMsg_IVI" SG_ 1274 VehicleInteriorTempGS 5000;
BA_ "GenSigTimeoutTime_IVI" SG_ 1274 VehicleInteriorTempGS 5000;
BA_ "GenSigTimeoutTime_HU_Mid_X451" SG_ 1276 EngSpdGS 5000;
BA_ "GenSigTimeoutTime_HU_High_X451" SG_ 1276 EngSpdGS 5000;
BA_ "GenSigTimeoutTime_HU_B" SG_ 1276 EngSpdGS 5000;
BA_ "GenSigTimeoutTime_HU_A" SG_ 1276 EngSpdGS 5000;
BA_ "GenSigTimeoutMsg_HU_Mid_X451" SG_ 1276 EngSpdGS 5000;
BA_ "GenSigTimeoutMsg_HU_High_X451" SG_ 1276 EngSpdGS 5000;
BA_ "GenSigTimeoutMsg_HU_B" SG_ 1276 EngSpdGS 5000;
BA_ "GenSigTimeoutMsg_HU_A" SG_ 1276 EngSpdGS 5000;
BA_ "GenSigSendType" SG_ 1276 EngSpdGS 7;
BA_ "GenSigCycleTimeActive" SG_ 1276 EngSpdGS 1000;
BA_ "GenSigCycleTime" SG_ 1276 EngSpdGS 1000;
BA_ "GenSigTimeoutMsg_HU_High_X445" SG_ 1276 EngSpdGS 5000;
BA_ "GenSigTimeoutMsg_HU_Mid_X445" SG_ 1276 EngSpdGS 5000;
BA_ "GenSigTimeoutTime_HU_High_X445" SG_ 1276 EngSpdGS 5000;
BA_ "GenSigTimeoutTime_HU_Mid_X445" SG_ 1276 EngSpdGS 5000;
BA_ "GenSigTimeoutMsg_IVI" SG_ 1276 EngSpdGS 5000;
BA_ "GenSigTimeoutTime_IVI" SG_ 1276 EngSpdGS 5000;
BA_ "GenSigTimeoutTime_HU_Mid_X451" SG_ 1276 AccPedPosnGS 5000;
BA_ "GenSigTimeoutTime_HU_High_X451" SG_ 1276 AccPedPosnGS 5000;
BA_ "GenSigTimeoutTime_HU_B" SG_ 1276 AccPedPosnGS 5000;
BA_ "GenSigTimeoutTime_HU_A" SG_ 1276 AccPedPosnGS 5000;
BA_ "GenSigTimeoutMsg_HU_Mid_X451" SG_ 1276 AccPedPosnGS 5000;
BA_ "GenSigTimeoutMsg_HU_High_X451" SG_ 1276 AccPedPosnGS 5000;
BA_ "GenSigTimeoutMsg_HU_B" SG_ 1276 AccPedPosnGS 5000;
BA_ "GenSigTimeoutMsg_HU_A" SG_ 1276 AccPedPosnGS 5000;
BA_ "GenSigSendType" SG_ 1276 AccPedPosnGS 7;
BA_ "GenSigCycleTimeActive" SG_ 1276 AccPedPosnGS 1000;
BA_ "GenSigCycleTime" SG_ 1276 AccPedPosnGS 1000;
BA_ "GenSigTimeoutMsg_HU_High_X445" SG_ 1276 AccPedPosnGS 5000;
BA_ "GenSigTimeoutMsg_HU_Mid_X445" SG_ 1276 AccPedPosnGS 5000;
BA_ "GenSigTimeoutTime_HU_High_X445" SG_ 1276 AccPedPosnGS 5000;
BA_ "GenSigTimeoutTime_HU_Mid_X445" SG_ 1276 AccPedPosnGS 5000;
BA_ "GenSigTimeoutMsg_IVI" SG_ 1276 AccPedPosnGS 5000;
BA_ "GenSigTimeoutTime_IVI" SG_ 1276 AccPedPosnGS 5000;
BA_ "GenSigTimeoutTime_HU_Mid_X451" SG_ 1276 ClntTempGS 5000;
BA_ "GenSigTimeoutTime_HU_High_X451" SG_ 1276 ClntTempGS 5000;
BA_ "GenSigTimeoutTime_HU_B" SG_ 1276 ClntTempGS 5000;
BA_ "GenSigTimeoutTime_HU_A" SG_ 1276 ClntTempGS 5000;
BA_ "GenSigTimeoutMsg_HU_Mid_X451" SG_ 1276 ClntTempGS 5000;
BA_ "GenSigTimeoutMsg_HU_High_X451" SG_ 1276 ClntTempGS 5000;
BA_ "GenSigTimeoutMsg_HU_B" SG_ 1276 ClntTempGS 5000;
BA_ "GenSigTimeoutMsg_HU_A" SG_ 1276 ClntTempGS 5000;
BA_ "GenSigStartValue" SG_ 1276 ClntTempGS 40;
BA_ "GenSigSendType" SG_ 1276 ClntTempGS 7;
BA_ "GenSigCycleTimeActive" SG_ 1276 ClntTempGS 1000;
BA_ "GenSigCycleTime" SG_ 1276 ClntTempGS 1000;
BA_ "GenSigTimeoutMsg_HU_High_X445" SG_ 1276 ClntTempGS 5000;
BA_ "GenSigTimeoutMsg_HU_Mid_X445" SG_ 1276 ClntTempGS 5000;
BA_ "GenSigTimeoutTime_HU_High_X445" SG_ 1276 ClntTempGS 5000;
BA_ "GenSigTimeoutTime_HU_Mid_X445" SG_ 1276 ClntTempGS 5000;
BA_ "GenSigTimeoutMsg_IVI" SG_ 1276 ClntTempGS 5000;
BA_ "GenSigTimeoutTime_IVI" SG_ 1276 ClntTempGS 5000;
BA_ "GenSigTimeoutTime_HU_Mid_X451" SG_ 1276 VehSpdGS 5000;
BA_ "GenSigTimeoutTime_HU_High_X451" SG_ 1276 VehSpdGS 5000;
BA_ "GenSigTimeoutTime_HU_B" SG_ 1276 VehSpdGS 5000;
BA_ "GenSigTimeoutTime_HU_A" SG_ 1276 VehSpdGS 5000;
BA_ "GenSigTimeoutMsg_HU_Mid_X451" SG_ 1276 VehSpdGS 5000;
BA_ "GenSigTimeoutMsg_HU_High_X451" SG_ 1276 VehSpdGS 5000;
BA_ "GenSigTimeoutMsg_HU_B" SG_ 1276 VehSpdGS 5000;
BA_ "GenSigTimeoutMsg_HU_A" SG_ 1276 VehSpdGS 5000;
BA_ "GenSigSendType" SG_ 1276 VehSpdGS 7;
BA_ "GenSigCycleTimeActive" SG_ 1276 VehSpdGS 1000;
BA_ "GenSigCycleTime" SG_ 1276 VehSpdGS 1000;
BA_ "GenSigTimeoutMsg_HU_High_X445" SG_ 1276 VehSpdGS 5000;
BA_ "GenSigTimeoutMsg_HU_Mid_X445" SG_ 1276 VehSpdGS 5000;
BA_ "GenSigTimeoutTime_HU_High_X445" SG_ 1276 VehSpdGS 5000;
BA_ "GenSigTimeoutTime_HU_Mid_X445" SG_ 1276 VehSpdGS 5000;
BA_ "GenSigTimeoutMsg_IVI" SG_ 1276 VehSpdGS 5000;
BA_ "GenSigTimeoutTime_IVI" SG_ 1276 VehSpdGS 5000;
BA_ "GenSigTimeoutTime_HU_Mid_X451" SG_ 1276 OATICSigGS 5000;
BA_ "GenSigTimeoutTime_HU_High_X451" SG_ 1276 OATICSigGS 5000;
BA_ "GenSigTimeoutTime_HU_B" SG_ 1276 OATICSigGS 5000;
BA_ "GenSigTimeoutTime_HU_A" SG_ 1276 OATICSigGS 5000;
BA_ "GenSigTimeoutMsg_HU_Mid_X451" SG_ 1276 OATICSigGS 5000;
BA_ "GenSigTimeoutMsg_HU_High_X451" SG_ 1276 OATICSigGS 5000;
BA_ "GenSigTimeoutMsg_HU_B" SG_ 1276 OATICSigGS 5000;
BA_ "GenSigTimeoutMsg_HU_A" SG_ 1276 OATICSigGS 5000;
BA_ "GenSigStartValue" SG_ 1276 OATICSigGS 40;
BA_ "GenSigSendType" SG_ 1276 OATICSigGS 7;
BA_ "GenSigCycleTimeActive" SG_ 1276 OATICSigGS 1000;
BA_ "GenSigCycleTime" SG_ 1276 OATICSigGS 1000;
BA_ "GenSigTimeoutMsg_HU_High_X445" SG_ 1276 OATICSigGS 5000;
BA_ "GenSigTimeoutMsg_HU_Mid_X445" SG_ 1276 OATICSigGS 5000;
BA_ "GenSigTimeoutTime_HU_High_X445" SG_ 1276 OATICSigGS 5000;
BA_ "GenSigTimeoutTime_HU_Mid_X445" SG_ 1276 OATICSigGS 5000;
BA_ "GenSigTimeoutMsg_IVI" SG_ 1276 OATICSigGS 5000;
BA_ "GenSigTimeoutTime_IVI" SG_ 1276 OATICSigGS 5000;
BA_ "GenSigTimeoutTime_HU_Mid_X451" SG_ 1276 PowerModeStateGS 5000;
BA_ "GenSigTimeoutTime_HU_High_X451" SG_ 1276 PowerModeStateGS 5000;
BA_ "GenSigTimeoutTime_HU_B" SG_ 1276 PowerModeStateGS 5000;
BA_ "GenSigTimeoutTime_HU_A" SG_ 1276 PowerModeStateGS 5000;
BA_ "GenSigTimeoutMsg_HU_Mid_X451" SG_ 1276 PowerModeStateGS 5000;
BA_ "GenSigTimeoutMsg_HU_High_X451" SG_ 1276 PowerModeStateGS 5000;
BA_ "GenSigTimeoutMsg_HU_B" SG_ 1276 PowerModeStateGS 5000;
BA_ "GenSigTimeoutMsg_HU_A" SG_ 1276 PowerModeStateGS 5000;
BA_ "GenSigSendType" SG_ 1276 PowerModeStateGS 7;
BA_ "GenSigCycleTimeActive" SG_ 1276 PowerModeStateGS 1000;
BA_ "GenSigCycleTime" SG_ 1276 PowerModeStateGS 1000;
BA_ "GenSigTimeoutMsg_HU_High_X445" SG_ 1276 PowerModeStateGS 5000;
BA_ "GenSigTimeoutMsg_HU_Mid_X445" SG_ 1276 PowerModeStateGS 5000;
BA_ "GenSigTimeoutTime_HU_High_X445" SG_ 1276 PowerModeStateGS 5000;
BA_ "GenSigTimeoutTime_HU_Mid_X445" SG_ 1276 PowerModeStateGS 5000;
BA_ "GenSigTimeoutMsg_IVI" SG_ 1276 PowerModeStateGS 5000;
BA_ "GenSigTimeoutTime_IVI" SG_ 1276 PowerModeStateGS 5000;
BA_ "GenSigTimeoutTime_HU_Mid_X451" SG_ 1276 ParkBrkStateGS 5000;
BA_ "GenSigTimeoutTime_HU_High_X451" SG_ 1276 ParkBrkStateGS 5000;
BA_ "GenSigTimeoutTime_HU_B" SG_ 1276 ParkBrkStateGS 5000;
BA_ "GenSigTimeoutTime_HU_A" SG_ 1276 ParkBrkStateGS 5000;
BA_ "GenSigTimeoutMsg_HU_Mid_X451" SG_ 1276 ParkBrkStateGS 5000;
BA_ "GenSigTimeoutMsg_HU_High_X451" SG_ 1276 ParkBrkStateGS 5000;
BA_ "GenSigTimeoutMsg_HU_B" SG_ 1276 ParkBrkStateGS 5000;
BA_ "GenSigTimeoutMsg_HU_A" SG_ 1276 ParkBrkStateGS 5000;
BA_ "GenSigSendType" SG_ 1276 ParkBrkStateGS 7;
BA_ "GenSigCycleTimeActive" SG_ 1276 ParkBrkStateGS 1000;
BA_ "GenSigCycleTime" SG_ 1276 ParkBrkStateGS 1000;
BA_ "GenSigTimeoutMsg_HU_High_X445" SG_ 1276 ParkBrkStateGS 5000;
BA_ "GenSigTimeoutMsg_HU_Mid_X445" SG_ 1276 ParkBrkStateGS 5000;
BA_ "GenSigTimeoutTime_HU_High_X445" SG_ 1276 ParkBrkStateGS 5000;
BA_ "GenSigTimeoutTime_HU_Mid_X445" SG_ 1276 ParkBrkStateGS 5000;
BA_ "GenSigTimeoutMsg_IVI" SG_ 1276 ParkBrkStateGS 5000;
BA_ "GenSigTimeoutTime_IVI" SG_ 1276 ParkBrkStateGS 5000;
BA_ "GenSigTimeoutTime_HU_Mid_X451" SG_ 1278 VehIdetNumGS 5000;
BA_ "GenSigTimeoutTime_HU_High_X451" SG_ 1278 VehIdetNumGS 5000;
BA_ "GenSigTimeoutTime_HU_B" SG_ 1278 VehIdetNumGS 5000;
BA_ "GenSigTimeoutTime_HU_A" SG_ 1278 VehIdetNumGS 5000;
BA_ "GenSigTimeoutMsg_HU_Mid_X451" SG_ 1278 VehIdetNumGS 5000;
BA_ "GenSigTimeoutMsg_HU_High_X451" SG_ 1278 VehIdetNumGS 5000;
BA_ "GenSigTimeoutMsg_HU_B" SG_ 1278 VehIdetNumGS 5000;
BA_ "GenSigTimeoutMsg_HU_A" SG_ 1278 VehIdetNumGS 5000;
BA_ "GenSigSendType" SG_ 1278 VehIdetNumGS 7;
BA_ "GenSigCycleTimeActive" SG_ 1278 VehIdetNumGS 1000;
BA_ "GenSigCycleTime" SG_ 1278 VehIdetNumGS 1000;
BA_ "GenSigTimeoutMsg_HU_High_X445" SG_ 1278 VehIdetNumGS 5000;
BA_ "GenSigTimeoutMsg_HU_Mid_X445" SG_ 1278 VehIdetNumGS 5000;
BA_ "GenSigTimeoutTime_HU_High_X445" SG_ 1278 VehIdetNumGS 5000;
BA_ "GenSigTimeoutTime_HU_Mid_X445" SG_ 1278 VehIdetNumGS 5000;
BA_ "GenSigTimeoutMsg_IVI" SG_ 1278 VehIdetNumGS 5000;
BA_ "GenSigTimeoutTime_IVI" SG_ 1278 VehIdetNumGS 5000;
BA_ "GenSigTimeoutTime_HU_Mid_X451" SG_ 1280 BCM_NMPDU_SRC_ECU_ID 1000;
BA_ "GenSigTimeoutTime_HU_High_X451" SG_ 1280 BCM_NMPDU_SRC_ECU_ID 1000;
BA_ "GenSigTimeoutTime_HU_B" SG_ 1280 BCM_NMPDU_SRC_ECU_ID 1000;
BA_ "GenSigTimeoutTime_HU_A" SG_ 1280 BCM_NMPDU_SRC_ECU_ID 1000;
BA_ "GenSigTimeoutMsg_HU_Mid_X451" SG_ 1280 BCM_NMPDU_SRC_ECU_ID 1000;
BA_ "GenSigTimeoutMsg_HU_High_X451" SG_ 1280 BCM_NMPDU_SRC_ECU_ID 1000;
BA_ "GenSigTimeoutMsg_HU_B" SG_ 1280 BCM_NMPDU_SRC_ECU_ID 1000;
BA_ "GenSigTimeoutMsg_HU_A" SG_ 1280 BCM_NMPDU_SRC_ECU_ID 1000;
BA_ "GenSigSendType" SG_ 1280 BCM_NMPDU_SRC_ECU_ID 7;
BA_ "GenSigCycleTimeActive" SG_ 1280 BCM_NMPDU_SRC_ECU_ID 200;
BA_ "GenSigCycleTime" SG_ 1280 BCM_NMPDU_SRC_ECU_ID 200;
BA_ "GenSigTimeoutMsg_HU_High_X445" SG_ 1280 BCM_NMPDU_SRC_ECU_ID 1000;
BA_ "GenSigTimeoutMsg_HU_Mid_X445" SG_ 1280 BCM_NMPDU_SRC_ECU_ID 1000;
BA_ "GenSigTimeoutTime_HU_High_X445" SG_ 1280 BCM_NMPDU_SRC_ECU_ID 1000;
BA_ "GenSigTimeoutTime_HU_Mid_X445" SG_ 1280 BCM_NMPDU_SRC_ECU_ID 1000;
BA_ "GenSigTimeoutMsg_IVI" SG_ 1280 BCM_NMPDU_SRC_ECU_ID 1000;
BA_ "GenSigTimeoutTime_IVI" SG_ 1280 BCM_NMPDU_SRC_ECU_ID 1000;
BA_ "GenSigTimeoutTime_HU_Mid_X451" SG_ 1280 RepeatMessageReq_BCM 1000;
BA_ "GenSigTimeoutTime_HU_High_X451" SG_ 1280 RepeatMessageReq_BCM 1000;
BA_ "GenSigTimeoutTime_HU_B" SG_ 1280 RepeatMessageReq_BCM 1000;
BA_ "GenSigTimeoutTime_HU_A" SG_ 1280 RepeatMessageReq_BCM 1000;
BA_ "GenSigTimeoutMsg_HU_Mid_X451" SG_ 1280 RepeatMessageReq_BCM 1000;
BA_ "GenSigTimeoutMsg_HU_High_X451" SG_ 1280 RepeatMessageReq_BCM 1000;
BA_ "GenSigTimeoutMsg_HU_B" SG_ 1280 RepeatMessageReq_BCM 1000;
BA_ "GenSigTimeoutMsg_HU_A" SG_ 1280 RepeatMessageReq_BCM 1000;
BA_ "GenSigSendType" SG_ 1280 RepeatMessageReq_BCM 7;
BA_ "GenSigCycleTimeActive" SG_ 1280 RepeatMessageReq_BCM 200;
BA_ "GenSigCycleTime" SG_ 1280 RepeatMessageReq_BCM 200;
BA_ "GenSigTimeoutMsg_HU_High_X445" SG_ 1280 RepeatMessageReq_BCM 1000;
BA_ "GenSigTimeoutMsg_HU_Mid_X445" SG_ 1280 RepeatMessageReq_BCM 1000;
BA_ "GenSigTimeoutTime_HU_High_X445" SG_ 1280 RepeatMessageReq_BCM 1000;
BA_ "GenSigTimeoutTime_HU_Mid_X445" SG_ 1280 RepeatMessageReq_BCM 1000;
BA_ "GenSigTimeoutMsg_IVI" SG_ 1280 RepeatMessageReq_BCM 1000;
BA_ "GenSigTimeoutTime_IVI" SG_ 1280 RepeatMessageReq_BCM 1000;
BA_ "GenSigTimeoutTime_HU_Mid_X451" SG_ 1280 Reserved0 1000;
BA_ "GenSigTimeoutTime_HU_High_X451" SG_ 1280 Reserved0 1000;
BA_ "GenSigTimeoutTime_HU_B" SG_ 1280 Reserved0 1000;
BA_ "GenSigTimeoutTime_HU_A" SG_ 1280 Reserved0 1000;
BA_ "GenSigTimeoutMsg_HU_Mid_X451" SG_ 1280 Reserved0 1000;
BA_ "GenSigTimeoutMsg_HU_High_X451" SG_ 1280 Reserved0 1000;
BA_ "GenSigTimeoutMsg_HU_B" SG_ 1280 Reserved0 1000;
BA_ "GenSigTimeoutMsg_HU_A" SG_ 1280 Reserved0 1000;
BA_ "GenSigSendType" SG_ 1280 Reserved0 7;
BA_ "GenSigCycleTimeActive" SG_ 1280 Reserved0 200;
BA_ "GenSigCycleTime" SG_ 1280 Reserved0 200;
BA_ "GenSigTimeoutMsg_HU_High_X445" SG_ 1280 Reserved0 1000;
BA_ "GenSigTimeoutMsg_HU_Mid_X445" SG_ 1280 Reserved0 1000;
BA_ "GenSigTimeoutTime_HU_High_X445" SG_ 1280 Reserved0 1000;
BA_ "GenSigTimeoutTime_HU_Mid_X445" SG_ 1280 Reserved0 1000;
BA_ "GenSigTimeoutMsg_IVI" SG_ 1280 Reserved0 1000;
BA_ "GenSigTimeoutTime_IVI" SG_ 1280 Reserved0 1000;
BA_ "GenSigTimeoutTime_HU_Mid_X451" SG_ 1280 Reserved1 1000;
BA_ "GenSigTimeoutTime_HU_High_X451" SG_ 1280 Reserved1 1000;
BA_ "GenSigTimeoutTime_HU_B" SG_ 1280 Reserved1 1000;
BA_ "GenSigTimeoutTime_HU_A" SG_ 1280 Reserved1 1000;
BA_ "GenSigTimeoutMsg_HU_Mid_X451" SG_ 1280 Reserved1 1000;
BA_ "GenSigTimeoutMsg_HU_High_X451" SG_ 1280 Reserved1 1000;
BA_ "GenSigTimeoutMsg_HU_B" SG_ 1280 Reserved1 1000;
BA_ "GenSigTimeoutMsg_HU_A" SG_ 1280 Reserved1 1000;
BA_ "GenSigSendType" SG_ 1280 Reserved1 7;
BA_ "GenSigCycleTimeActive" SG_ 1280 Reserved1 200;
BA_ "GenSigCycleTime" SG_ 1280 Reserved1 200;
BA_ "GenSigTimeoutMsg_HU_High_X445" SG_ 1280 Reserved1 1000;
BA_ "GenSigTimeoutMsg_HU_Mid_X445" SG_ 1280 Reserved1 1000;
BA_ "GenSigTimeoutTime_HU_High_X445" SG_ 1280 Reserved1 1000;
BA_ "GenSigTimeoutTime_HU_Mid_X445" SG_ 1280 Reserved1 1000;
BA_ "GenSigTimeoutMsg_IVI" SG_ 1280 Reserved1 1000;
BA_ "GenSigTimeoutTime_IVI" SG_ 1280 Reserved1 1000;
BA_ "GenSigTimeoutTime_HU_Mid_X451" SG_ 1280 NMCoOrdSlpReady_BCM 1000;
BA_ "GenSigTimeoutTime_HU_High_X451" SG_ 1280 NMCoOrdSlpReady_BCM 1000;
BA_ "GenSigTimeoutTime_HU_B" SG_ 1280 NMCoOrdSlpReady_BCM 1000;
BA_ "GenSigTimeoutTime_HU_A" SG_ 1280 NMCoOrdSlpReady_BCM 1000;
BA_ "GenSigTimeoutMsg_HU_Mid_X451" SG_ 1280 NMCoOrdSlpReady_BCM 1000;
BA_ "GenSigTimeoutMsg_HU_High_X451" SG_ 1280 NMCoOrdSlpReady_BCM 1000;
BA_ "GenSigTimeoutMsg_HU_B" SG_ 1280 NMCoOrdSlpReady_BCM 1000;
BA_ "GenSigTimeoutMsg_HU_A" SG_ 1280 NMCoOrdSlpReady_BCM 1000;
BA_ "GenSigSendType" SG_ 1280 NMCoOrdSlpReady_BCM 7;
BA_ "GenSigCycleTimeActive" SG_ 1280 NMCoOrdSlpReady_BCM 200;
BA_ "GenSigCycleTime" SG_ 1280 NMCoOrdSlpReady_BCM 200;
BA_ "GenSigTimeoutMsg_HU_High_X445" SG_ 1280 NMCoOrdSlpReady_BCM 1000;
BA_ "GenSigTimeoutMsg_HU_Mid_X445" SG_ 1280 NMCoOrdSlpReady_BCM 1000;
BA_ "GenSigTimeoutTime_HU_High_X445" SG_ 1280 NMCoOrdSlpReady_BCM 1000;
BA_ "GenSigTimeoutTime_HU_Mid_X445" SG_ 1280 NMCoOrdSlpReady_BCM 1000;
BA_ "GenSigTimeoutMsg_IVI" SG_ 1280 NMCoOrdSlpReady_BCM 1000;
BA_ "GenSigTimeoutTime_IVI" SG_ 1280 NMCoOrdSlpReady_BCM 1000;
BA_ "GenSigTimeoutTime_HU_Mid_X451" SG_ 1280 ActiveWakeUp_BCM 1000;
BA_ "GenSigTimeoutTime_HU_High_X451" SG_ 1280 ActiveWakeUp_BCM 1000;
BA_ "GenSigTimeoutTime_HU_B" SG_ 1280 ActiveWakeUp_BCM 1000;
BA_ "GenSigTimeoutTime_HU_A" SG_ 1280 ActiveWakeUp_BCM 1000;
BA_ "GenSigTimeoutMsg_HU_Mid_X451" SG_ 1280 ActiveWakeUp_BCM 1000;
BA_ "GenSigTimeoutMsg_HU_High_X451" SG_ 1280 ActiveWakeUp_BCM 1000;
BA_ "GenSigTimeoutMsg_HU_B" SG_ 1280 ActiveWakeUp_BCM 1000;
BA_ "GenSigTimeoutMsg_HU_A" SG_ 1280 ActiveWakeUp_BCM 1000;
BA_ "GenSigSendType" SG_ 1280 ActiveWakeUp_BCM 7;
BA_ "GenSigCycleTimeActive" SG_ 1280 ActiveWakeUp_BCM 200;
BA_ "GenSigCycleTime" SG_ 1280 ActiveWakeUp_BCM 200;
BA_ "GenSigTimeoutMsg_HU_High_X445" SG_ 1280 ActiveWakeUp_BCM 1000;
BA_ "GenSigTimeoutMsg_HU_Mid_X445" SG_ 1280 ActiveWakeUp_BCM 1000;
BA_ "GenSigTimeoutTime_HU_High_X445" SG_ 1280 ActiveWakeUp_BCM 1000;
BA_ "GenSigTimeoutTime_HU_Mid_X445" SG_ 1280 ActiveWakeUp_BCM 1000;
BA_ "GenSigTimeoutMsg_IVI" SG_ 1280 ActiveWakeUp_BCM 1000;
BA_ "GenSigTimeoutTime_IVI" SG_ 1280 ActiveWakeUp_BCM 1000;
BA_ "GenSigTimeoutTime_HU_Mid_X451" SG_ 1280 Reserved2 1000;
BA_ "GenSigTimeoutTime_HU_High_X451" SG_ 1280 Reserved2 1000;
BA_ "GenSigTimeoutTime_HU_B" SG_ 1280 Reserved2 1000;
BA_ "GenSigTimeoutTime_HU_A" SG_ 1280 Reserved2 1000;
BA_ "GenSigTimeoutMsg_HU_Mid_X451" SG_ 1280 Reserved2 1000;
BA_ "GenSigTimeoutMsg_HU_High_X451" SG_ 1280 Reserved2 1000;
BA_ "GenSigTimeoutMsg_HU_B" SG_ 1280 Reserved2 1000;
BA_ "GenSigTimeoutMsg_HU_A" SG_ 1280 Reserved2 1000;
BA_ "GenSigSendType" SG_ 1280 Reserved2 7;
BA_ "GenSigCycleTimeActive" SG_ 1280 Reserved2 200;
BA_ "GenSigCycleTime" SG_ 1280 Reserved2 200;
BA_ "GenSigTimeoutMsg_HU_High_X445" SG_ 1280 Reserved2 1000;
BA_ "GenSigTimeoutMsg_HU_Mid_X445" SG_ 1280 Reserved2 1000;
BA_ "GenSigTimeoutTime_HU_High_X445" SG_ 1280 Reserved2 1000;
BA_ "GenSigTimeoutTime_HU_Mid_X445" SG_ 1280 Reserved2 1000;
BA_ "GenSigTimeoutMsg_IVI" SG_ 1280 Reserved2 1000;
BA_ "GenSigTimeoutTime_IVI" SG_ 1280 Reserved2 1000;
BA_ "GenSigTimeoutTime_HU_Mid_X451" SG_ 1280 PartialNetworkInformation_BCM 1000;
BA_ "GenSigTimeoutTime_HU_High_X451" SG_ 1280 PartialNetworkInformation_BCM 1000;
BA_ "GenSigTimeoutTime_HU_B" SG_ 1280 PartialNetworkInformation_BCM 1000;
BA_ "GenSigTimeoutTime_HU_A" SG_ 1280 PartialNetworkInformation_BCM 1000;
BA_ "GenSigTimeoutMsg_HU_Mid_X451" SG_ 1280 PartialNetworkInformation_BCM 1000;
BA_ "GenSigTimeoutMsg_HU_High_X451" SG_ 1280 PartialNetworkInformation_BCM 1000;
BA_ "GenSigTimeoutMsg_HU_B" SG_ 1280 PartialNetworkInformation_BCM 1000;
BA_ "GenSigTimeoutMsg_HU_A" SG_ 1280 PartialNetworkInformation_BCM 1000;
BA_ "GenSigSendType" SG_ 1280 PartialNetworkInformation_BCM 7;
BA_ "GenSigCycleTimeActive" SG_ 1280 PartialNetworkInformation_BCM 200;
BA_ "GenSigCycleTime" SG_ 1280 PartialNetworkInformation_BCM 200;
BA_ "GenSigTimeoutMsg_HU_High_X445" SG_ 1280 PartialNetworkInformation_BCM 1000;
BA_ "GenSigTimeoutMsg_HU_Mid_X445" SG_ 1280 PartialNetworkInformation_BCM 1000;
BA_ "GenSigTimeoutTime_HU_High_X445" SG_ 1280 PartialNetworkInformation_BCM 1000;
BA_ "GenSigTimeoutTime_HU_Mid_X445" SG_ 1280 PartialNetworkInformation_BCM 1000;
BA_ "GenSigTimeoutMsg_IVI" SG_ 1280 PartialNetworkInformation_BCM 1000;
BA_ "GenSigTimeoutTime_IVI" SG_ 1280 PartialNetworkInformation_BCM 1000;
BA_ "GenSigTimeoutTime_HU_Mid_X451" SG_ 1280 Reserved3 1000;
BA_ "GenSigTimeoutTime_HU_High_X451" SG_ 1280 Reserved3 1000;
BA_ "GenSigTimeoutTime_HU_B" SG_ 1280 Reserved3 1000;
BA_ "GenSigTimeoutTime_HU_A" SG_ 1280 Reserved3 1000;
BA_ "GenSigTimeoutMsg_HU_Mid_X451" SG_ 1280 Reserved3 1000;
BA_ "GenSigTimeoutMsg_HU_High_X451" SG_ 1280 Reserved3 1000;
BA_ "GenSigTimeoutMsg_HU_B" SG_ 1280 Reserved3 1000;
BA_ "GenSigTimeoutMsg_HU_A" SG_ 1280 Reserved3 1000;
BA_ "GenSigSendType" SG_ 1280 Reserved3 7;
BA_ "GenSigCycleTimeActive" SG_ 1280 Reserved3 200;
BA_ "GenSigCycleTime" SG_ 1280 Reserved3 200;
BA_ "GenSigTimeoutMsg_HU_High_X445" SG_ 1280 Reserved3 1000;
BA_ "GenSigTimeoutMsg_HU_Mid_X445" SG_ 1280 Reserved3 1000;
BA_ "GenSigTimeoutTime_HU_High_X445" SG_ 1280 Reserved3 1000;
BA_ "GenSigTimeoutTime_HU_Mid_X445" SG_ 1280 Reserved3 1000;
BA_ "GenSigTimeoutMsg_IVI" SG_ 1280 Reserved3 1000;
BA_ "GenSigTimeoutTime_IVI" SG_ 1280 Reserved3 1000;
BA_ "GenSigTimeoutTime_HU_Mid_X451" SG_ 1280 CurrentState_BCM 1000;
BA_ "GenSigTimeoutTime_HU_High_X451" SG_ 1280 CurrentState_BCM 1000;
BA_ "GenSigTimeoutTime_HU_B" SG_ 1280 CurrentState_BCM 1000;
BA_ "GenSigTimeoutTime_HU_A" SG_ 1280 CurrentState_BCM 1000;
BA_ "GenSigTimeoutMsg_HU_Mid_X451" SG_ 1280 CurrentState_BCM 1000;
BA_ "GenSigTimeoutMsg_HU_High_X451" SG_ 1280 CurrentState_BCM 1000;
BA_ "GenSigTimeoutMsg_HU_B" SG_ 1280 CurrentState_BCM 1000;
BA_ "GenSigTimeoutMsg_HU_A" SG_ 1280 CurrentState_BCM 1000;
BA_ "GenSigSendType" SG_ 1280 CurrentState_BCM 7;
BA_ "GenSigCycleTimeActive" SG_ 1280 CurrentState_BCM 200;
BA_ "GenSigCycleTime" SG_ 1280 CurrentState_BCM 200;
BA_ "GenSigTimeoutMsg_HU_High_X445" SG_ 1280 CurrentState_BCM 1000;
BA_ "GenSigTimeoutMsg_HU_Mid_X445" SG_ 1280 CurrentState_BCM 1000;
BA_ "GenSigTimeoutTime_HU_High_X445" SG_ 1280 CurrentState_BCM 1000;
BA_ "GenSigTimeoutTime_HU_Mid_X445" SG_ 1280 CurrentState_BCM 1000;
BA_ "GenSigTimeoutMsg_IVI" SG_ 1280 CurrentState_BCM 1000;
BA_ "GenSigTimeoutTime_IVI" SG_ 1280 CurrentState_BCM 1000;
BA_ "GenSigTimeoutTime_HU_Mid_X451" SG_ 1280 PreviousState_BCM 1000;
BA_ "GenSigTimeoutTime_HU_High_X451" SG_ 1280 PreviousState_BCM 1000;
BA_ "GenSigTimeoutTime_HU_B" SG_ 1280 PreviousState_BCM 1000;
BA_ "GenSigTimeoutTime_HU_A" SG_ 1280 PreviousState_BCM 1000;
BA_ "GenSigTimeoutMsg_HU_Mid_X451" SG_ 1280 PreviousState_BCM 1000;
BA_ "GenSigTimeoutMsg_HU_High_X451" SG_ 1280 PreviousState_BCM 1000;
BA_ "GenSigTimeoutMsg_HU_B" SG_ 1280 PreviousState_BCM 1000;
BA_ "GenSigTimeoutMsg_HU_A" SG_ 1280 PreviousState_BCM 1000;
BA_ "GenSigSendType" SG_ 1280 PreviousState_BCM 7;
BA_ "GenSigCycleTimeActive" SG_ 1280 PreviousState_BCM 200;
BA_ "GenSigCycleTime" SG_ 1280 PreviousState_BCM 200;
BA_ "GenSigTimeoutMsg_HU_High_X445" SG_ 1280 PreviousState_BCM 1000;
BA_ "GenSigTimeoutMsg_HU_Mid_X445" SG_ 1280 PreviousState_BCM 1000;
BA_ "GenSigTimeoutTime_HU_High_X445" SG_ 1280 PreviousState_BCM 1000;
BA_ "GenSigTimeoutTime_HU_Mid_X445" SG_ 1280 PreviousState_BCM 1000;
BA_ "GenSigTimeoutMsg_IVI" SG_ 1280 PreviousState_BCM 1000;
BA_ "GenSigTimeoutTime_IVI" SG_ 1280 PreviousState_BCM 1000;
BA_ "GenSigTimeoutTime_HU_Mid_X451" SG_ 1280 Reserved4 1000;
BA_ "GenSigTimeoutTime_HU_High_X451" SG_ 1280 Reserved4 1000;
BA_ "GenSigTimeoutTime_HU_B" SG_ 1280 Reserved4 1000;
BA_ "GenSigTimeoutTime_HU_A" SG_ 1280 Reserved4 1000;
BA_ "GenSigTimeoutMsg_HU_Mid_X451" SG_ 1280 Reserved4 1000;
BA_ "GenSigTimeoutMsg_HU_High_X451" SG_ 1280 Reserved4 1000;
BA_ "GenSigTimeoutMsg_HU_B" SG_ 1280 Reserved4 1000;
BA_ "GenSigTimeoutMsg_HU_A" SG_ 1280 Reserved4 1000;
BA_ "GenSigSendType" SG_ 1280 Reserved4 7;
BA_ "GenSigCycleTimeActive" SG_ 1280 Reserved4 200;
BA_ "GenSigCycleTime" SG_ 1280 Reserved4 200;
BA_ "GenSigTimeoutMsg_HU_High_X445" SG_ 1280 Reserved4 1000;
BA_ "GenSigTimeoutMsg_HU_Mid_X445" SG_ 1280 Reserved4 1000;
BA_ "GenSigTimeoutTime_HU_High_X445" SG_ 1280 Reserved4 1000;
BA_ "GenSigTimeoutTime_HU_Mid_X445" SG_ 1280 Reserved4 1000;
BA_ "GenSigTimeoutMsg_IVI" SG_ 1280 Reserved4 1000;
BA_ "GenSigTimeoutTime_IVI" SG_ 1280 Reserved4 1000;
BA_ "GenSigTimeoutTime_HU_Mid_X451" SG_ 1280 Reserved5 1000;
BA_ "GenSigTimeoutTime_HU_High_X451" SG_ 1280 Reserved5 1000;
BA_ "GenSigTimeoutTime_HU_B" SG_ 1280 Reserved5 1000;
BA_ "GenSigTimeoutTime_HU_A" SG_ 1280 Reserved5 1000;
BA_ "GenSigTimeoutMsg_HU_Mid_X451" SG_ 1280 Reserved5 1000;
BA_ "GenSigTimeoutMsg_HU_High_X451" SG_ 1280 Reserved5 1000;
BA_ "GenSigTimeoutMsg_HU_B" SG_ 1280 Reserved5 1000;
BA_ "GenSigTimeoutMsg_HU_A" SG_ 1280 Reserved5 1000;
BA_ "GenSigSendType" SG_ 1280 Reserved5 7;
BA_ "GenSigCycleTimeActive" SG_ 1280 Reserved5 200;
BA_ "GenSigCycleTime" SG_ 1280 Reserved5 200;
BA_ "GenSigTimeoutMsg_HU_High_X445" SG_ 1280 Reserved5 1000;
BA_ "GenSigTimeoutMsg_HU_Mid_X445" SG_ 1280 Reserved5 1000;
BA_ "GenSigTimeoutTime_HU_High_X445" SG_ 1280 Reserved5 1000;
BA_ "GenSigTimeoutTime_HU_Mid_X445" SG_ 1280 Reserved5 1000;
BA_ "GenSigTimeoutMsg_IVI" SG_ 1280 Reserved5 1000;
BA_ "GenSigTimeoutTime_IVI" SG_ 1280 Reserved5 1000;
BA_ "GenSigTimeoutTime_HU_Mid_X451" SG_ 1280 Reserved6 1000;
BA_ "GenSigTimeoutTime_HU_High_X451" SG_ 1280 Reserved6 1000;
BA_ "GenSigTimeoutTime_HU_B" SG_ 1280 Reserved6 1000;
BA_ "GenSigTimeoutTime_HU_A" SG_ 1280 Reserved6 1000;
BA_ "GenSigTimeoutMsg_HU_Mid_X451" SG_ 1280 Reserved6 1000;
BA_ "GenSigTimeoutMsg_HU_High_X451" SG_ 1280 Reserved6 1000;
BA_ "GenSigTimeoutMsg_HU_B" SG_ 1280 Reserved6 1000;
BA_ "GenSigTimeoutMsg_HU_A" SG_ 1280 Reserved6 1000;
BA_ "GenSigSendType" SG_ 1280 Reserved6 7;
BA_ "GenSigCycleTimeActive" SG_ 1280 Reserved6 200;
BA_ "GenSigCycleTime" SG_ 1280 Reserved6 200;
BA_ "GenSigTimeoutMsg_HU_High_X445" SG_ 1280 Reserved6 1000;
BA_ "GenSigTimeoutMsg_HU_Mid_X445" SG_ 1280 Reserved6 1000;
BA_ "GenSigTimeoutTime_HU_High_X445" SG_ 1280 Reserved6 1000;
BA_ "GenSigTimeoutTime_HU_Mid_X445" SG_ 1280 Reserved6 1000;
BA_ "GenSigTimeoutMsg_IVI" SG_ 1280 Reserved6 1000;
BA_ "GenSigTimeoutTime_IVI" SG_ 1280 Reserved6 1000;
BA_ "GenSigTimeoutTime_HU_Mid_X451" SG_ 1280 Reserved7 1000;
BA_ "GenSigTimeoutTime_HU_High_X451" SG_ 1280 Reserved7 1000;
BA_ "GenSigTimeoutTime_HU_B" SG_ 1280 Reserved7 1000;
BA_ "GenSigTimeoutTime_HU_A" SG_ 1280 Reserved7 1000;
BA_ "GenSigTimeoutMsg_HU_Mid_X451" SG_ 1280 Reserved7 1000;
BA_ "GenSigTimeoutMsg_HU_High_X451" SG_ 1280 Reserved7 1000;
BA_ "GenSigTimeoutMsg_HU_B" SG_ 1280 Reserved7 1000;
BA_ "GenSigTimeoutMsg_HU_A" SG_ 1280 Reserved7 1000;
BA_ "GenSigSendType" SG_ 1280 Reserved7 7;
BA_ "GenSigCycleTimeActive" SG_ 1280 Reserved7 200;
BA_ "GenSigCycleTime" SG_ 1280 Reserved7 200;
BA_ "GenSigTimeoutMsg_HU_High_X445" SG_ 1280 Reserved7 1000;
BA_ "GenSigTimeoutMsg_HU_Mid_X445" SG_ 1280 Reserved7 1000;
BA_ "GenSigTimeoutTime_HU_High_X445" SG_ 1280 Reserved7 1000;
BA_ "GenSigTimeoutTime_HU_Mid_X445" SG_ 1280 Reserved7 1000;
BA_ "GenSigTimeoutMsg_IVI" SG_ 1280 Reserved7 1000;
BA_ "GenSigTimeoutTime_IVI" SG_ 1280 Reserved7 1000;
BA_ "GenSigTimeoutTime_HU_Mid_X451" SG_ 1280 BCM_NMPDU_USER_DATA_D1 1000;
BA_ "GenSigTimeoutTime_HU_High_X451" SG_ 1280 BCM_NMPDU_USER_DATA_D1 1000;
BA_ "GenSigTimeoutTime_HU_B" SG_ 1280 BCM_NMPDU_USER_DATA_D1 1000;
BA_ "GenSigTimeoutTime_HU_A" SG_ 1280 BCM_NMPDU_USER_DATA_D1 1000;
BA_ "GenSigTimeoutMsg_HU_Mid_X451" SG_ 1280 BCM_NMPDU_USER_DATA_D1 1000;
BA_ "GenSigTimeoutMsg_HU_High_X451" SG_ 1280 BCM_NMPDU_USER_DATA_D1 1000;
BA_ "GenSigTimeoutMsg_HU_B" SG_ 1280 BCM_NMPDU_USER_DATA_D1 1000;
BA_ "GenSigTimeoutMsg_HU_A" SG_ 1280 BCM_NMPDU_USER_DATA_D1 1000;
BA_ "GenSigSendType" SG_ 1280 BCM_NMPDU_USER_DATA_D1 7;
BA_ "GenSigCycleTimeActive" SG_ 1280 BCM_NMPDU_USER_DATA_D1 200;
BA_ "GenSigCycleTime" SG_ 1280 BCM_NMPDU_USER_DATA_D1 200;
BA_ "GenSigTimeoutMsg_HU_High_X445" SG_ 1280 BCM_NMPDU_USER_DATA_D1 1000;
BA_ "GenSigTimeoutMsg_HU_Mid_X445" SG_ 1280 BCM_NMPDU_USER_DATA_D1 1000;
BA_ "GenSigTimeoutTime_HU_High_X445" SG_ 1280 BCM_NMPDU_USER_DATA_D1 1000;
BA_ "GenSigTimeoutTime_HU_Mid_X445" SG_ 1280 BCM_NMPDU_USER_DATA_D1 1000;
BA_ "GenSigTimeoutMsg_IVI" SG_ 1280 BCM_NMPDU_USER_DATA_D1 1000;
BA_ "GenSigTimeoutTime_IVI" SG_ 1280 BCM_NMPDU_USER_DATA_D1 1000;
BA_ "GenSigTimeoutTime_HU_Mid_X451" SG_ 1280 BCM_NMPDU_USER_DATA_D2 1000;
BA_ "GenSigTimeoutTime_HU_High_X451" SG_ 1280 BCM_NMPDU_USER_DATA_D2 1000;
BA_ "GenSigTimeoutTime_HU_B" SG_ 1280 BCM_NMPDU_USER_DATA_D2 1000;
BA_ "GenSigTimeoutTime_HU_A" SG_ 1280 BCM_NMPDU_USER_DATA_D2 1000;
BA_ "GenSigTimeoutMsg_HU_Mid_X451" SG_ 1280 BCM_NMPDU_USER_DATA_D2 1000;
BA_ "GenSigTimeoutMsg_HU_High_X451" SG_ 1280 BCM_NMPDU_USER_DATA_D2 1000;
BA_ "GenSigTimeoutMsg_HU_B" SG_ 1280 BCM_NMPDU_USER_DATA_D2 1000;
BA_ "GenSigTimeoutMsg_HU_A" SG_ 1280 BCM_NMPDU_USER_DATA_D2 1000;
BA_ "GenSigSendType" SG_ 1280 BCM_NMPDU_USER_DATA_D2 7;
BA_ "GenSigCycleTimeActive" SG_ 1280 BCM_NMPDU_USER_DATA_D2 200;
BA_ "GenSigCycleTime" SG_ 1280 BCM_NMPDU_USER_DATA_D2 200;
BA_ "GenSigTimeoutMsg_HU_High_X445" SG_ 1280 BCM_NMPDU_USER_DATA_D2 1000;
BA_ "GenSigTimeoutMsg_HU_Mid_X445" SG_ 1280 BCM_NMPDU_USER_DATA_D2 1000;
BA_ "GenSigTimeoutTime_HU_High_X445" SG_ 1280 BCM_NMPDU_USER_DATA_D2 1000;
BA_ "GenSigTimeoutTime_HU_Mid_X445" SG_ 1280 BCM_NMPDU_USER_DATA_D2 1000;
BA_ "GenSigTimeoutMsg_IVI" SG_ 1280 BCM_NMPDU_USER_DATA_D2 1000;
BA_ "GenSigTimeoutTime_IVI" SG_ 1280 BCM_NMPDU_USER_DATA_D2 1000;
BA_ "GenSigTimeoutTime_HU_Mid_X451" SG_ 1280 BCM_NMPDU_USER_DATA_D3 1000;
BA_ "GenSigTimeoutTime_HU_High_X451" SG_ 1280 BCM_NMPDU_USER_DATA_D3 1000;
BA_ "GenSigTimeoutTime_HU_B" SG_ 1280 BCM_NMPDU_USER_DATA_D3 1000;
BA_ "GenSigTimeoutTime_HU_A" SG_ 1280 BCM_NMPDU_USER_DATA_D3 1000;
BA_ "GenSigTimeoutMsg_HU_Mid_X451" SG_ 1280 BCM_NMPDU_USER_DATA_D3 1000;
BA_ "GenSigTimeoutMsg_HU_High_X451" SG_ 1280 BCM_NMPDU_USER_DATA_D3 1000;
BA_ "GenSigTimeoutMsg_HU_B" SG_ 1280 BCM_NMPDU_USER_DATA_D3 1000;
BA_ "GenSigTimeoutMsg_HU_A" SG_ 1280 BCM_NMPDU_USER_DATA_D3 1000;
BA_ "GenSigSendType" SG_ 1280 BCM_NMPDU_USER_DATA_D3 7;
BA_ "GenSigCycleTimeActive" SG_ 1280 BCM_NMPDU_USER_DATA_D3 200;
BA_ "GenSigCycleTime" SG_ 1280 BCM_NMPDU_USER_DATA_D3 200;
BA_ "GenSigTimeoutMsg_HU_High_X445" SG_ 1280 BCM_NMPDU_USER_DATA_D3 1000;
BA_ "GenSigTimeoutMsg_HU_Mid_X445" SG_ 1280 BCM_NMPDU_USER_DATA_D3 1000;
BA_ "GenSigTimeoutTime_HU_High_X445" SG_ 1280 BCM_NMPDU_USER_DATA_D3 1000;
BA_ "GenSigTimeoutTime_HU_Mid_X445" SG_ 1280 BCM_NMPDU_USER_DATA_D3 1000;
BA_ "GenSigTimeoutMsg_IVI" SG_ 1280 BCM_NMPDU_USER_DATA_D3 1000;
BA_ "GenSigTimeoutTime_IVI" SG_ 1280 BCM_NMPDU_USER_DATA_D3 1000;
BA_ "GenSigTimeoutTime_HU_Mid_X451" SG_ 1280 BCM_NMPDU_USER_DATA_D4 1000;
BA_ "GenSigTimeoutTime_HU_High_X451" SG_ 1280 BCM_NMPDU_USER_DATA_D4 1000;
BA_ "GenSigTimeoutTime_HU_B" SG_ 1280 BCM_NMPDU_USER_DATA_D4 1000;
BA_ "GenSigTimeoutTime_HU_A" SG_ 1280 BCM_NMPDU_USER_DATA_D4 1000;
BA_ "GenSigTimeoutMsg_HU_Mid_X451" SG_ 1280 BCM_NMPDU_USER_DATA_D4 1000;
BA_ "GenSigTimeoutMsg_HU_High_X451" SG_ 1280 BCM_NMPDU_USER_DATA_D4 1000;
BA_ "GenSigTimeoutMsg_HU_B" SG_ 1280 BCM_NMPDU_USER_DATA_D4 1000;
BA_ "GenSigTimeoutMsg_HU_A" SG_ 1280 BCM_NMPDU_USER_DATA_D4 1000;
BA_ "GenSigSendType" SG_ 1280 BCM_NMPDU_USER_DATA_D4 7;
BA_ "GenSigCycleTimeActive" SG_ 1280 BCM_NMPDU_USER_DATA_D4 200;
BA_ "GenSigCycleTime" SG_ 1280 BCM_NMPDU_USER_DATA_D4 200;
BA_ "GenSigTimeoutMsg_HU_High_X445" SG_ 1280 BCM_NMPDU_USER_DATA_D4 1000;
BA_ "GenSigTimeoutMsg_HU_Mid_X445" SG_ 1280 BCM_NMPDU_USER_DATA_D4 1000;
BA_ "GenSigTimeoutTime_HU_High_X445" SG_ 1280 BCM_NMPDU_USER_DATA_D4 1000;
BA_ "GenSigTimeoutTime_HU_Mid_X445" SG_ 1280 BCM_NMPDU_USER_DATA_D4 1000;
BA_ "GenSigTimeoutMsg_IVI" SG_ 1280 BCM_NMPDU_USER_DATA_D4 1000;
BA_ "GenSigTimeoutTime_IVI" SG_ 1280 BCM_NMPDU_USER_DATA_D4 1000;
BA_ "GenSigTimeoutTime_HU_Mid_X451" SG_ 1280 BCM_NMPDU_USER_DATA_D5 1000;
BA_ "GenSigTimeoutTime_HU_High_X451" SG_ 1280 BCM_NMPDU_USER_DATA_D5 1000;
BA_ "GenSigTimeoutTime_HU_B" SG_ 1280 BCM_NMPDU_USER_DATA_D5 1000;
BA_ "GenSigTimeoutTime_HU_A" SG_ 1280 BCM_NMPDU_USER_DATA_D5 1000;
BA_ "GenSigTimeoutMsg_HU_Mid_X451" SG_ 1280 BCM_NMPDU_USER_DATA_D5 1000;
BA_ "GenSigTimeoutMsg_HU_High_X451" SG_ 1280 BCM_NMPDU_USER_DATA_D5 1000;
BA_ "GenSigTimeoutMsg_HU_B" SG_ 1280 BCM_NMPDU_USER_DATA_D5 1000;
BA_ "GenSigTimeoutMsg_HU_A" SG_ 1280 BCM_NMPDU_USER_DATA_D5 1000;
BA_ "GenSigSendType" SG_ 1280 BCM_NMPDU_USER_DATA_D5 7;
BA_ "GenSigCycleTimeActive" SG_ 1280 BCM_NMPDU_USER_DATA_D5 200;
BA_ "GenSigCycleTime" SG_ 1280 BCM_NMPDU_USER_DATA_D5 200;
BA_ "GenSigTimeoutMsg_HU_High_X445" SG_ 1280 BCM_NMPDU_USER_DATA_D5 1000;
BA_ "GenSigTimeoutMsg_HU_Mid_X445" SG_ 1280 BCM_NMPDU_USER_DATA_D5 1000;
BA_ "GenSigTimeoutTime_HU_High_X445" SG_ 1280 BCM_NMPDU_USER_DATA_D5 1000;
BA_ "GenSigTimeoutTime_HU_Mid_X445" SG_ 1280 BCM_NMPDU_USER_DATA_D5 1000;
BA_ "GenSigTimeoutMsg_IVI" SG_ 1280 BCM_NMPDU_USER_DATA_D5 1000;
BA_ "GenSigTimeoutTime_IVI" SG_ 1280 BCM_NMPDU_USER_DATA_D5 1000;
BA_ "GenSigTimeoutTime_HU_Mid_X451" SG_ 1282 HU_NMPDU_SRC_ECU_ID 1000;
BA_ "GenSigTimeoutTime_HU_High_X451" SG_ 1282 HU_NMPDU_SRC_ECU_ID 1000;
BA_ "GenSigTimeoutTime_HU_B" SG_ 1282 HU_NMPDU_SRC_ECU_ID 1000;
BA_ "GenSigTimeoutTime_HU_A" SG_ 1282 HU_NMPDU_SRC_ECU_ID 1000;
BA_ "GenSigTimeoutMsg_HU_Mid_X451" SG_ 1282 HU_NMPDU_SRC_ECU_ID 1000;
BA_ "GenSigTimeoutMsg_HU_High_X451" SG_ 1282 HU_NMPDU_SRC_ECU_ID 1000;
BA_ "GenSigTimeoutMsg_HU_B" SG_ 1282 HU_NMPDU_SRC_ECU_ID 1000;
BA_ "GenSigTimeoutMsg_HU_A" SG_ 1282 HU_NMPDU_SRC_ECU_ID 1000;
BA_ "GenSigSendType" SG_ 1282 HU_NMPDU_SRC_ECU_ID 7;
BA_ "GenSigCycleTimeActive" SG_ 1282 HU_NMPDU_SRC_ECU_ID 200;
BA_ "GenSigCycleTime" SG_ 1282 HU_NMPDU_SRC_ECU_ID 200;
BA_ "GenSigTimeoutMsg_HU_High_X445" SG_ 1282 HU_NMPDU_SRC_ECU_ID 1000;
BA_ "GenSigTimeoutMsg_HU_Mid_X445" SG_ 1282 HU_NMPDU_SRC_ECU_ID 1000;
BA_ "GenSigTimeoutTime_HU_High_X445" SG_ 1282 HU_NMPDU_SRC_ECU_ID 1000;
BA_ "GenSigTimeoutTime_HU_Mid_X445" SG_ 1282 HU_NMPDU_SRC_ECU_ID 1000;
BA_ "GenSigTimeoutMsg_IVI" SG_ 1282 HU_NMPDU_SRC_ECU_ID 1000;
BA_ "GenSigTimeoutTime_IVI" SG_ 1282 HU_NMPDU_SRC_ECU_ID 1000;
BA_ "GenSigTimeoutTime_HU_Mid_X451" SG_ 1282 RepeatMessageReq_HU 1000;
BA_ "GenSigTimeoutTime_HU_High_X451" SG_ 1282 RepeatMessageReq_HU 1000;
BA_ "GenSigTimeoutTime_HU_B" SG_ 1282 RepeatMessageReq_HU 1000;
BA_ "GenSigTimeoutTime_HU_A" SG_ 1282 RepeatMessageReq_HU 1000;
BA_ "GenSigTimeoutMsg_HU_Mid_X451" SG_ 1282 RepeatMessageReq_HU 1000;
BA_ "GenSigTimeoutMsg_HU_High_X451" SG_ 1282 RepeatMessageReq_HU 1000;
BA_ "GenSigTimeoutMsg_HU_B" SG_ 1282 RepeatMessageReq_HU 1000;
BA_ "GenSigTimeoutMsg_HU_A" SG_ 1282 RepeatMessageReq_HU 1000;
BA_ "GenSigSendType" SG_ 1282 RepeatMessageReq_HU 7;
BA_ "GenSigCycleTimeActive" SG_ 1282 RepeatMessageReq_HU 200;
BA_ "GenSigCycleTime" SG_ 1282 RepeatMessageReq_HU 200;
BA_ "GenSigTimeoutMsg_HU_High_X445" SG_ 1282 RepeatMessageReq_HU 1000;
BA_ "GenSigTimeoutMsg_HU_Mid_X445" SG_ 1282 RepeatMessageReq_HU 1000;
BA_ "GenSigTimeoutTime_HU_High_X445" SG_ 1282 RepeatMessageReq_HU 1000;
BA_ "GenSigTimeoutTime_HU_Mid_X445" SG_ 1282 RepeatMessageReq_HU 1000;
BA_ "GenSigTimeoutMsg_IVI" SG_ 1282 RepeatMessageReq_HU 1000;
BA_ "GenSigTimeoutTime_IVI" SG_ 1282 RepeatMessageReq_HU 1000;
BA_ "GenSigTimeoutTime_HU_Mid_X451" SG_ 1282 Reserved8 1000;
BA_ "GenSigTimeoutTime_HU_High_X451" SG_ 1282 Reserved8 1000;
BA_ "GenSigTimeoutTime_HU_B" SG_ 1282 Reserved8 1000;
BA_ "GenSigTimeoutTime_HU_A" SG_ 1282 Reserved8 1000;
BA_ "GenSigTimeoutMsg_HU_Mid_X451" SG_ 1282 Reserved8 1000;
BA_ "GenSigTimeoutMsg_HU_High_X451" SG_ 1282 Reserved8 1000;
BA_ "GenSigTimeoutMsg_HU_B" SG_ 1282 Reserved8 1000;
BA_ "GenSigTimeoutMsg_HU_A" SG_ 1282 Reserved8 1000;
BA_ "GenSigSendType" SG_ 1282 Reserved8 7;
BA_ "GenSigCycleTimeActive" SG_ 1282 Reserved8 200;
BA_ "GenSigCycleTime" SG_ 1282 Reserved8 200;
BA_ "GenSigTimeoutMsg_HU_High_X445" SG_ 1282 Reserved8 1000;
BA_ "GenSigTimeoutMsg_HU_Mid_X445" SG_ 1282 Reserved8 1000;
BA_ "GenSigTimeoutTime_HU_High_X445" SG_ 1282 Reserved8 1000;
BA_ "GenSigTimeoutTime_HU_Mid_X445" SG_ 1282 Reserved8 1000;
BA_ "GenSigTimeoutMsg_IVI" SG_ 1282 Reserved8 1000;
BA_ "GenSigTimeoutTime_IVI" SG_ 1282 Reserved8 1000;
BA_ "GenSigTimeoutTime_HU_Mid_X451" SG_ 1282 Reserved9 1000;
BA_ "GenSigTimeoutTime_HU_High_X451" SG_ 1282 Reserved9 1000;
BA_ "GenSigTimeoutTime_HU_B" SG_ 1282 Reserved9 1000;
BA_ "GenSigTimeoutTime_HU_A" SG_ 1282 Reserved9 1000;
BA_ "GenSigTimeoutMsg_HU_Mid_X451" SG_ 1282 Reserved9 1000;
BA_ "GenSigTimeoutMsg_HU_High_X451" SG_ 1282 Reserved9 1000;
BA_ "GenSigTimeoutMsg_HU_B" SG_ 1282 Reserved9 1000;
BA_ "GenSigTimeoutMsg_HU_A" SG_ 1282 Reserved9 1000;
BA_ "GenSigSendType" SG_ 1282 Reserved9 7;
BA_ "GenSigCycleTimeActive" SG_ 1282 Reserved9 200;
BA_ "GenSigCycleTime" SG_ 1282 Reserved9 200;
BA_ "GenSigTimeoutMsg_HU_High_X445" SG_ 1282 Reserved9 1000;
BA_ "GenSigTimeoutMsg_HU_Mid_X445" SG_ 1282 Reserved9 1000;
BA_ "GenSigTimeoutTime_HU_High_X445" SG_ 1282 Reserved9 1000;
BA_ "GenSigTimeoutTime_HU_Mid_X445" SG_ 1282 Reserved9 1000;
BA_ "GenSigTimeoutMsg_IVI" SG_ 1282 Reserved9 1000;
BA_ "GenSigTimeoutTime_IVI" SG_ 1282 Reserved9 1000;
BA_ "GenSigTimeoutTime_HU_Mid_X451" SG_ 1282 NMCoOrdSlpReady_HU 1000;
BA_ "GenSigTimeoutTime_HU_High_X451" SG_ 1282 NMCoOrdSlpReady_HU 1000;
BA_ "GenSigTimeoutTime_HU_B" SG_ 1282 NMCoOrdSlpReady_HU 1000;
BA_ "GenSigTimeoutTime_HU_A" SG_ 1282 NMCoOrdSlpReady_HU 1000;
BA_ "GenSigTimeoutMsg_HU_Mid_X451" SG_ 1282 NMCoOrdSlpReady_HU 1000;
BA_ "GenSigTimeoutMsg_HU_High_X451" SG_ 1282 NMCoOrdSlpReady_HU 1000;
BA_ "GenSigTimeoutMsg_HU_B" SG_ 1282 NMCoOrdSlpReady_HU 1000;
BA_ "GenSigTimeoutMsg_HU_A" SG_ 1282 NMCoOrdSlpReady_HU 1000;
BA_ "GenSigSendType" SG_ 1282 NMCoOrdSlpReady_HU 7;
BA_ "GenSigCycleTimeActive" SG_ 1282 NMCoOrdSlpReady_HU 200;
BA_ "GenSigCycleTime" SG_ 1282 NMCoOrdSlpReady_HU 200;
BA_ "GenSigTimeoutMsg_HU_High_X445" SG_ 1282 NMCoOrdSlpReady_HU 1000;
BA_ "GenSigTimeoutMsg_HU_Mid_X445" SG_ 1282 NMCoOrdSlpReady_HU 1000;
BA_ "GenSigTimeoutTime_HU_High_X445" SG_ 1282 NMCoOrdSlpReady_HU 1000;
BA_ "GenSigTimeoutTime_HU_Mid_X445" SG_ 1282 NMCoOrdSlpReady_HU 1000;
BA_ "GenSigTimeoutMsg_IVI" SG_ 1282 NMCoOrdSlpReady_HU 1000;
BA_ "GenSigTimeoutTime_IVI" SG_ 1282 NMCoOrdSlpReady_HU 1000;
BA_ "GenSigTimeoutTime_HU_Mid_X451" SG_ 1282 ActiveWakeUp_HU 1000;
BA_ "GenSigTimeoutTime_HU_High_X451" SG_ 1282 ActiveWakeUp_HU 1000;
BA_ "GenSigTimeoutTime_HU_B" SG_ 1282 ActiveWakeUp_HU 1000;
BA_ "GenSigTimeoutTime_HU_A" SG_ 1282 ActiveWakeUp_HU 1000;
BA_ "GenSigTimeoutMsg_HU_Mid_X451" SG_ 1282 ActiveWakeUp_HU 1000;
BA_ "GenSigTimeoutMsg_HU_High_X451" SG_ 1282 ActiveWakeUp_HU 1000;
BA_ "GenSigTimeoutMsg_HU_B" SG_ 1282 ActiveWakeUp_HU 1000;
BA_ "GenSigTimeoutMsg_HU_A" SG_ 1282 ActiveWakeUp_HU 1000;
BA_ "GenSigSendType" SG_ 1282 ActiveWakeUp_HU 7;
BA_ "GenSigCycleTimeActive" SG_ 1282 ActiveWakeUp_HU 200;
BA_ "GenSigCycleTime" SG_ 1282 ActiveWakeUp_HU 200;
BA_ "GenSigTimeoutMsg_HU_High_X445" SG_ 1282 ActiveWakeUp_HU 1000;
BA_ "GenSigTimeoutMsg_HU_Mid_X445" SG_ 1282 ActiveWakeUp_HU 1000;
BA_ "GenSigTimeoutTime_HU_High_X445" SG_ 1282 ActiveWakeUp_HU 1000;
BA_ "GenSigTimeoutTime_HU_Mid_X445" SG_ 1282 ActiveWakeUp_HU 1000;
BA_ "GenSigTimeoutMsg_IVI" SG_ 1282 ActiveWakeUp_HU 1000;
BA_ "GenSigTimeoutTime_IVI" SG_ 1282 ActiveWakeUp_HU 1000;
BA_ "GenSigTimeoutTime_HU_Mid_X451" SG_ 1282 Reserved10 1000;
BA_ "GenSigTimeoutTime_HU_High_X451" SG_ 1282 Reserved10 1000;
BA_ "GenSigTimeoutTime_HU_B" SG_ 1282 Reserved10 1000;
BA_ "GenSigTimeoutTime_HU_A" SG_ 1282 Reserved10 1000;
BA_ "GenSigTimeoutMsg_HU_Mid_X451" SG_ 1282 Reserved10 1000;
BA_ "GenSigTimeoutMsg_HU_High_X451" SG_ 1282 Reserved10 1000;
BA_ "GenSigTimeoutMsg_HU_B" SG_ 1282 Reserved10 1000;
BA_ "GenSigTimeoutMsg_HU_A" SG_ 1282 Reserved10 1000;
BA_ "GenSigSendType" SG_ 1282 Reserved10 7;
BA_ "GenSigCycleTimeActive" SG_ 1282 Reserved10 200;
BA_ "GenSigCycleTime" SG_ 1282 Reserved10 200;
BA_ "GenSigTimeoutMsg_HU_High_X445" SG_ 1282 Reserved10 1000;
BA_ "GenSigTimeoutMsg_HU_Mid_X445" SG_ 1282 Reserved10 1000;
BA_ "GenSigTimeoutTime_HU_High_X445" SG_ 1282 Reserved10 1000;
BA_ "GenSigTimeoutTime_HU_Mid_X445" SG_ 1282 Reserved10 1000;
BA_ "GenSigTimeoutMsg_IVI" SG_ 1282 Reserved10 1000;
BA_ "GenSigTimeoutTime_IVI" SG_ 1282 Reserved10 1000;
BA_ "GenSigTimeoutTime_HU_Mid_X451" SG_ 1282 PartialNetworkInformation_HU 1000;
BA_ "GenSigTimeoutTime_HU_High_X451" SG_ 1282 PartialNetworkInformation_HU 1000;
BA_ "GenSigTimeoutTime_HU_B" SG_ 1282 PartialNetworkInformation_HU 1000;
BA_ "GenSigTimeoutTime_HU_A" SG_ 1282 PartialNetworkInformation_HU 1000;
BA_ "GenSigTimeoutMsg_HU_Mid_X451" SG_ 1282 PartialNetworkInformation_HU 1000;
BA_ "GenSigTimeoutMsg_HU_High_X451" SG_ 1282 PartialNetworkInformation_HU 1000;
BA_ "GenSigTimeoutMsg_HU_B" SG_ 1282 PartialNetworkInformation_HU 1000;
BA_ "GenSigTimeoutMsg_HU_A" SG_ 1282 PartialNetworkInformation_HU 1000;
BA_ "GenSigSendType" SG_ 1282 PartialNetworkInformation_HU 7;
BA_ "GenSigCycleTimeActive" SG_ 1282 PartialNetworkInformation_HU 200;
BA_ "GenSigCycleTime" SG_ 1282 PartialNetworkInformation_HU 200;
BA_ "GenSigTimeoutMsg_HU_High_X445" SG_ 1282 PartialNetworkInformation_HU 1000;
BA_ "GenSigTimeoutMsg_HU_Mid_X445" SG_ 1282 PartialNetworkInformation_HU 1000;
BA_ "GenSigTimeoutTime_HU_High_X445" SG_ 1282 PartialNetworkInformation_HU 1000;
BA_ "GenSigTimeoutTime_HU_Mid_X445" SG_ 1282 PartialNetworkInformation_HU 1000;
BA_ "GenSigTimeoutMsg_IVI" SG_ 1282 PartialNetworkInformation_HU 1000;
BA_ "GenSigTimeoutTime_IVI" SG_ 1282 PartialNetworkInformation_HU 1000;
BA_ "GenSigTimeoutTime_HU_Mid_X451" SG_ 1282 Reserved11 1000;
BA_ "GenSigTimeoutTime_HU_High_X451" SG_ 1282 Reserved11 1000;
BA_ "GenSigTimeoutTime_HU_B" SG_ 1282 Reserved11 1000;
BA_ "GenSigTimeoutTime_HU_A" SG_ 1282 Reserved11 1000;
BA_ "GenSigTimeoutMsg_HU_Mid_X451" SG_ 1282 Reserved11 1000;
BA_ "GenSigTimeoutMsg_HU_High_X451" SG_ 1282 Reserved11 1000;
BA_ "GenSigTimeoutMsg_HU_B" SG_ 1282 Reserved11 1000;
BA_ "GenSigTimeoutMsg_HU_A" SG_ 1282 Reserved11 1000;
BA_ "GenSigSendType" SG_ 1282 Reserved11 7;
BA_ "GenSigCycleTimeActive" SG_ 1282 Reserved11 200;
BA_ "GenSigCycleTime" SG_ 1282 Reserved11 200;
BA_ "GenSigTimeoutMsg_HU_High_X445" SG_ 1282 Reserved11 1000;
BA_ "GenSigTimeoutMsg_HU_Mid_X445" SG_ 1282 Reserved11 1000;
BA_ "GenSigTimeoutTime_HU_High_X445" SG_ 1282 Reserved11 1000;
BA_ "GenSigTimeoutTime_HU_Mid_X445" SG_ 1282 Reserved11 1000;
BA_ "GenSigTimeoutMsg_IVI" SG_ 1282 Reserved11 1000;
BA_ "GenSigTimeoutTime_IVI" SG_ 1282 Reserved11 1000;
BA_ "GenSigTimeoutTime_HU_Mid_X451" SG_ 1282 CurrentState_HU 1000;
BA_ "GenSigTimeoutTime_HU_High_X451" SG_ 1282 CurrentState_HU 1000;
BA_ "GenSigTimeoutTime_HU_B" SG_ 1282 CurrentState_HU 1000;
BA_ "GenSigTimeoutTime_HU_A" SG_ 1282 CurrentState_HU 1000;
BA_ "GenSigTimeoutMsg_HU_Mid_X451" SG_ 1282 CurrentState_HU 1000;
BA_ "GenSigTimeoutMsg_HU_High_X451" SG_ 1282 CurrentState_HU 1000;
BA_ "GenSigTimeoutMsg_HU_B" SG_ 1282 CurrentState_HU 1000;
BA_ "GenSigTimeoutMsg_HU_A" SG_ 1282 CurrentState_HU 1000;
BA_ "GenSigSendType" SG_ 1282 CurrentState_HU 7;
BA_ "GenSigCycleTimeActive" SG_ 1282 CurrentState_HU 200;
BA_ "GenSigCycleTime" SG_ 1282 CurrentState_HU 200;
BA_ "GenSigTimeoutMsg_HU_High_X445" SG_ 1282 CurrentState_HU 1000;
BA_ "GenSigTimeoutMsg_HU_Mid_X445" SG_ 1282 CurrentState_HU 1000;
BA_ "GenSigTimeoutTime_HU_High_X445" SG_ 1282 CurrentState_HU 1000;
BA_ "GenSigTimeoutTime_HU_Mid_X445" SG_ 1282 CurrentState_HU 1000;
BA_ "GenSigTimeoutMsg_IVI" SG_ 1282 CurrentState_HU 1000;
BA_ "GenSigTimeoutTime_IVI" SG_ 1282 CurrentState_HU 1000;
BA_ "GenSigTimeoutTime_HU_Mid_X451" SG_ 1282 PreviousState_HU 1000;
BA_ "GenSigTimeoutTime_HU_High_X451" SG_ 1282 PreviousState_HU 1000;
BA_ "GenSigTimeoutTime_HU_B" SG_ 1282 PreviousState_HU 1000;
BA_ "GenSigTimeoutTime_HU_A" SG_ 1282 PreviousState_HU 1000;
BA_ "GenSigTimeoutMsg_HU_Mid_X451" SG_ 1282 PreviousState_HU 1000;
BA_ "GenSigTimeoutMsg_HU_High_X451" SG_ 1282 PreviousState_HU 1000;
BA_ "GenSigTimeoutMsg_HU_B" SG_ 1282 PreviousState_HU 1000;
BA_ "GenSigTimeoutMsg_HU_A" SG_ 1282 PreviousState_HU 1000;
BA_ "GenSigSendType" SG_ 1282 PreviousState_HU 7;
BA_ "GenSigCycleTimeActive" SG_ 1282 PreviousState_HU 200;
BA_ "GenSigCycleTime" SG_ 1282 PreviousState_HU 200;
BA_ "GenSigTimeoutMsg_HU_High_X445" SG_ 1282 PreviousState_HU 1000;
BA_ "GenSigTimeoutMsg_HU_Mid_X445" SG_ 1282 PreviousState_HU 1000;
BA_ "GenSigTimeoutTime_HU_High_X445" SG_ 1282 PreviousState_HU 1000;
BA_ "GenSigTimeoutTime_HU_Mid_X445" SG_ 1282 PreviousState_HU 1000;
BA_ "GenSigTimeoutMsg_IVI" SG_ 1282 PreviousState_HU 1000;
BA_ "GenSigTimeoutTime_IVI" SG_ 1282 PreviousState_HU 1000;
BA_ "GenSigTimeoutTime_HU_Mid_X451" SG_ 1282 Reserved12 1000;
BA_ "GenSigTimeoutTime_HU_High_X451" SG_ 1282 Reserved12 1000;
BA_ "GenSigTimeoutTime_HU_B" SG_ 1282 Reserved12 1000;
BA_ "GenSigTimeoutTime_HU_A" SG_ 1282 Reserved12 1000;
BA_ "GenSigTimeoutMsg_HU_Mid_X451" SG_ 1282 Reserved12 1000;
BA_ "GenSigTimeoutMsg_HU_High_X451" SG_ 1282 Reserved12 1000;
BA_ "GenSigTimeoutMsg_HU_B" SG_ 1282 Reserved12 1000;
BA_ "GenSigTimeoutMsg_HU_A" SG_ 1282 Reserved12 1000;
BA_ "GenSigSendType" SG_ 1282 Reserved12 7;
BA_ "GenSigCycleTimeActive" SG_ 1282 Reserved12 200;
BA_ "GenSigCycleTime" SG_ 1282 Reserved12 200;
BA_ "GenSigTimeoutMsg_HU_High_X445" SG_ 1282 Reserved12 1000;
BA_ "GenSigTimeoutMsg_HU_Mid_X445" SG_ 1282 Reserved12 1000;
BA_ "GenSigTimeoutTime_HU_High_X445" SG_ 1282 Reserved12 1000;
BA_ "GenSigTimeoutTime_HU_Mid_X445" SG_ 1282 Reserved12 1000;
BA_ "GenSigTimeoutMsg_IVI" SG_ 1282 Reserved12 1000;
BA_ "GenSigTimeoutTime_IVI" SG_ 1282 Reserved12 1000;
BA_ "GenSigTimeoutTime_HU_Mid_X451" SG_ 1282 Reserved13 1000;
BA_ "GenSigTimeoutTime_HU_High_X451" SG_ 1282 Reserved13 1000;
BA_ "GenSigTimeoutTime_HU_B" SG_ 1282 Reserved13 1000;
BA_ "GenSigTimeoutTime_HU_A" SG_ 1282 Reserved13 1000;
BA_ "GenSigTimeoutMsg_HU_Mid_X451" SG_ 1282 Reserved13 1000;
BA_ "GenSigTimeoutMsg_HU_High_X451" SG_ 1282 Reserved13 1000;
BA_ "GenSigTimeoutMsg_HU_B" SG_ 1282 Reserved13 1000;
BA_ "GenSigTimeoutMsg_HU_A" SG_ 1282 Reserved13 1000;
BA_ "GenSigSendType" SG_ 1282 Reserved13 7;
BA_ "GenSigCycleTimeActive" SG_ 1282 Reserved13 200;
BA_ "GenSigCycleTime" SG_ 1282 Reserved13 200;
BA_ "GenSigTimeoutMsg_HU_High_X445" SG_ 1282 Reserved13 1000;
BA_ "GenSigTimeoutMsg_HU_Mid_X445" SG_ 1282 Reserved13 1000;
BA_ "GenSigTimeoutTime_HU_High_X445" SG_ 1282 Reserved13 1000;
BA_ "GenSigTimeoutTime_HU_Mid_X445" SG_ 1282 Reserved13 1000;
BA_ "GenSigTimeoutMsg_IVI" SG_ 1282 Reserved13 1000;
BA_ "GenSigTimeoutTime_IVI" SG_ 1282 Reserved13 1000;
BA_ "GenSigTimeoutTime_HU_Mid_X451" SG_ 1282 Reserved14 1000;
BA_ "GenSigTimeoutTime_HU_High_X451" SG_ 1282 Reserved14 1000;
BA_ "GenSigTimeoutTime_HU_B" SG_ 1282 Reserved14 1000;
BA_ "GenSigTimeoutTime_HU_A" SG_ 1282 Reserved14 1000;
BA_ "GenSigTimeoutMsg_HU_Mid_X451" SG_ 1282 Reserved14 1000;
BA_ "GenSigTimeoutMsg_HU_High_X451" SG_ 1282 Reserved14 1000;
BA_ "GenSigTimeoutMsg_HU_B" SG_ 1282 Reserved14 1000;
BA_ "GenSigTimeoutMsg_HU_A" SG_ 1282 Reserved14 1000;
BA_ "GenSigSendType" SG_ 1282 Reserved14 7;
BA_ "GenSigCycleTimeActive" SG_ 1282 Reserved14 200;
BA_ "GenSigCycleTime" SG_ 1282 Reserved14 200;
BA_ "GenSigTimeoutMsg_HU_High_X445" SG_ 1282 Reserved14 1000;
BA_ "GenSigTimeoutMsg_HU_Mid_X445" SG_ 1282 Reserved14 1000;
BA_ "GenSigTimeoutTime_HU_High_X445" SG_ 1282 Reserved14 1000;
BA_ "GenSigTimeoutTime_HU_Mid_X445" SG_ 1282 Reserved14 1000;
BA_ "GenSigTimeoutMsg_IVI" SG_ 1282 Reserved14 1000;
BA_ "GenSigTimeoutTime_IVI" SG_ 1282 Reserved14 1000;
BA_ "GenSigTimeoutTime_HU_Mid_X451" SG_ 1282 Reserved15 1000;
BA_ "GenSigTimeoutTime_HU_High_X451" SG_ 1282 Reserved15 1000;
BA_ "GenSigTimeoutTime_HU_B" SG_ 1282 Reserved15 1000;
BA_ "GenSigTimeoutTime_HU_A" SG_ 1282 Reserved15 1000;
BA_ "GenSigTimeoutMsg_HU_Mid_X451" SG_ 1282 Reserved15 1000;
BA_ "GenSigTimeoutMsg_HU_High_X451" SG_ 1282 Reserved15 1000;
BA_ "GenSigTimeoutMsg_HU_B" SG_ 1282 Reserved15 1000;
BA_ "GenSigTimeoutMsg_HU_A" SG_ 1282 Reserved15 1000;
BA_ "GenSigSendType" SG_ 1282 Reserved15 7;
BA_ "GenSigCycleTimeActive" SG_ 1282 Reserved15 200;
BA_ "GenSigCycleTime" SG_ 1282 Reserved15 200;
BA_ "GenSigTimeoutMsg_HU_High_X445" SG_ 1282 Reserved15 1000;
BA_ "GenSigTimeoutMsg_HU_Mid_X445" SG_ 1282 Reserved15 1000;
BA_ "GenSigTimeoutTime_HU_High_X445" SG_ 1282 Reserved15 1000;
BA_ "GenSigTimeoutTime_HU_Mid_X445" SG_ 1282 Reserved15 1000;
BA_ "GenSigTimeoutMsg_IVI" SG_ 1282 Reserved15 1000;
BA_ "GenSigTimeoutTime_IVI" SG_ 1282 Reserved15 1000;
BA_ "GenSigTimeoutTime_HU_Mid_X451" SG_ 1282 HU_NMPDU_USER_DATA_1 1000;
BA_ "GenSigTimeoutTime_HU_High_X451" SG_ 1282 HU_NMPDU_USER_DATA_1 1000;
BA_ "GenSigTimeoutTime_HU_B" SG_ 1282 HU_NMPDU_USER_DATA_1 1000;
BA_ "GenSigTimeoutTime_HU_A" SG_ 1282 HU_NMPDU_USER_DATA_1 1000;
BA_ "GenSigTimeoutMsg_HU_Mid_X451" SG_ 1282 HU_NMPDU_USER_DATA_1 1000;
BA_ "GenSigTimeoutMsg_HU_High_X451" SG_ 1282 HU_NMPDU_USER_DATA_1 1000;
BA_ "GenSigTimeoutMsg_HU_B" SG_ 1282 HU_NMPDU_USER_DATA_1 1000;
BA_ "GenSigTimeoutMsg_HU_A" SG_ 1282 HU_NMPDU_USER_DATA_1 1000;
BA_ "GenSigSendType" SG_ 1282 HU_NMPDU_USER_DATA_1 7;
BA_ "GenSigCycleTimeActive" SG_ 1282 HU_NMPDU_USER_DATA_1 200;
BA_ "GenSigCycleTime" SG_ 1282 HU_NMPDU_USER_DATA_1 200;
BA_ "GenSigTimeoutMsg_HU_High_X445" SG_ 1282 HU_NMPDU_USER_DATA_1 1000;
BA_ "GenSigTimeoutMsg_HU_Mid_X445" SG_ 1282 HU_NMPDU_USER_DATA_1 1000;
BA_ "GenSigTimeoutTime_HU_High_X445" SG_ 1282 HU_NMPDU_USER_DATA_1 1000;
BA_ "GenSigTimeoutTime_HU_Mid_X445" SG_ 1282 HU_NMPDU_USER_DATA_1 1000;
BA_ "GenSigTimeoutMsg_IVI" SG_ 1282 HU_NMPDU_USER_DATA_1 1000;
BA_ "GenSigTimeoutTime_IVI" SG_ 1282 HU_NMPDU_USER_DATA_1 1000;
BA_ "GenSigTimeoutTime_HU_Mid_X451" SG_ 1282 HU_NMPDU_USER_DATA_2 1000;
BA_ "GenSigTimeoutTime_HU_High_X451" SG_ 1282 HU_NMPDU_USER_DATA_2 1000;
BA_ "GenSigTimeoutTime_HU_B" SG_ 1282 HU_NMPDU_USER_DATA_2 1000;
BA_ "GenSigTimeoutTime_HU_A" SG_ 1282 HU_NMPDU_USER_DATA_2 1000;
BA_ "GenSigTimeoutMsg_HU_Mid_X451" SG_ 1282 HU_NMPDU_USER_DATA_2 1000;
BA_ "GenSigTimeoutMsg_HU_High_X451" SG_ 1282 HU_NMPDU_USER_DATA_2 1000;
BA_ "GenSigTimeoutMsg_HU_B" SG_ 1282 HU_NMPDU_USER_DATA_2 1000;
BA_ "GenSigTimeoutMsg_HU_A" SG_ 1282 HU_NMPDU_USER_DATA_2 1000;
BA_ "GenSigSendType" SG_ 1282 HU_NMPDU_USER_DATA_2 7;
BA_ "GenSigCycleTimeActive" SG_ 1282 HU_NMPDU_USER_DATA_2 200;
BA_ "GenSigCycleTime" SG_ 1282 HU_NMPDU_USER_DATA_2 200;
BA_ "GenSigTimeoutMsg_HU_High_X445" SG_ 1282 HU_NMPDU_USER_DATA_2 1000;
BA_ "GenSigTimeoutMsg_HU_Mid_X445" SG_ 1282 HU_NMPDU_USER_DATA_2 1000;
BA_ "GenSigTimeoutTime_HU_High_X445" SG_ 1282 HU_NMPDU_USER_DATA_2 1000;
BA_ "GenSigTimeoutTime_HU_Mid_X445" SG_ 1282 HU_NMPDU_USER_DATA_2 1000;
BA_ "GenSigTimeoutMsg_IVI" SG_ 1282 HU_NMPDU_USER_DATA_2 1000;
BA_ "GenSigTimeoutTime_IVI" SG_ 1282 HU_NMPDU_USER_DATA_2 1000;
BA_ "GenSigTimeoutTime_HU_Mid_X451" SG_ 1282 HU_NMPDU_USER_DATA_3 1000;
BA_ "GenSigTimeoutTime_HU_High_X451" SG_ 1282 HU_NMPDU_USER_DATA_3 1000;
BA_ "GenSigTimeoutTime_HU_B" SG_ 1282 HU_NMPDU_USER_DATA_3 1000;
BA_ "GenSigTimeoutTime_HU_A" SG_ 1282 HU_NMPDU_USER_DATA_3 1000;
BA_ "GenSigTimeoutMsg_HU_Mid_X451" SG_ 1282 HU_NMPDU_USER_DATA_3 1000;
BA_ "GenSigTimeoutMsg_HU_High_X451" SG_ 1282 HU_NMPDU_USER_DATA_3 1000;
BA_ "GenSigTimeoutMsg_HU_B" SG_ 1282 HU_NMPDU_USER_DATA_3 1000;
BA_ "GenSigTimeoutMsg_HU_A" SG_ 1282 HU_NMPDU_USER_DATA_3 1000;
BA_ "GenSigSendType" SG_ 1282 HU_NMPDU_USER_DATA_3 7;
BA_ "GenSigCycleTimeActive" SG_ 1282 HU_NMPDU_USER_DATA_3 200;
BA_ "GenSigCycleTime" SG_ 1282 HU_NMPDU_USER_DATA_3 200;
BA_ "GenSigTimeoutMsg_HU_High_X445" SG_ 1282 HU_NMPDU_USER_DATA_3 1000;
BA_ "GenSigTimeoutMsg_HU_Mid_X445" SG_ 1282 HU_NMPDU_USER_DATA_3 1000;
BA_ "GenSigTimeoutTime_HU_High_X445" SG_ 1282 HU_NMPDU_USER_DATA_3 1000;
BA_ "GenSigTimeoutTime_HU_Mid_X445" SG_ 1282 HU_NMPDU_USER_DATA_3 1000;
BA_ "GenSigTimeoutMsg_IVI" SG_ 1282 HU_NMPDU_USER_DATA_3 1000;
BA_ "GenSigTimeoutTime_IVI" SG_ 1282 HU_NMPDU_USER_DATA_3 1000;
BA_ "GenSigTimeoutTime_HU_Mid_X451" SG_ 1282 HU_NMPDU_USER_DATA_4 1000;
BA_ "GenSigTimeoutTime_HU_High_X451" SG_ 1282 HU_NMPDU_USER_DATA_4 1000;
BA_ "GenSigTimeoutTime_HU_B" SG_ 1282 HU_NMPDU_USER_DATA_4 1000;
BA_ "GenSigTimeoutTime_HU_A" SG_ 1282 HU_NMPDU_USER_DATA_4 1000;
BA_ "GenSigTimeoutMsg_HU_Mid_X451" SG_ 1282 HU_NMPDU_USER_DATA_4 1000;
BA_ "GenSigTimeoutMsg_HU_High_X451" SG_ 1282 HU_NMPDU_USER_DATA_4 1000;
BA_ "GenSigTimeoutMsg_HU_B" SG_ 1282 HU_NMPDU_USER_DATA_4 1000;
BA_ "GenSigTimeoutMsg_HU_A" SG_ 1282 HU_NMPDU_USER_DATA_4 1000;
BA_ "GenSigSendType" SG_ 1282 HU_NMPDU_USER_DATA_4 7;
BA_ "GenSigCycleTimeActive" SG_ 1282 HU_NMPDU_USER_DATA_4 200;
BA_ "GenSigCycleTime" SG_ 1282 HU_NMPDU_USER_DATA_4 200;
BA_ "GenSigTimeoutMsg_HU_High_X445" SG_ 1282 HU_NMPDU_USER_DATA_4 1000;
BA_ "GenSigTimeoutMsg_HU_Mid_X445" SG_ 1282 HU_NMPDU_USER_DATA_4 1000;
BA_ "GenSigTimeoutTime_HU_High_X445" SG_ 1282 HU_NMPDU_USER_DATA_4 1000;
BA_ "GenSigTimeoutTime_HU_Mid_X445" SG_ 1282 HU_NMPDU_USER_DATA_4 1000;
BA_ "GenSigTimeoutMsg_IVI" SG_ 1282 HU_NMPDU_USER_DATA_4 1000;
BA_ "GenSigTimeoutTime_IVI" SG_ 1282 HU_NMPDU_USER_DATA_4 1000;
BA_ "GenSigTimeoutTime_HU_Mid_X451" SG_ 1282 HU_NMPDU_USER_DATA_5 1000;
BA_ "GenSigTimeoutTime_HU_High_X451" SG_ 1282 HU_NMPDU_USER_DATA_5 1000;
BA_ "GenSigTimeoutTime_HU_B" SG_ 1282 HU_NMPDU_USER_DATA_5 1000;
BA_ "GenSigTimeoutTime_HU_A" SG_ 1282 HU_NMPDU_USER_DATA_5 1000;
BA_ "GenSigTimeoutMsg_HU_Mid_X451" SG_ 1282 HU_NMPDU_USER_DATA_5 1000;
BA_ "GenSigTimeoutMsg_HU_High_X451" SG_ 1282 HU_NMPDU_USER_DATA_5 1000;
BA_ "GenSigTimeoutMsg_HU_B" SG_ 1282 HU_NMPDU_USER_DATA_5 1000;
BA_ "GenSigTimeoutMsg_HU_A" SG_ 1282 HU_NMPDU_USER_DATA_5 1000;
BA_ "GenSigSendType" SG_ 1282 HU_NMPDU_USER_DATA_5 7;
BA_ "GenSigCycleTimeActive" SG_ 1282 HU_NMPDU_USER_DATA_5 200;
BA_ "GenSigCycleTime" SG_ 1282 HU_NMPDU_USER_DATA_5 200;
BA_ "GenSigTimeoutMsg_HU_High_X445" SG_ 1282 HU_NMPDU_USER_DATA_5 1000;
BA_ "GenSigTimeoutMsg_HU_Mid_X445" SG_ 1282 HU_NMPDU_USER_DATA_5 1000;
BA_ "GenSigTimeoutTime_HU_High_X445" SG_ 1282 HU_NMPDU_USER_DATA_5 1000;
BA_ "GenSigTimeoutTime_HU_Mid_X445" SG_ 1282 HU_NMPDU_USER_DATA_5 1000;
BA_ "GenSigTimeoutMsg_IVI" SG_ 1282 HU_NMPDU_USER_DATA_5 1000;
BA_ "GenSigTimeoutTime_IVI" SG_ 1282 HU_NMPDU_USER_DATA_5 1000;
BA_ "GenSigTimeoutTime_HU_Mid_X451" SG_ 1547 HU_DiagResponse_UUDT 0;
BA_ "GenSigTimeoutTime_HU_High_X451" SG_ 1547 HU_DiagResponse_UUDT 0;
BA_ "GenSigTimeoutTime_HU_B" SG_ 1547 HU_DiagResponse_UUDT 0;
BA_ "GenSigTimeoutTime_HU_A" SG_ 1547 HU_DiagResponse_UUDT 0;
BA_ "GenSigTimeoutMsg_HU_Mid_X451" SG_ 1547 HU_DiagResponse_UUDT 0;
BA_ "GenSigTimeoutMsg_HU_High_X451" SG_ 1547 HU_DiagResponse_UUDT 0;
BA_ "GenSigTimeoutMsg_HU_B" SG_ 1547 HU_DiagResponse_UUDT 0;
BA_ "GenSigTimeoutMsg_HU_A" SG_ 1547 HU_DiagResponse_UUDT 0;
BA_ "GenSigSendType" SG_ 1547 HU_DiagResponse_UUDT 1;
BA_ "GenSigTimeoutMsg_HU_High_X445" SG_ 1547 HU_DiagResponse_UUDT 0;
BA_ "GenSigTimeoutMsg_HU_Mid_X445" SG_ 1547 HU_DiagResponse_UUDT 0;
BA_ "GenSigTimeoutTime_HU_High_X445" SG_ 1547 HU_DiagResponse_UUDT 0;
BA_ "GenSigTimeoutTime_HU_Mid_X445" SG_ 1547 HU_DiagResponse_UUDT 0;
BA_ "GenSigTimeoutMsg_IVI" SG_ 1547 HU_DiagResponse_UUDT 0;
BA_ "GenSigTimeoutTime_IVI" SG_ 1547 HU_DiagResponse_UUDT 0;
BA_ "GenSigTimeoutTime_HU_Mid_X451" SG_ 1795 DiagMsg 0;
BA_ "GenSigTimeoutTime_HU_High_X451" SG_ 1795 DiagMsg 0;
BA_ "GenSigTimeoutTime_HU_B" SG_ 1795 DiagMsg 0;
BA_ "GenSigTimeoutTime_HU_A" SG_ 1795 DiagMsg 0;
BA_ "GenSigTimeoutMsg_HU_Mid_X451" SG_ 1795 DiagMsg 0;
BA_ "GenSigTimeoutMsg_HU_High_X451" SG_ 1795 DiagMsg 0;
BA_ "GenSigTimeoutMsg_HU_B" SG_ 1795 DiagMsg 0;
BA_ "GenSigTimeoutMsg_HU_A" SG_ 1795 DiagMsg 0;
BA_ "GenSigSendType" SG_ 1795 DiagMsg 1;
BA_ "GenSigTimeoutMsg_HU_High_X445" SG_ 1795 DiagMsg 0;
BA_ "GenSigTimeoutMsg_HU_Mid_X445" SG_ 1795 DiagMsg 0;
BA_ "GenSigTimeoutTime_HU_High_X445" SG_ 1795 DiagMsg 0;
BA_ "GenSigTimeoutTime_HU_Mid_X445" SG_ 1795 DiagMsg 0;
BA_ "GenSigTimeoutMsg_IVI" SG_ 1795 DiagMsg 0;
BA_ "GenSigTimeoutTime_IVI" SG_ 1795 DiagMsg 0;
BA_ "GenSigTimeoutTime_HU_Mid_X451" SG_ 1803 HU_DiagResponse_USDT 0;
BA_ "GenSigTimeoutTime_HU_High_X451" SG_ 1803 HU_DiagResponse_USDT 0;
BA_ "GenSigTimeoutTime_HU_B" SG_ 1803 HU_DiagResponse_USDT 0;
BA_ "GenSigTimeoutTime_HU_A" SG_ 1803 HU_DiagResponse_USDT 0;
BA_ "GenSigTimeoutMsg_HU_Mid_X451" SG_ 1803 HU_DiagResponse_USDT 0;
BA_ "GenSigTimeoutMsg_HU_High_X451" SG_ 1803 HU_DiagResponse_USDT 0;
BA_ "GenSigTimeoutMsg_HU_B" SG_ 1803 HU_DiagResponse_USDT 0;
BA_ "GenSigTimeoutMsg_HU_A" SG_ 1803 HU_DiagResponse_USDT 0;
BA_ "GenSigSendType" SG_ 1803 HU_DiagResponse_USDT 1;
BA_ "GenSigTimeoutMsg_HU_High_X445" SG_ 1803 HU_DiagResponse_USDT 0;
BA_ "GenSigTimeoutMsg_HU_Mid_X445" SG_ 1803 HU_DiagResponse_USDT 0;
BA_ "GenSigTimeoutTime_HU_High_X445" SG_ 1803 HU_DiagResponse_USDT 0;
BA_ "GenSigTimeoutTime_HU_Mid_X445" SG_ 1803 HU_DiagResponse_USDT 0;
BA_ "GenSigTimeoutMsg_IVI" SG_ 1803 HU_DiagResponse_USDT 0;
BA_ "GenSigTimeoutTime_IVI" SG_ 1803 HU_DiagResponse_USDT 0;
BA_ "GenSigTimeoutTime_HU_Mid_X451" SG_ 2000 DiagMsg 0;
BA_ "GenSigTimeoutTime_HU_High_X451" SG_ 2000 DiagMsg 0;
BA_ "GenSigTimeoutTime_HU_B" SG_ 2000 DiagMsg 0;
BA_ "GenSigTimeoutTime_HU_A" SG_ 2000 DiagMsg 0;
BA_ "GenSigTimeoutMsg_HU_Mid_X451" SG_ 2000 DiagMsg 0;
BA_ "GenSigTimeoutMsg_HU_High_X451" SG_ 2000 DiagMsg 0;
BA_ "GenSigTimeoutMsg_HU_B" SG_ 2000 DiagMsg 0;
BA_ "GenSigTimeoutMsg_HU_A" SG_ 2000 DiagMsg 0;
BA_ "GenSigSendType" SG_ 2000 DiagMsg 1;
BA_ "GenSigTimeoutMsg_HU_High_X445" SG_ 2000 DiagMsg 0;
BA_ "GenSigTimeoutMsg_HU_Mid_X445" SG_ 2000 DiagMsg 0;
BA_ "GenSigTimeoutTime_HU_High_X445" SG_ 2000 DiagMsg 0;
BA_ "GenSigTimeoutTime_HU_Mid_X445" SG_ 2000 DiagMsg 0;
BA_ "GenSigTimeoutMsg_IVI" SG_ 2000 DiagMsg 0;
BA_ "GenSigTimeoutTime_IVI" SG_ 2000 DiagMsg 0;
BA_ "GenSigTimeoutTime_HU_Mid_X451" SG_ 2001 DiagMsg 0;
BA_ "GenSigTimeoutTime_HU_High_X451" SG_ 2001 DiagMsg 0;
BA_ "GenSigTimeoutTime_HU_B" SG_ 2001 DiagMsg 0;
BA_ "GenSigTimeoutTime_HU_A" SG_ 2001 DiagMsg 0;
BA_ "GenSigTimeoutMsg_HU_Mid_X451" SG_ 2001 DiagMsg 0;
BA_ "GenSigTimeoutMsg_HU_High_X451" SG_ 2001 DiagMsg 0;
BA_ "GenSigTimeoutMsg_HU_B" SG_ 2001 DiagMsg 0;
BA_ "GenSigTimeoutMsg_HU_A" SG_ 2001 DiagMsg 0;
BA_ "GenSigSendType" SG_ 2001 DiagMsg 1;
BA_ "GenSigTimeoutMsg_HU_High_X445" SG_ 2001 DiagMsg 0;
BA_ "GenSigTimeoutMsg_HU_Mid_X445" SG_ 2001 DiagMsg 0;
BA_ "GenSigTimeoutTime_HU_High_X445" SG_ 2001 DiagMsg 0;
BA_ "GenSigTimeoutTime_HU_Mid_X445" SG_ 2001 DiagMsg 0;
BA_ "GenSigTimeoutMsg_IVI" SG_ 2001 DiagMsg 0;
BA_ "GenSigTimeoutTime_IVI" SG_ 2001 DiagMsg 0;
BA_ "GenSigTimeoutTime_HU_Mid_X451" SG_ 2015 DiagMsg 0;
BA_ "GenSigTimeoutTime_HU_High_X451" SG_ 2015 DiagMsg 0;
BA_ "GenSigTimeoutTime_HU_B" SG_ 2015 DiagMsg 0;
BA_ "GenSigTimeoutTime_HU_A" SG_ 2015 DiagMsg 0;
BA_ "GenSigTimeoutMsg_HU_Mid_X451" SG_ 2015 DiagMsg 0;
BA_ "GenSigTimeoutMsg_HU_High_X451" SG_ 2015 DiagMsg 0;
BA_ "GenSigTimeoutMsg_HU_B" SG_ 2015 DiagMsg 0;
BA_ "GenSigTimeoutMsg_HU_A" SG_ 2015 DiagMsg 0;
BA_ "GenSigSendType" SG_ 2015 DiagMsg 1;
BA_ "GenSigTimeoutMsg_HU_High_X445" SG_ 2015 DiagMsg 0;
BA_ "GenSigTimeoutMsg_HU_Mid_X445" SG_ 2015 DiagMsg 0;
BA_ "GenSigTimeoutTime_HU_High_X445" SG_ 2015 DiagMsg 0;
BA_ "GenSigTimeoutTime_HU_Mid_X445" SG_ 2015 DiagMsg 0;
BA_ "GenSigTimeoutMsg_IVI" SG_ 2015 DiagMsg 0;
BA_ "GenSigTimeoutTime_IVI" SG_ 2015 DiagMsg 0;
VAL_ 938 LowBatUIdMsg 1 "Display -  UID battery is low" 0 "Don't Display -  UID battery is low" ;
VAL_ 946 HighBeamTelltaleStatus 3 "Signal not available" 2 "Reserved" 1 "Reserved" 0 "Value is plausible" ;
VAL_ 946 HighBeamTelltale 1 "High Beam ON" 0 "High Beam OFF" ;
VAL_ 946 DoorStateRearLHStatus 3 "Signal not available" 2 "Implausible" 1 "Reserved" 0 "Value is plausible" ;
VAL_ 946 DoorStatePassStatus 3 "Signal not avialable" 2 "Implausible" 1 "Reserved" 0 "Value is plausible" ;
VAL_ 946 DoorStatePass 1 "Open" 0 "Close" ;
VAL_ 946 DoorStateDrvrStatus 3 "Signal not available" 2 "Implausible" 1 "Reserved " 0 "Signal is plausible" ;
VAL_ 946 DoorStateDrvr 1 "open" 0 "Close" ;
VAL_ 946 DoorStateRearRH 1 "Open" 0 "Close" ;
VAL_ 946 DoorStateRearRHStatus 3 "Signal not available" 2 "Implausible" 1 "Reserved" 0 "Value is plausible" ;
VAL_ 946 DoorStateRearLH 1 "open" 0 "close" ;
VAL_ 946 WiperState 7 "Reserved" 6 "Reserved" 5 "Reserved" 4 "Reserved" 3 "Reserved" 2 "Reserved" 1 "Wiper ON" 0 "Wiper OFF" ;
VAL_ 946 TailgateState 1 "Open" 0 "Close" ;
VAL_ 946 WiperStateStatus 3 "Signal not available" 2 "Reserved" 1 "Reserved" 0 "Value is plausible" ;
VAL_ 946 TailgateStateStatus 3 "Signal not available" 2 "Implausible" 1 "Reserved" 0 "Value is plausible" ;
VAL_ 946 PositionLmpMalFn 1 "Position Lamp Malfunction" 0 "Position Lamp Normal" ;
VAL_ 946 PositionLmpMalFnStatus 3 "Signal not available" 2 "Reserved" 1 "Reserved" 0 "Value is plausible" ;
VAL_ 946 BrakeLmpMalFn 1 "Brake Lamp Malfunction" 0 "Brake Lamp Normal" ;
VAL_ 946 BrakeLmpMalFnStatus 3 "Signal not available" 2 "Reserved" 1 "Reserved" 0 "Value is plausible" ;
VAL_ 946 RevLampMalFn 1 "Reverse Lamp Malfunction" 0 "Reverse Lamp Normal" ;
VAL_ 946 RevLampMalFnStatus 3 "Signal not available" 2 "Reserved" 1 "Reserved" 0 "Value is plausible" ;
VAL_ 946 LowBeamMalFn 1 "Low Beam Malfunction" 0 "Low Beam Normal" ;
VAL_ 946 DRLTelltale 1 "DRL ON" 0 "DRL OFF" ;
VAL_ 946 FrontFogTelltale 1 "Front Fog Lamps ON" 0 "Front Fog Lamps OFF" ;
VAL_ 946 RearFogTelltaleStatus 3 "Signal not available" 2 "Reserved" 1 "Reserved" 0 "Value is plausible" ;
VAL_ 946 FrontFogTelltaleStatus 3 "Signal not available" 2 "Reserved" 1 "Reserved" 0 "Value is plausible" ;
VAL_ 946 DRLTelltaleStatus 3 "Signal not available" 2 "Reserved" 1 "Reserved" 0 "Value is plausible" ;
VAL_ 946 LowBeamMalFnStatus 3 "Signal not available" 2 "Reserved" 1 "Reserved" 0 "Value is plausible" ;
VAL_ 946 BonnetState 1 "Open" 0 "Close" ;
VAL_ 946 RearFogTelltale 1 "Rear Fog Lamps ON" 0 "Rear Fog Lamps OFF" ;
VAL_ 946 BonnetStateStatus 3 "Signal Not Available	" 2 "Implausible" 1 "Reserved for future" 0 "Value is plausible	

" ;
VAL_ 948 OdoICFullSigPeriodicStatus 3 "Signal Not Available" 2 "Information given by IC is implausible" 1 "Reserved for future use" 0 "Information given by IC is correct" ;
VAL_ 1173 SRR_MTO_Failure_Status 3 "Reserved" 2 "Failure healed aging in progress" 1 "Failrue detected DTC in memory" 0 "Failure is not detected" ;
VAL_ 1173 FCmMToFailureStatus 3 "Reserved" 2 "Failure is cleared and DTC is moved to history." 1 "Failure is detected and active DTC is stored in the error memory." 0 "Failure is currently not detected." ;
VAL_ 1173 Telematics_Invalid_FailureStatus 3 "Reserved" 2 "Failure healed aging in progress" 1 "Failure matured & DTC in memory" 0 "Failure is not detected" ;
VAL_ 1173 VCUMToFailureStatus 3 "Reserved" 2 "Failure healed aging in progress" 1 "Failure matured & DTC in memory" 0 "Failure is not detected" ;
VAL_ 1173 VCUInvalidFailureStatus 3 "Reserved" 2 "Failure healed aging in progress" 1 "Failure matured & DTC in memory" 0 "Failure is not detected" ;
VAL_ 1173 Telematics_MTO_Failure_status 3 "Reserved" 2 "Failure healed aging in progress" 1 "Failure matured & DTC in memory" 0 "Failure is not detected" ;
VAL_ 1173 EMsInvalidFailureStatus 3 "Reserved" 2 "Failure healed Ageing in progress" 1 "Failure matured & DTC in memory" 0 "Failure is not detected" ;
VAL_ 1173 AMT_AT_DCT_MTO_Failure_Status 3 "Reserved" 2 "Failure healed Ageing in progress" 1 "Failure matured & DTC in memory" 0 "Failure is not detected" ;
VAL_ 1173 AMT_AT_DCT_Invalid_Failure_Statu 3 "Reserved" 2 "Failure healed Ageing in progress" 1 "Failure matured & DTC in memory" 0 "Failure is not detected" ;
VAL_ 1173 ESpMToFailureStatus 3 "Reserved" 2 "Failure healed aging in progress" 1 "Failrue detected DTC in memory" 0 "Failure is not detected" ;
VAL_ 1173 ESpInvalidFailureStatus 3 "Reserved" 2 "Failure healed ageing in progress" 1 "fail detected and DTC  in memory" 0 "failure not detected" ;
VAL_ 1173 CCM_Invalid_Failure_Status 3 "Reserved" 2 "Failure healed Ageing in progress" 1 "Failure matured & DTC in memory" 0 "Failure is not detected" ;
VAL_ 1173 SRS_MTO_Failure_Status 3 "Reserved" 2 "Failure healed aging in progress" 1 "Failure detected DTC in Memory" 0 "Failure is not detected" ;
VAL_ 1173 EMsMToFailureStatus 3 "Historic DTC" 2 "Failurehealed Ageing in progress" 1 "Failure matured & DTC in memory" 0 "Faiulure is not detected " ;
VAL_ 1173 PDC_MTO_Failure_Status 3 "Reserved" 2 "Failure healed aging in progress" 1 "Failrue detected DTC in memory" 0 "Failure is not detected" ;
VAL_ 1173 IPcMToFailureStatus 3 "Reserved" 2 "Failure healed Ageing in progress" 1 "Failure matured & DTC in memory" 0 "Failure is not detected" ;
VAL_ 1173 IPcInvalidFailureStatus 3 "Reserved" 2 "Failure healed Ageing in progress" 1 "Failure matured & DTC in memory" 0 "Failure is not detected" ;
VAL_ 1173 PDC_Invalid_Failure_Status 3 "Reserved" 2 "Failure healed Ageing in progress" 1 "Failure matured & DTC in memory" 0 "Failure is not detected" ;
VAL_ 1173 SAS_Invalid_Failure_Status 3 "Reserved" 2 "Failure healed Ageing in progress" 1 "Failure matured & DTC in memory" 0 "Failure is not detected" ;
VAL_ 1173 SAS_MTO_Failure_Status 3 "Reserved" 2 "Failure healed aging in progress" 1 "Failure detected; DTC in memory" 0 "Failure is not detected" ;
VAL_ 1173 EPAS_MTO_Failure_Status 3 "Reserved" 2 "Failure healed aging in progress" 1 "Failrue detected DTC in mem" 0 "Failure is not detected" ;
VAL_ 1173 EPAS_Invalid_Failure_Status 3 "Reserved" 2 "Ageing in progress" 1 "fail detected and DTC memory" 0 "failure not detected" ;
VAL_ 1173 TPMS_MTO_Failure_status 3 "Reserved" 2 "Failure healed and ageing in process" 1 "Failure is detected and DTC in memory" 0 "Failure is not detected" ;
VAL_ 1173 CCM_MTO_Failure_Status 3 "Reserved" 2 "Failure healed & Ageing in progress" 1 "failure is detected & DTC in memeory" 0 "Failure is not detected" ;
VAL_ 1173 HU_EP_Failure_Status 3 "Reserved" 2 "Failurehealed Ageing in progress" 1 "Failure matured & DTC in memory" 0 "Faiulure is not detected " ;
VAL_ 1173 PEPS_MTO_Failure_Status 3 "Reserved" 2 "Failure healed aging in progress" 1 "Failure detected DTC in Memory" 0 "Failure is not detected" ;
VAL_ 1173 BCmMToFailureStatus 3 "Reserved" 2 "Failure healed aging in progress" 1 "Failure detected; DTC in memory" 0 "Failrue is not detected" ;
VAL_ 1173 HU_BO_Failure_Status 3 "Reserved" 2 "Failure healed; aging in progress" 1 "Failure detected and DTC in memory" 0 "Failure not detected" ;
VAL_ 1174 APA_MTO_Failure_status 3 "Reserved" 2 "Failure is cleared and DTC is moved to history." 1 "Failure is detected and active DTC is stored in the error memory." 0 "Failure is currently not detected." ;
VAL_ 1174 CPL_MTO_Failure_Status 3 "Reserved" 2 "Failure healed Ageing in progress" 1 "Failure matured & DTC in memory" 0 "Failure is not detected" ;
VAL_ 1174 HUD_MTO_Failure_Status 3 "Reserved" 2 "Failure Healed; aging in progress" 1 "Failure Detected; DTC in memory" 0 "Failure is not Detected" ;
VAL_ 1174 GSS_EV_MTO_Failure_Status 3 "Reserved" 2 "Failure Healed; aging in progress" 1 "Failure Detected; DTC in memory" 0 "Failure is not Detected" ;
VAL_ 1174 IM_MTO_Failure_Status 3 "Reserved" 2 "Failure healed aging in progress" 1 "Failrue detected DTC in memory" 0 "Failure is not detected" ;
VAL_ 1174 GSM_MTO_Failure_Status 3 "Reserved" 2 "Failure healed aging in progress" 1 "Failrue detected DTC in memory" 0 "Failure is not detected" ;
VAL_ 1174 SBR_MTO_Failure_Status 3 "Reserved" 2 "Failure healed aging in progress" 1 "Failure detected DTC in Memory" 0 "Failure is not detected" ;
VAL_ 1174 FCM_MRC_Failure_Status 3 "Reserved" 2 "Failurehealed Ageing in progress" 1 "Failure matured & DTC in memory" 0 "Faiulure is not detected " ;
VAL_ 1174 FCM_Invalid_Failure_Status 3 "Reserved" 2 "Failure healed ageing in progress" 1 "fail detected and DTC  in memory" 0 "failure not detected" ;
VAL_ 1174 FCM_CRC_Failure_Status 3 "Reserved" 2 "Failurehealed Ageing in progress" 1 "Failure matured & DTC in memory" 0 "Faiulure is not detected " ;
VAL_ 1174 WPC_MTO_Failure_Status 3 "Reserved" 2 "Failure healed Ageing in progress" 1 "Failure matured & DTC in memory" 0 "Failure is not detected" ;
VAL_ 1174 AVAS_MTO_Failure_status 3 "Reserved" 2 "Failure is cleared and DTC is moved to history." 1 "Failure is detected and active DTC is stored in the error memory." 0 "Failure is currently not detected." ;
VAL_ 1174 ESCL_MTO_Failure_Status 3 "Reserved" 2 "Failure healed Ageing in progress" 1 "Failure matured & DTC in memory" 0 "Failure is not detected" ;
VAL_ 1174 PEPS_Invalid_failure_status 3 "Reserved" 2 "Failure healed Ageing in progress" 1 "Failure matured & DTC in memory" 0 "Failure is not detected" ;
VAL_ 1174 BCM_Invalid_Status_Failure 3 "Reserved" 2 "Failure healed aging in progress" 1 "Failure detected DTC in memory" 0 "Failure is not detected" ;
VAL_ 1274 GlobalRealTimeGS 16777215 "Signal not available" ;
VAL_ 1274 OdoICFullSigGS 16777215 "Signal not available" ;
VAL_ 1274 BatVoltGS 255 "Signal nlot available" ;
VAL_ 1274 VehicleInteriorTempGS 255 "Signal not available" ;
VAL_ 1276 EngSpdGS 65535 "Signal not available" ;
VAL_ 1276 AccPedPosnGS 255 "Signal not available" ;
VAL_ 1276 ClntTempGS 255 "Signal not available" ;
VAL_ 1276 VehSpdGS 255 "Signal not available" ;
VAL_ 1276 OATICSigGS 255 "Signal not available" ;
VAL_ 1276 PowerModeStateGS 15 "Signal not available" 14 "Reserved" 13 "Reserved" 12 "Reserved" 11 "Tranpoer Drive Run" 10 "Transport Drive Crank" 9 "Start(Crank)" 8 "Run(Engine Run)" 7 "Transport Drive" 6 "Active(Ignition ON)" 5 "Accessory Delay" 4 "Accessory" 3 "KeyIn" 2 "Transport Park" 1 "Awake" 0 "Pre Stand By" ;
VAL_ 1276 ParkBrkStateGS 1 "Park Brake is ON" 0 "Park Brake is Off" ;
VAL_ 1280 RepeatMessageReq_BCM 1 "Repeat message state requested" 0 "Repeat message state not requested" ;
VAL_ 1280 ActiveWakeUp_BCM 1 "Node has  woken up the network(Active wakeup)" 0 "Node has not woken up the network(Passive wakeup)" ;
VAL_ 1280 CurrentState_BCM 1 "Normal Operation State" 0 "Repeat Messgae State" ;
VAL_ 1280 PreviousState_BCM 7 "Reserved" 6 "Reserved" 5 "Reserved" 4 " Bus Sleep State" 3 "Prepare Bus Sleep State" 2 "Ready Sleep State" 1 "Normal Operation State" 0 "Repeat Message State" ;
VAL_ 1282 RepeatMessageReq_HU 1 "Reserved" 0 "Repeat Message State not requested" ;
VAL_ 1282 ActiveWakeUp_HU 1 "Node has  woken up the network(Active wakeup)" 0 "Node has not woken up the network(Passive wakeup)" ;
VAL_ 1282 CurrentState_HU 1 "Normal Operation State" 0 "Repeat Messgae State" ;
VAL_ 1282 PreviousState_HU 7 "Copy of Reserved" 6 "Reserved" 5 "Reserved" 4 "Bus Sleep State" 3 "Prepare Bus Sleep State" 2 "Ready Sleep State" 1 "Normal Operation State" 0 "Repeat Message State" ;
